VERSION "Version"

NS_ :

BS_:

BU_: Tester CCU INU ADC RRR RLR CCURT1 CCURT2 ZCUF ZCUL ZCUR ZCUT EMS IDM DCDC DCDCI IPS NIDU DCU2 OBC OPC LPC CPC EMCM GCU DCU IPU BMS EOP EVCC DCDC2 EDL SRS ECS EPS EPB RBM IBCS ICM IID IDC AMP WHUD ARHUD IMR FIMR CD IFC FAPA PAS PCS SCMF SCMR SCMRL SCMRR MFS DRM FCP RCP LBMSAD AVAS DLPFL FBLCM FLISD FLLCM FRLCM RLLCMA RLLCMB RRLCMA RRLCMB RLISD DLPML DLPMR TRM PSDL PSDR FLDCM FRDCM HVSPRL HVSPRR RFR SBM WCM ETC TBOX2 TBOX RLBMS EBU FLPDM RLPDM FRPDM RRPDM FLOAR FROAR RLOAR RROAR EOSL EOSR EOST PRBU RT1_C0 OTAWL RT2_C3 IDUR PHUDD RAS CBM PLGM TMC LPC2 SAS RCICP SCMRM SCMT SLMRL SLMRR IDU RRISD DSASBM LBMS RT1_C1

BO_ 696 CCU_ZCUR_SBM_5: 64 CCU
 SG_ SBM_5_CRC : 7|16@0+ (1,0) [0|65535] ""  OTAWL,ADC,FAPA
 SG_ SBM_5_Counter : 23|8@0+ (1,0) [0|255] ""  OTAWL,ADC,FAPA
 SG_ KAE_EDK1UnlockBtnPressSt : 31|2@0+ (1,0) [0|3] ""  OTAWL,ADC,FAPA
 SG_ KAE_EDK1LockBtnPressSt : 29|2@0+ (1,0) [0|3] ""  OTAWL,ADC,FAPA
 SG_ KAE_EDK1RESBtnPressSt : 27|2@0+ (1,0) [0|3] ""  OTAWL,ADC,FAPA
 SG_ KAE_EDK1PSD_LBtnPressSt : 25|2@0+ (1,0) [0|3] ""  OTAWL,ADC,FAPA
 SG_ KAE_EDK1PSD_RBtnPressSt : 39|2@0+ (1,0) [0|3] ""  OTAWL,ADC,FAPA
 SG_ KAE_EDK1TrunkBtnPressSt : 37|2@0+ (1,0) [0|3] ""  OTAWL,ADC,FAPA
 SG_ KAE_EDK1PanicBtnPressSt : 35|2@0+ (1,0) [0|3] ""  OTAWL,ADC,FAPA
 SG_ KAE_EDK1User_definedBtnPressSt : 33|2@0+ (1,0) [0|3] ""  OTAWL,ADC,FAPA
 SG_ KAE_EDK2UnlockBtnPressSt : 47|2@0+ (1,0) [0|3] ""  OTAWL,ADC,FAPA
 SG_ KAE_EDK2LockBtnPressSt : 45|2@0+ (1,0) [0|3] ""  OTAWL,ADC,FAPA
 SG_ KAE_EDK2RESBtnPressSt : 43|2@0+ (1,0) [0|3] ""  OTAWL,ADC,FAPA
 SG_ KAE_EDK2PSD_LBtnPressSt : 41|2@0+ (1,0) [0|3] ""  OTAWL,ADC,FAPA
 SG_ KAE_EDK2PSD_RBtnPressSt : 55|2@0+ (1,0) [0|3] ""  OTAWL,ADC,FAPA
 SG_ KAE_EDK2TrunkBtnPressSt : 53|2@0+ (1,0) [0|3] ""  OTAWL,ADC,FAPA
 SG_ KAE_EDK2PanicBtnPressSt : 51|2@0+ (1,0) [0|3] ""  OTAWL,ADC,FAPA
 SG_ KAE_EDK2User_definedBtnPressSt : 49|2@0+ (1,0) [0|3] ""  OTAWL,ADC,FAPA
 SG_ KAE_EDK3UnlockBtnPressSt : 63|2@0+ (1,0) [0|3] ""  OTAWL,ADC,FAPA
 SG_ KAE_EDK3LockBtnPressSt : 61|2@0+ (1,0) [0|3] ""  OTAWL,ADC,FAPA
 SG_ KAE_EDK3RESBtnPressSt : 59|2@0+ (1,0) [0|3] ""  OTAWL,ADC,FAPA
 SG_ KAE_EDK3PSD_LBtnPressSt : 57|2@0+ (1,0) [0|3] ""  OTAWL,ADC,FAPA
 SG_ KAE_EDK3PSD_RBtnPressSt : 71|2@0+ (1,0) [0|3] ""  OTAWL,ADC,FAPA
 SG_ KAE_EDK3TrunkBtnPressSt : 69|2@0+ (1,0) [0|3] ""  OTAWL,ADC,FAPA
 SG_ KAE_EDK3PanicBtnPressSt : 67|2@0+ (1,0) [0|3] ""  OTAWL,ADC,FAPA
 SG_ KAE_EDK3User_definedBtnPressSt : 65|2@0+ (1,0) [0|3] ""  OTAWL,ADC,FAPA
 SG_ KAE_RPADirectionSel : 79|3@0+ (1,0) [0|7] ""  OTAWL,ADC,FAPA
 SG_ KAE_RPAmode : 76|2@0+ (1,0) [0|3] ""  OTAWL,ADC,FAPA
 SG_ KAE_RPADeviceSt : 74|3@0+ (1,0) [0|7] ""  OTAWL,ADC,FAPA
 SG_ KAE_PhoneBatt : 87|8@0+ (1,0) [0|100] ""  OTAWL,ADC,FAPA
 SG_ KAE_RPACheckReq : 95|1@0+ (1,0) [0|1] ""  OTAWL,ADC,FAPA
 SG_ KAE_RPAKeyPstSt : 94|2@0+ (1,0) [0|3] ""  OTAWL,ADC,FAPA
 SG_ KAE_RPADeviceFailReason : 92|4@0+ (1,0) [0|15] ""  OTAWL,ADC,FAPA
 SG_ KAE_RPABtnSt : 88|1@0+ (1,0) [0|1] ""  OTAWL,ADC,FAPA
 SG_ KAE_ForRPAFailReason : 103|4@0+ (1,0) [0|15] ""  OTAWL,ADC,FAPA
 SG_ KAE_RPABtnStVD : 99|1@0+ (1,0) [0|1] ""  OTAWL,ADC,FAPA
 SG_ KAE_RPACancelBtnSt : 98|1@0+ (1,0) [0|1] ""  OTAWL,ADC,FAPA
 SG_ KAE_RPACancelBtnStVD : 97|1@0+ (1,0) [0|1] ""  OTAWL,ADC,FAPA
 SG_ KAE_ComSDKUBouncesSt : 96|1@0+ (1,0) [0|1] ""  OTAWL,ADC,FAPA
 SG_ KAE_HAVPCancelParking : 111|1@0+ (1,0) [0|1] ""  OTAWL,ADC,FAPA
 SG_ KAE_HAVPDisclaimerAgree : 110|2@0+ (1,0) [0|3] ""  OTAWL,ADC,FAPA
 SG_ KAE_HAVPPathSelect : 108|4@0+ (1,0) [0|15] ""  OTAWL,ADC,FAPA
 SG_ KAE_RPAResponse : 119|8@0+ (1,0) [0|255] ""  OTAWL,ADC,FAPA
 SG_ KAE_HAVPUWBZone : 127|4@0+ (1,0) [0|15] ""  OTAWL,ADC,FAPA
 SG_ KAE_HAVPUWBXPosition : 123|12@0+ (1,0) [0|4095] ""  OTAWL,ADC,FAPA
 SG_ KAE_HAVPUWBYPosition : 143|12@0+ (1,0) [0|4095] ""  OTAWL,ADC,FAPA
 SG_ KAE_UnlockDoorReq : 147|1@0+ (1,0) [0|1] ""  OTAWL,ADC,FAPA
 SG_ KAE_UnlockDoorReqVD : 146|1@0+ (1,0) [0|1] ""  OTAWL,ADC,FAPA
 SG_ KAE_LockDoorReq : 145|1@0+ (1,0) [0|1] ""  OTAWL,ADC,FAPA
 SG_ KAE_LockDoorReqVD : 144|1@0+ (1,0) [0|1] ""  OTAWL,ADC,FAPA
 SG_ KAE_WindowsCloseReq : 159|1@0+ (1,0) [0|1] ""  OTAWL,ADC,FAPA
 SG_ KAE_WindowsCloseReqVD : 158|1@0+ (1,0) [0|1] ""  OTAWL,ADC,FAPA
 SG_ KAE_WindowsOpenReq : 157|1@0+ (1,0) [0|1] ""  OTAWL,ADC,FAPA
 SG_ KAE_WindowsOpenReqVD : 156|1@0+ (1,0) [0|1] ""  OTAWL,ADC,FAPA
 SG_ KAE_TrunkUnlockReq : 155|1@0+ (1,0) [0|1] ""  OTAWL,ADC,FAPA
 SG_ KAE_TrunkUnlockReqVD : 154|1@0+ (1,0) [0|1] ""  OTAWL,ADC,FAPA
 SG_ KAE_HoodUnlockReq : 153|1@0+ (1,0) [0|1] ""  OTAWL,ADC,FAPA
 SG_ KAE_HoodUnlockReqVD : 152|1@0+ (1,0) [0|1] ""  OTAWL,ADC,FAPA
 SG_ KAE_PLGMOpenReq : 167|1@0+ (1,0) [0|1] ""  OTAWL,ADC,FAPA
 SG_ KAE_PLGMOpenReqVD : 166|1@0+ (1,0) [0|1] ""  OTAWL,ADC,FAPA
 SG_ KAE_PLGMCloseReq : 165|1@0+ (1,0) [0|1] ""  OTAWL,ADC,FAPA
 SG_ KAE_PLGMCloseReqVD : 164|1@0+ (1,0) [0|1] ""  OTAWL,ADC,FAPA
 SG_ KAE_SunRoofOpenReq : 163|1@0+ (1,0) [0|1] ""  OTAWL,ADC,FAPA
 SG_ KAE_SunRoofOpenReqVD : 162|1@0+ (1,0) [0|1] ""  OTAWL,ADC,FAPA
 SG_ KAE_SunRoofCloseReq : 161|1@0+ (1,0) [0|1] ""  OTAWL,ADC,FAPA
 SG_ KAE_SunRoofCloseReqVD : 160|1@0+ (1,0) [0|1] ""  OTAWL,ADC,FAPA
 SG_ KAE_PAAReq : 287|4@0+ (1,0) [0|15] ""  OTAWL,ADC,FAPA
 SG_ KAE_PAAReqVd : 283|1@0+ (1,0) [0|1] ""  OTAWL,ADC,FAPA
 SG_ KAE_EDK1UnlockBtnSt : 282|1@0+ (1,0) [0|1] ""  OTAWL,ADC,FAPA
 SG_ KAE_EDK1LockBtnSt : 281|1@0+ (1,0) [0|1] ""  OTAWL,ADC,FAPA
 SG_ KAE_EDK1RESBtnSt : 280|1@0+ (1,0) [0|1] ""  OTAWL,ADC,FAPA
 SG_ KAE_EDK1PSD_LBtnSt : 295|1@0+ (1,0) [0|1] ""  OTAWL,ADC,FAPA
 SG_ KAE_EDK1PSD_RBtnSt : 294|1@0+ (1,0) [0|1] ""  OTAWL,ADC,FAPA
 SG_ KAE_EDK1TrunkBtnSt : 293|1@0+ (1,0) [0|1] ""  OTAWL,ADC,FAPA
 SG_ KAE_EDK1PanicBtnSt : 292|1@0+ (1,0) [0|1] ""  OTAWL,ADC,FAPA
 SG_ KAE_EDK1User_definedBtnSt : 291|1@0+ (1,0) [0|1] ""  OTAWL,ADC,FAPA
 SG_ KAE_EDK2UnlockBtnSt : 290|1@0+ (1,0) [0|1] ""  OTAWL,ADC,FAPA
 SG_ KAE_EDK2LockBtnSt : 289|1@0+ (1,0) [0|1] ""  OTAWL,ADC,FAPA
 SG_ KAE_EDK2RESBtnSt : 288|1@0+ (1,0) [0|1] ""  OTAWL,ADC,FAPA
 SG_ KAE_EDK2PSD_LBtnSt : 303|1@0+ (1,0) [0|1] ""  OTAWL,ADC,FAPA
 SG_ KAE_EDK2PSD_RBtnSt : 302|1@0+ (1,0) [0|1] ""  OTAWL,ADC,FAPA
 SG_ KAE_EDK2TrunkBtnSt : 301|1@0+ (1,0) [0|1] ""  OTAWL,ADC,FAPA
 SG_ KAE_EDK2PanicBtnSt : 300|1@0+ (1,0) [0|1] ""  OTAWL,ADC,FAPA
 SG_ KAE_EDK2User_definedBtnSt : 299|1@0+ (1,0) [0|1] ""  OTAWL,ADC,FAPA
 SG_ KAE_EDK3UnlockBtnSt : 298|1@0+ (1,0) [0|1] ""  OTAWL,ADC,FAPA
 SG_ KAE_EDK3LockBtnSt : 297|1@0+ (1,0) [0|1] ""  OTAWL,ADC,FAPA
 SG_ KAE_EDK3RESBtnSt : 296|1@0+ (1,0) [0|1] ""  OTAWL,ADC,FAPA
 SG_ KAE_EDK3PSD_LBtnSt : 311|1@0+ (1,0) [0|1] ""  OTAWL,ADC,FAPA
 SG_ KAE_EDK3PSD_RBtnSt : 310|1@0+ (1,0) [0|1] ""  OTAWL,ADC,FAPA
 SG_ KAE_EDK3TrunkBtnSt : 309|1@0+ (1,0) [0|1] ""  OTAWL,ADC,FAPA
 SG_ KAE_EDK3PanicBtnSt : 308|1@0+ (1,0) [0|1] ""  OTAWL,ADC,FAPA
 SG_ KAE_EDK3User_definedBtnSt : 316|1@0+ (1,0) [0|1] ""  OTAWL,ADC,FAPA

BO_ 1934 ADC_Diag_Tx: 64 ADC
 SG_ ADC_Diag_Response : 7|512@0+ (1,0) [0|0] ""  Vector__XXX

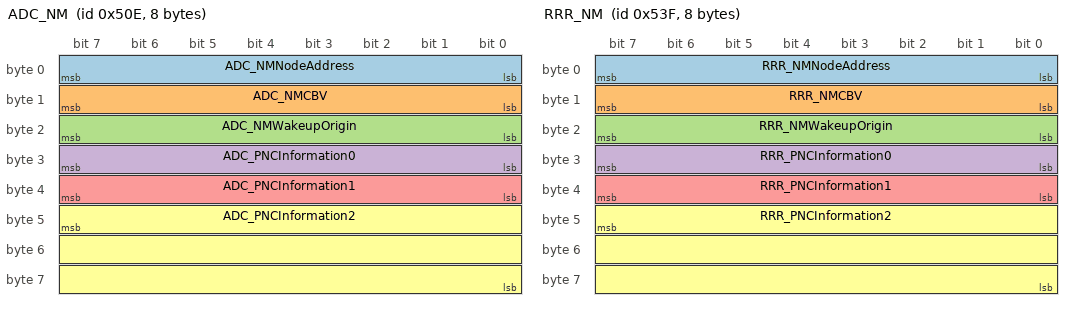
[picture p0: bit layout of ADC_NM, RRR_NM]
BO_ 1294 ADC_NM: 8 ADC
 SG_ ADC_NMNodeAddress : 7|8@0+ (1,0) [0|255] ""  CCU,CCURT1
 SG_ ADC_NMCBV : 15|8@0+ (1,0) [0|0] ""  CCU,CCURT1
 SG_ ADC_NMWakeupOrigin : 23|8@0+ (1,0) [0|255] ""  CCU,CCURT1
 SG_ ADC_PNCInformation0 : 31|8@0+ (1,0) [0|255] ""  CCU,CCURT1
 SG_ ADC_PNCInformation1 : 39|8@0+ (1,0) [0|255] ""  CCU,CCURT1
 SG_ ADC_PNCInformation2 : 47|24@0+ (1,0) [0|0] ""  CCU,CCURT1

BO_ 1343 RRR_NM: 8 RRR
 SG_ RRR_NMNodeAddress : 7|8@0+ (1,0) [0|255] ""  CCU,ADC,RLR
 SG_ RRR_NMCBV : 15|8@0+ (1,0) [0|0] ""  CCU,ADC,RLR
 SG_ RRR_NMWakeupOrigin : 23|8@0+ (1,0) [0|255] ""  CCU,ADC,RLR
 SG_ RRR_PNCInformation0 : 31|8@0+ (1,0) [0|255] ""  CCU,ADC,RLR
 SG_ RRR_PNCInformation1 : 39|8@0+ (1,0) [0|255] ""  CCU,ADC,RLR
 SG_ RRR_PNCInformation2 : 47|24@0+ (1,0) [0|0] ""  CCU,ADC,RLR

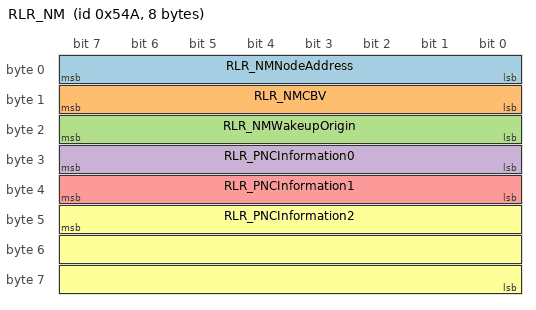
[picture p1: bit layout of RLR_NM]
BO_ 1354 RLR_NM: 8 RLR
 SG_ RLR_NMNodeAddress : 7|8@0+ (1,0) [0|255] ""  CCU,ADC,RRR
 SG_ RLR_NMCBV : 15|8@0+ (1,0) [0|0] ""  CCU,ADC,RRR
 SG_ RLR_NMWakeupOrigin : 23|8@0+ (1,0) [0|255] ""  CCU,ADC,RRR
 SG_ RLR_PNCInformation0 : 31|8@0+ (1,0) [0|255] ""  CCU,ADC,RRR
 SG_ RLR_PNCInformation1 : 39|8@0+ (1,0) [0|255] ""  CCU,ADC,RRR
 SG_ RLR_PNCInformation2 : 47|24@0+ (1,0) [0|0] ""  CCU,ADC,RRR

BO_ 932 RRR_1: 32 RRR
 SG_ RRR_1_CRC : 7|16@0+ (1,0) [0|65535] ""  ADC,IFC,FAPA
 SG_ RRR_1_Counter : 23|8@0+ (1,0) [0|255] ""  ADC,IFC,FAPA
 SG_ RRR_MRRSt : 31|3@0+ (1,0) [0|7] ""  ADC,IFC,FAPA
 SG_ RRR_ExMirLedWarnR : 28|2@0+ (1,0) [0|3] ""  ADC,IFC,FAPA
 SG_ RRR_LCASt : 26|2@0+ (1,0) [0|3] ""  ADC,IFC,FAPA
 SG_ RRR_LCAWarnRight : 24|2@0+ (1,0) [0|3] ""  ADC,IFC,FAPA
 SG_ RRR_ClusterLamp : 38|3@0+ (1,0) [0|7] ""  ADC,IFC,FAPA
 SG_ RRR_DOWWarnR : 35|2@0+ (1,0) [0|3] ""  ADC,IFC,FAPA
 SG_ RRR_DOWSt : 33|2@0+ (1,0) [0|3] ""  ADC,IFC,FAPA
 SG_ RRR_AudioWarnFR : 41|2@0+ (1,0) [0|3] ""  ADC,IFC,FAPA
 SG_ RRR_AudioWarnRR : 43|2@0+ (1,0) [0|3] ""  ADC,IFC,FAPA
 SG_ RRR_IALWarnFR : 45|2@0+ (1,0) [0|3] ""  ADC,IFC,FAPA
 SG_ RRR_IALWarnRR : 47|2@0+ (1,0) [0|3] ""  ADC,IFC,FAPA
 SG_ RRR_RCTASt : 49|2@0+ (1,0) [0|3] ""  ADC,IFC,FAPA
 SG_ RRR_RCTAWarnRight : 51|2@0+ (1,0) [0|3] ""  ADC,IFC,FAPA
 SG_ RRR_RCWSt : 53|2@0+ (1,0) [0|3] ""  ADC,IFC,FAPA
 SG_ RRR_RCWWarn : 55|2@0+ (1,0) [0|3] ""  ADC,IFC,FAPA
 SG_ RRR_RCTBTargetDecel : 63|8@0+ (0.05,-10) [-10|2.75] "m/s2"  ADC,IFC,FAPA
 SG_ RRR_RCTBBrkReq : 64|1@0+ (1,0) [0|1] ""  ADC,IFC,FAPA
 SG_ RRR_TargetLatDistR : 71|7@0+ (0.1,-12.7) [-12.7|0] ""  ADC,IFC,FAPA
 SG_ RRR_TargetRelSpdR : 79|10@0+ (0.06225,-10) [-10|50] "m/s"  ADC,IFC,FAPA
 SG_ RRR_RCTBBrkgVD : 83|1@0+ (1,0) [0|1] ""  ADC,IFC,FAPA
 SG_ RRR_TargetRVD : 85|2@0+ (1,0) [0|3] ""  ADC,IFC,FAPA
 SG_ RRR_TargetDstR : 82|11@0+ (0.06225,-90) [-90|10] "m"  ADC,IFC,FAPA
 SG_ RRR_RCTAAssistType : 103|2@0+ (1,0) [0|3] ""  ADC,IFC,FAPA

BO_ 987 RLR_1: 32 RLR
 SG_ RLR_1_CRC : 7|16@0+ (1,0) [0|65535] ""  ADC,IFC,FAPA
 SG_ RLR_1_Counter : 23|8@0+ (1,0) [0|255] ""  ADC,IFC,FAPA
 SG_ RLR_MRRSt : 31|3@0+ (1,0) [0|7] ""  ADC,IFC,FAPA
 SG_ RLR_ExMirLedWarnL : 28|2@0+ (1,0) [0|3] ""  ADC,IFC,FAPA
 SG_ RLR_LCASt : 26|2@0+ (1,0) [0|3] ""  ADC,IFC,FAPA
 SG_ RLR_LCAWarnLeft : 24|2@0+ (1,0) [0|3] ""  ADC,IFC,FAPA
 SG_ RLR_ClusterLamp : 38|3@0+ (1,0) [0|7] ""  ADC,IFC,FAPA
 SG_ RLR_DOWWarnL : 35|2@0+ (1,0) [0|3] ""  ADC,IFC,FAPA
 SG_ RLR_DOWSt : 33|2@0+ (1,0) [0|3] ""  ADC,IFC,FAPA
 SG_ RLR_AudioWarnFL : 41|2@0+ (1,0) [0|3] ""  ADC,IFC,FAPA
 SG_ RLR_AudioWarnRL : 43|2@0+ (1,0) [0|3] ""  ADC,IFC,FAPA
 SG_ RLR_IALWarnFL : 45|2@0+ (1,0) [0|3] ""  ADC,IFC,FAPA
 SG_ RLR_IALWarnRL : 47|2@0+ (1,0) [0|3] ""  ADC,IFC,FAPA
 SG_ RLR_RCTAWarnLeft : 49|2@0+ (1,0) [0|3] ""  ADC,IFC,FAPA
 SG_ RLR_RCWSt : 51|2@0+ (1,0) [0|3] ""  ADC,IFC,FAPA
 SG_ RLR_RCWWarn : 53|2@0+ (1,0) [0|3] ""  ADC,IFC,FAPA,RRR
 SG_ RLR_TargetLVD : 55|2@0+ (1,0) [0|3] ""  ADC,IFC,FAPA
 SG_ RLR_TargetRelSpdL : 63|10@0+ (0.06225,-10) [-10|50] "m/s"  ADC,IFC,FAPA
 SG_ RLR_TargetDstL : 69|11@0+ (0.06225,-90) [-90|10] "m"  ADC,IFC,FAPA
 SG_ RLR_TargetLatDistL : 74|7@0+ (0.1,0) [0|12.7] "m"  ADC,IFC,FAPA
 SG_ RLR_RCTASt : 83|2@0+ (1,0) [0|3] ""  ADC,IFC,FAPA
 SG_ RLR_RCTAAssistType : 81|2@0+ (1,0) [0|3] ""  ADC,IFC,FAPA,RRR

CM_ SG_ 696 SBM_5_CRC "E2E Profile 5 CRC";
CM_ SG_ 696 SBM_5_Counter "E2E Profile 5 Counter";
CM_ SG_ 696 KAE_EDK1UnlockBtnPressSt "EDK Unlock Button Pressed Status";
CM_ SG_ 696 KAE_EDK1LockBtnPressSt "EDK Lock Button Pressed Status";
CM_ SG_ 696 KAE_EDK1RESBtnPressSt "EDK RES Button Status";
CM_ SG_ 696 KAE_EDK1PSD_LBtnPressSt "EDK PSD_L Button Status";
CM_ SG_ 696 KAE_EDK1PSD_RBtnPressSt "EDK PSD_R Button Status";
CM_ SG_ 696 KAE_EDK1TrunkBtnPressSt "EDK Trunk Button Status";
CM_ SG_ 696 KAE_EDK1PanicBtnPressSt "EDK Panic Button Status";
CM_ SG_ 696 KAE_EDK1User_definedBtnPressSt "EDK User_defined Button Status";
CM_ SG_ 696 KAE_EDK2UnlockBtnPressSt "EDK Unlock Button Pressed Status";
CM_ SG_ 696 KAE_EDK2LockBtnPressSt "EDK Lock Button Pressed Status";
CM_ SG_ 696 KAE_EDK2RESBtnPressSt "EDK RES Button Status";
CM_ SG_ 696 KAE_EDK2PSD_LBtnPressSt "EDK PSD_L Button Status";
CM_ SG_ 696 KAE_EDK2PSD_RBtnPressSt "EDK PSD_R Button Status";
CM_ SG_ 696 KAE_EDK2TrunkBtnPressSt "EDK Trunk Button Status";
CM_ SG_ 696 KAE_EDK2PanicBtnPressSt "EDK Panic Button Status";
CM_ SG_ 696 KAE_EDK2User_definedBtnPressSt "EDK User_defined Button Status";
CM_ SG_ 696 KAE_EDK3UnlockBtnPressSt "EDK Unlock Button Pressed Status";
CM_ SG_ 696 KAE_EDK3LockBtnPressSt "EDK Lock Button Pressed Status";
CM_ SG_ 696 KAE_EDK3RESBtnPressSt "EDK RES Button Status";
CM_ SG_ 696 KAE_EDK3PSD_LBtnPressSt "EDK PSD_L Button Status";
CM_ SG_ 696 KAE_EDK3PSD_RBtnPressSt "EDK PSD_R Button Status";
CM_ SG_ 696 KAE_EDK3TrunkBtnPressSt "EDK Trunk Button Status";
CM_ SG_ 696 KAE_EDK3PanicBtnPressSt "EDK Panic Button Status";
CM_ SG_ 696 KAE_EDK3User_definedBtnPressSt "EDK User_defined Button Status";
CM_ SG_ 696 KAE_RPADirectionSel "RPA Direction Selection";
CM_ SG_ 696 KAE_RPAmode "SBM RPA mode";
CM_ SG_ 696 KAE_RPADeviceSt "RPA Device Status";
CM_ SG_ 696 KAE_PhoneBatt "SBM Phone batt";
CM_ SG_ 696 KAE_RPACheckReq "SBM RPA Checking Req";
CM_ SG_ 696 KAE_RPAKeyPstSt "RPA Key Position Status";
CM_ SG_ 696 KAE_RPADeviceFailReason "RPA Device Failure Reason";
CM_ SG_ 696 KAE_RPABtnSt "RPA Button Status";
CM_ SG_ 696 KAE_ForRPAFailReason "RPA and SBM failure reason";
CM_ SG_ 696 KAE_RPABtnStVD "RPA Button Status valid value";
CM_ SG_ 696 KAE_RPACancelBtnSt "RPA Cancal Button Status";
CM_ SG_ 696 KAE_RPACancelBtnStVD "RPA Button Statusvalid valid value";
CM_ SG_ 696 KAE_ComSDKUBouncesSt "Communication status between SBM and SDK,This signal bounces every time the SDK updates the data";
CM_ SG_ 696 KAE_HAVPCancelParking "HAVP User cancellation SBM";
CM_ SG_ 696 KAE_HAVPDisclaimerAgree "App HAVP Disclaimer confirm";
CM_ SG_ 696 KAE_HAVPPathSelect "HAVP User path selection SBM";
CM_ SG_ 696 KAE_RPAResponse "SBM Response RPA Challenge  Singal";
CM_ SG_ 696 KAE_HAVPUWBZone "SBM UWB HAVP Zone";
CM_ SG_ 696 KAE_HAVPUWBXPosition "SBM UWB HAVP X Position";
CM_ SG_ 696 KAE_HAVPUWBYPosition "SBM UWB HAVP Y Position";
CM_ SG_ 696 KAE_UnlockDoorReq "Virtual Key APP Unlock door request";
CM_ SG_ 696 KAE_UnlockDoorReqVD "KAE_UnlockDoorReq valid value";
CM_ SG_ 696 KAE_LockDoorReq "Virtual Key APP Lock door request";
CM_ SG_ 696 KAE_LockDoorReqVD "KAE_LockDoorReq valid value";
CM_ SG_ 696 KAE_WindowsCloseReq "Virtual Key APP close the windows request";
CM_ SG_ 696 KAE_WindowsCloseReqVD "KAE_WindowsCloseReq valid value";
CM_ SG_ 696 KAE_WindowsOpenReq "Virtual Key APP open the windows request";
CM_ SG_ 696 KAE_WindowsOpenReqVD "KAE_WindowsOpenReq valid value";
CM_ SG_ 696 KAE_TrunkUnlockReq "Virtual Key APP request unlock the trunck";
CM_ SG_ 696 KAE_TrunkUnlockReqVD "KAE_TrunkUnlockReq valid value";
CM_ SG_ 696 KAE_HoodUnlockReq "Virtual Key APP request unlock the hood";
CM_ SG_ 696 KAE_HoodUnlockReqVD "KAE_HoodeUnlockReq valid value";
CM_ SG_ 696 KAE_PLGMOpenReq "Virtual Key APP PLGM(Power Liftgate Module) open request";
CM_ SG_ 696 KAE_PLGMOpenReqVD "KAE_PLGMOpenReq valid value";
CM_ SG_ 696 KAE_PLGMCloseReq "Virtual Key APP PLGM(Power Liftgate Module) close request";
CM_ SG_ 696 KAE_PLGMCloseReqVD "KAE_PLGMCloseReq valid value";
CM_ SG_ 696 KAE_SunRoofOpenReq "Virtual Key APP sun roof open request";
CM_ SG_ 696 KAE_SunRoofOpenReqVD "KAE_SunRoofOpenReq valid value";
CM_ SG_ 696 KAE_SunRoofCloseReq "Virtual Key APP sun roof close request";
CM_ SG_ 696 KAE_SunRoofCloseReqVD "KAE_SunRoofCloseReq valid value";
CM_ SG_ 696 KAE_PAAReq "KAE PAA request";
CM_ SG_ 696 KAE_PAAReqVd "KAE_PAA Req valid value";
CM_ SG_ 696 KAE_EDK1UnlockBtnSt "EDK1 Unlock Button current Status";
CM_ SG_ 696 KAE_EDK1LockBtnSt "EDK1 Lock Button current Status";
CM_ SG_ 696 KAE_EDK1RESBtnSt "EDK1 RES Button  current Status";
CM_ SG_ 696 KAE_EDK1PSD_LBtnSt "EDK1 PSD_L Button current Status";
CM_ SG_ 696 KAE_EDK1PSD_RBtnSt "EDK1 PSD_R Button current Status";
CM_ SG_ 696 KAE_EDK1TrunkBtnSt "EDK1 Trunk Button current Status";
CM_ SG_ 696 KAE_EDK1PanicBtnSt "EDK1 Panic Button current Status";
CM_ SG_ 696 KAE_EDK1User_definedBtnSt "EDK1 User_defined Button current Status";
CM_ SG_ 696 KAE_EDK2UnlockBtnSt "EDK2 Unlock Button current Status";
CM_ SG_ 696 KAE_EDK2LockBtnSt "EDK2 Lock Button current Status";
CM_ SG_ 696 KAE_EDK2RESBtnSt "EDK2 RES Button  current Status";
CM_ SG_ 696 KAE_EDK2PSD_LBtnSt "EDK2 PSD_L Button current Status";
CM_ SG_ 696 KAE_EDK2PSD_RBtnSt "EDK2 PSD_R Button current Status";
CM_ SG_ 696 KAE_EDK2TrunkBtnSt "EDK2 Trunk Button current Status";
CM_ SG_ 696 KAE_EDK2PanicBtnSt "EDK2 Panic Button current Status";
CM_ SG_ 696 KAE_EDK2User_definedBtnSt "EDK2 User_defined Button current Status";
CM_ SG_ 696 KAE_EDK3UnlockBtnSt "EDK3 Unlock Button current Status";
CM_ SG_ 696 KAE_EDK3LockBtnSt "EDK3 Lock Button current Status";
CM_ SG_ 696 KAE_EDK3RESBtnSt "EDK3 RES Button  current Status";
CM_ SG_ 696 KAE_EDK3PSD_LBtnSt "EDK3 PSD_L Button current Status";
CM_ SG_ 696 KAE_EDK3PSD_RBtnSt "EDK3 PSD_R Button current Status";
CM_ SG_ 696 KAE_EDK3TrunkBtnSt "EDK3 Trunk Button current Status";
CM_ SG_ 696 KAE_EDK3PanicBtnSt "EDK3 Panic Button current Status";
CM_ SG_ 696 KAE_EDK3User_definedBtnSt "EDK3 User_defined Button current Status";
CM_ SG_ 1934 ADC_Diag_Response "ADC diagnostic response";
CM_ SG_ 1294 ADC_NMNodeAddress "ADC node address";
CM_ SG_ 1294 ADC_NMCBV "ADC Network management control bit vector";
CM_ SG_ 1294 ADC_NMWakeupOrigin "Origin of the wake up";
CM_ SG_ 1294 ADC_PNCInformation0 "PNC Information";
CM_ SG_ 1294 ADC_PNCInformation1 "PNC Information";
CM_ SG_ 1294 ADC_PNCInformation2 "PNC Information";
CM_ SG_ 1343 RRR_NMNodeAddress "RRR node address";
CM_ SG_ 1343 RRR_NMCBV "RRR Network management control bit vector";
CM_ SG_ 1343 RRR_NMWakeupOrigin "Origin of the wake up";
CM_ SG_ 1343 RRR_PNCInformation0 "PNC Information";
CM_ SG_ 1343 RRR_PNCInformation1 "PNC Information";
CM_ SG_ 1343 RRR_PNCInformation2 "PNC Information";
CM_ SG_ 1354 RLR_NMNodeAddress "RLR node address";
CM_ SG_ 1354 RLR_NMCBV "RLR Network management control bit vector";
CM_ SG_ 1354 RLR_NMWakeupOrigin "Origin of the wake up";
CM_ SG_ 1354 RLR_PNCInformation0 "PNC Information";
CM_ SG_ 1354 RLR_PNCInformation1 "PNC Information";
CM_ SG_ 1354 RLR_PNCInformation2 "PNC Information";
CM_ SG_ 932 RRR_1_CRC "E2E Profile 5 CRC";
CM_ SG_ 932 RRR_1_Counter "E2E Profile 5 Counter";
CM_ SG_ 932 RRR_MRRSt "MRR systems ON OFF andError Status";
CM_ SG_ 932 RRR_ExMirLedWarnR "Exterior mirror LED warning right";
CM_ SG_ 932 RRR_LCASt "BSD-LCA Function status";
CM_ SG_ 932 RRR_LCAWarnRight " the vehicle right warning level in the LCA feature";
CM_ SG_ 932 RRR_ClusterLamp "Cluster lamp color status";
CM_ SG_ 932 RRR_DOWWarnR "DOW warning right";
CM_ SG_ 932 RRR_DOWSt "DOW function state  right";
CM_ SG_ 932 RRR_AudioWarnFR "Front right door speaker warning";
CM_ SG_ 932 RRR_AudioWarnRR "Rear right door speaker warning";
CM_ SG_ 932 RRR_IALWarnFR "Front right door light warning";
CM_ SG_ 932 RRR_IALWarnRR "Rear right door light warning";
CM_ SG_ 932 RRR_RCTASt "RCTA Function status";
CM_ SG_ 932 RRR_RCTAWarnRight "the vehicle right warning in the RCTAfeature";
CM_ SG_ 932 RRR_RCWSt "RCW(rear collision warning ) feature status";
CM_ SG_ 932 RRR_RCWWarn "the vehicle warning level in the RCWfeature";
CM_ SG_ 932 RRR_RCTBTargetDecel "target deceleration value from RCTB";
CM_ SG_ 932 RRR_RCTBBrkReq "RCTB brake request";
CM_ SG_ 932 RRR_TargetLatDistR "ELK right target lateral relative distance";
CM_ SG_ 932 RRR_TargetRelSpdR "ELK right target relative speed";
CM_ SG_ 932 RRR_RCTBBrkgVD "RCTB brake request valid flag";
CM_ SG_ 932 RRR_TargetRVD "ELK right target valid state";
CM_ SG_ 932 RRR_TargetDstR "ELK right target relative distance";
CM_ SG_ 932 RRR_RCTAAssistType "RCTA assist type request";
CM_ SG_ 987 RLR_1_CRC "E2E Profile 5 CRC";
CM_ SG_ 987 RLR_1_Counter "E2E Profile 5 Counter";
CM_ SG_ 987 RLR_MRRSt "MRR systems ON OFF andError Status";
CM_ SG_ 987 RLR_ExMirLedWarnL "Exterior mirror LED warning left";
CM_ SG_ 987 RLR_LCASt "BSD-LCA Function status";
CM_ SG_ 987 RLR_LCAWarnLeft " the vehicle Left warning level in the LCA feature";
CM_ SG_ 987 RLR_ClusterLamp "Cluster lamp color status";
CM_ SG_ 987 RLR_DOWWarnL "DOW warning left";
CM_ SG_ 987 RLR_DOWSt "DOW function state left";
CM_ SG_ 987 RLR_AudioWarnFL "Front left door speaker warning";
CM_ SG_ 987 RLR_AudioWarnRL "Rear left door speaker warning";
CM_ SG_ 987 RLR_IALWarnFL "Front left door light warning";
CM_ SG_ 987 RLR_IALWarnRL "Rear left door light warning";
CM_ SG_ 987 RLR_RCTAWarnLeft "the vehicle left warning in the RCTAfeature";
CM_ SG_ 987 RLR_RCWSt "RCW(rear collision warning ) feature status";
CM_ SG_ 987 RLR_RCWWarn "the vehicle warning level in the RCWfeature";
CM_ SG_ 987 RLR_TargetLVD "ELK left target valid state";
CM_ SG_ 987 RLR_TargetRelSpdL "ELK left target relative speed";
CM_ SG_ 987 RLR_TargetDstL "ELK left target relative distance";
CM_ SG_ 987 RLR_TargetLatDistL "ELK left target lateral relative distance ";
CM_ SG_ 987 RLR_RCTASt "RCTA Function status left";
CM_ SG_ 987 RLR_RCTAAssistType "RCTA assist type request";

BA_DEF_ BO_  "GenMsgCycleTime" INT 0 0;
BA_DEF_ BO_  "GenMsgCycleTimeFast" INT 0 0;
BA_DEF_ BO_  "GenMsgSendType" ENUM  "Periodic","Event","IfActive","POE","PA","FixedPeriodic","Event","EnabledPeriodic","NotUsed","NotUsed","EventPeriodic","NotUsed","NotUsed","NoMsgSendType";
BA_DEF_ BO_  "VFrameFormat" ENUM  "StandardCAN","ExtendedCAN","reserved","reserved","reserved","reserved","reserved","reserved","reserved","reserved","reserved","reserved","reserved","reserved","StandardCAN_FD","ExtendedCAN_FD";
BA_DEF_ BO_  "CANFD_BRS" ENUM  "0","1";
BA_DEF_ SG_  "EventCommandSignal" ENUM  "No","Yes";
BA_DEF_ SG_  "GatewayedSignals" ENUM  "No","Yes";
BA_DEF_ SG_  "GenSigInactiveValue" HEX 0 0;
BA_DEF_ SG_  "GenSigInvalidValue" HEX 0 0;
BA_DEF_ SG_  "GenSigSendType" ENUM  "Trigger","Passive","Cyclic","OnWrite","OnWriteWithRepetition","OnChange","OnChangeWithRepetition","IfActive","IfActiveWithRepetition","NoSigSendType";
BA_DEF_ SG_  "GenSigStartValue" HEX 0 0;
BA_DEF_ SG_  "GenSigTimeoutValue" HEX 0 0;
BA_DEF_ SG_  "Remark" STRING ;
BA_ "GenMsgCycleTime" BO_ 696 40;
BA_ "GenMsgCycleTimeFast" BO_ 696 0;
BA_ "GenMsgSendType" BO_ 696 0;
BA_ "VFrameFormat" BO_ 696 14;
BA_ "CANFD_BRS" BO_ 696 1;
BA_ "GenMsgCycleTime" BO_ 696 40;
BA_ "GenMsgCycleTimeFast" BO_ 696 0;
BA_ "GenMsgSendType" BO_ 696 0;
BA_ "VFrameFormat" BO_ 696 14;
BA_ "CANFD_BRS" BO_ 696 1;
BA_ "GenMsgCycleTime" BO_ 696 40;
BA_ "GenMsgCycleTimeFast" BO_ 696 0;
BA_ "GenMsgSendType" BO_ 696 0;
BA_ "VFrameFormat" BO_ 696 14;
BA_ "CANFD_BRS" BO_ 696 1;
BA_ "GenMsgCycleTime" BO_ 696 40;
BA_ "GenMsgCycleTimeFast" BO_ 696 0;
BA_ "GenMsgSendType" BO_ 696 0;
BA_ "VFrameFormat" BO_ 696 14;
BA_ "CANFD_BRS" BO_ 696 1;
BA_ "GenMsgCycleTime" BO_ 696 40;
BA_ "GenMsgCycleTimeFast" BO_ 696 0;
BA_ "GenMsgSendType" BO_ 696 0;
BA_ "VFrameFormat" BO_ 696 14;
BA_ "CANFD_BRS" BO_ 696 1;
BA_ "GenMsgCycleTime" BO_ 696 40;
BA_ "GenMsgCycleTimeFast" BO_ 696 0;
BA_ "GenMsgSendType" BO_ 696 0;
BA_ "VFrameFormat" BO_ 696 14;
BA_ "CANFD_BRS" BO_ 696 1;
BA_ "GenMsgCycleTime" BO_ 696 40;
BA_ "GenMsgCycleTimeFast" BO_ 696 0;
BA_ "GenMsgSendType" BO_ 696 0;
BA_ "VFrameFormat" BO_ 696 14;
BA_ "CANFD_BRS" BO_ 696 1;
BA_ "GenMsgCycleTime" BO_ 696 40;
BA_ "GenMsgCycleTimeFast" BO_ 696 0;
BA_ "GenMsgSendType" BO_ 696 0;
BA_ "VFrameFormat" BO_ 696 14;
BA_ "CANFD_BRS" BO_ 696 1;
BA_ "GenMsgCycleTime" BO_ 696 40;
BA_ "GenMsgCycleTimeFast" BO_ 696 0;
BA_ "GenMsgSendType" BO_ 696 0;
BA_ "VFrameFormat" BO_ 696 14;
BA_ "CANFD_BRS" BO_ 696 1;
BA_ "GenMsgCycleTime" BO_ 696 40;
BA_ "GenMsgCycleTimeFast" BO_ 696 0;
BA_ "GenMsgSendType" BO_ 696 0;
BA_ "VFrameFormat" BO_ 696 14;
BA_ "CANFD_BRS" BO_ 696 1;
BA_ "GenMsgCycleTime" BO_ 696 40;
BA_ "GenMsgCycleTimeFast" BO_ 696 0;
BA_ "GenMsgSendType" BO_ 696 0;
BA_ "VFrameFormat" BO_ 696 14;
BA_ "CANFD_BRS" BO_ 696 1;
BA_ "GenMsgCycleTime" BO_ 696 40;
BA_ "GenMsgCycleTimeFast" BO_ 696 0;
BA_ "GenMsgSendType" BO_ 696 0;
BA_ "VFrameFormat" BO_ 696 14;
BA_ "CANFD_BRS" BO_ 696 1;
BA_ "GenMsgCycleTime" BO_ 696 40;
BA_ "GenMsgCycleTimeFast" BO_ 696 0;
BA_ "GenMsgSendType" BO_ 696 0;
BA_ "VFrameFormat" BO_ 696 14;
BA_ "CANFD_BRS" BO_ 696 1;
BA_ "GenMsgCycleTime" BO_ 696 40;
BA_ "GenMsgCycleTimeFast" BO_ 696 0;
BA_ "GenMsgSendType" BO_ 696 0;
BA_ "VFrameFormat" BO_ 696 14;
BA_ "CANFD_BRS" BO_ 696 1;
BA_ "GenMsgCycleTime" BO_ 696 40;
BA_ "GenMsgCycleTimeFast" BO_ 696 0;
BA_ "GenMsgSendType" BO_ 696 0;
BA_ "VFrameFormat" BO_ 696 14;
BA_ "CANFD_BRS" BO_ 696 1;
BA_ "GenMsgCycleTime" BO_ 696 40;
BA_ "GenMsgCycleTimeFast" BO_ 696 0;
BA_ "GenMsgSendType" BO_ 696 0;
BA_ "VFrameFormat" BO_ 696 14;
BA_ "CANFD_BRS" BO_ 696 1;
BA_ "GenMsgCycleTime" BO_ 696 40;
BA_ "GenMsgCycleTimeFast" BO_ 696 0;
BA_ "GenMsgSendType" BO_ 696 0;
BA_ "VFrameFormat" BO_ 696 14;
BA_ "CANFD_BRS" BO_ 696 1;
BA_ "GenMsgCycleTime" BO_ 696 40;
BA_ "GenMsgCycleTimeFast" BO_ 696 0;
BA_ "GenMsgSendType" BO_ 696 0;
BA_ "VFrameFormat" BO_ 696 14;
BA_ "CANFD_BRS" BO_ 696 1;
BA_ "GenMsgCycleTime" BO_ 696 40;
BA_ "GenMsgCycleTimeFast" BO_ 696 0;
BA_ "GenMsgSendType" BO_ 696 0;
BA_ "VFrameFormat" BO_ 696 14;
BA_ "CANFD_BRS" BO_ 696 1;
BA_ "GenMsgCycleTime" BO_ 696 40;
BA_ "GenMsgCycleTimeFast" BO_ 696 0;
BA_ "GenMsgSendType" BO_ 696 0;
BA_ "VFrameFormat" BO_ 696 14;
BA_ "CANFD_BRS" BO_ 696 1;
BA_ "GenMsgCycleTime" BO_ 696 40;
BA_ "GenMsgCycleTimeFast" BO_ 696 0;
BA_ "GenMsgSendType" BO_ 696 0;
BA_ "VFrameFormat" BO_ 696 14;
BA_ "CANFD_BRS" BO_ 696 1;
BA_ "GenMsgCycleTime" BO_ 696 40;
BA_ "GenMsgCycleTimeFast" BO_ 696 0;
BA_ "GenMsgSendType" BO_ 696 0;
BA_ "VFrameFormat" BO_ 696 14;
BA_ "CANFD_BRS" BO_ 696 1;
BA_ "GenMsgCycleTime" BO_ 696 40;
BA_ "GenMsgCycleTimeFast" BO_ 696 0;
BA_ "GenMsgSendType" BO_ 696 0;
BA_ "VFrameFormat" BO_ 696 14;
BA_ "CANFD_BRS" BO_ 696 1;
BA_ "GenMsgCycleTime" BO_ 696 40;
BA_ "GenMsgCycleTimeFast" BO_ 696 0;
BA_ "GenMsgSendType" BO_ 696 0;
BA_ "VFrameFormat" BO_ 696 14;
BA_ "CANFD_BRS" BO_ 696 1;
BA_ "GenMsgCycleTime" BO_ 696 40;
BA_ "GenMsgCycleTimeFast" BO_ 696 0;
BA_ "GenMsgSendType" BO_ 696 0;
BA_ "VFrameFormat" BO_ 696 14;
BA_ "CANFD_BRS" BO_ 696 1;
BA_ "GenMsgCycleTime" BO_ 696 40;
BA_ "GenMsgCycleTimeFast" BO_ 696 0;
BA_ "GenMsgSendType" BO_ 696 0;
BA_ "VFrameFormat" BO_ 696 14;
BA_ "CANFD_BRS" BO_ 696 1;
BA_ "GenMsgCycleTime" BO_ 696 40;
BA_ "GenMsgCycleTimeFast" BO_ 696 0;
BA_ "GenMsgSendType" BO_ 696 0;
BA_ "VFrameFormat" BO_ 696 14;
BA_ "CANFD_BRS" BO_ 696 1;
BA_ "GenMsgCycleTime" BO_ 696 40;
BA_ "GenMsgCycleTimeFast" BO_ 696 0;
BA_ "GenMsgSendType" BO_ 696 0;
BA_ "VFrameFormat" BO_ 696 14;
BA_ "CANFD_BRS" BO_ 696 1;
BA_ "GenMsgCycleTime" BO_ 696 40;
BA_ "GenMsgCycleTimeFast" BO_ 696 0;
BA_ "GenMsgSendType" BO_ 696 0;
BA_ "VFrameFormat" BO_ 696 14;
BA_ "CANFD_BRS" BO_ 696 1;
BA_ "GenMsgCycleTime" BO_ 696 40;
BA_ "GenMsgCycleTimeFast" BO_ 696 0;
BA_ "GenMsgSendType" BO_ 696 0;
BA_ "VFrameFormat" BO_ 696 14;
BA_ "CANFD_BRS" BO_ 696 1;
BA_ "GenMsgCycleTime" BO_ 696 40;
BA_ "GenMsgCycleTimeFast" BO_ 696 0;
BA_ "GenMsgSendType" BO_ 696 0;
BA_ "VFrameFormat" BO_ 696 14;
BA_ "CANFD_BRS" BO_ 696 1;
BA_ "GenMsgCycleTime" BO_ 696 40;
BA_ "GenMsgCycleTimeFast" BO_ 696 0;
BA_ "GenMsgSendType" BO_ 696 0;
BA_ "VFrameFormat" BO_ 696 14;
BA_ "CANFD_BRS" BO_ 696 1;
BA_ "GenMsgCycleTime" BO_ 696 40;
BA_ "GenMsgCycleTimeFast" BO_ 696 0;
BA_ "GenMsgSendType" BO_ 696 0;
BA_ "VFrameFormat" BO_ 696 14;
BA_ "CANFD_BRS" BO_ 696 1;
BA_ "GenMsgCycleTime" BO_ 696 40;
BA_ "GenMsgCycleTimeFast" BO_ 696 0;
BA_ "GenMsgSendType" BO_ 696 0;
BA_ "VFrameFormat" BO_ 696 14;
BA_ "CANFD_BRS" BO_ 696 1;
BA_ "GenMsgCycleTime" BO_ 696 40;
BA_ "GenMsgCycleTimeFast" BO_ 696 0;
BA_ "GenMsgSendType" BO_ 696 0;
BA_ "VFrameFormat" BO_ 696 14;
BA_ "CANFD_BRS" BO_ 696 1;
BA_ "GenMsgCycleTime" BO_ 696 40;
BA_ "GenMsgCycleTimeFast" BO_ 696 0;
BA_ "GenMsgSendType" BO_ 696 0;
BA_ "VFrameFormat" BO_ 696 14;
BA_ "CANFD_BRS" BO_ 696 1;
BA_ "GenMsgCycleTime" BO_ 696 40;
BA_ "GenMsgCycleTimeFast" BO_ 696 0;
BA_ "GenMsgSendType" BO_ 696 0;
BA_ "VFrameFormat" BO_ 696 14;
BA_ "CANFD_BRS" BO_ 696 1;
BA_ "GenMsgCycleTime" BO_ 696 40;
BA_ "GenMsgCycleTimeFast" BO_ 696 0;
BA_ "GenMsgSendType" BO_ 696 0;
BA_ "VFrameFormat" BO_ 696 14;
BA_ "CANFD_BRS" BO_ 696 1;
BA_ "GenMsgCycleTime" BO_ 696 40;
BA_ "GenMsgCycleTimeFast" BO_ 696 0;
BA_ "GenMsgSendType" BO_ 696 0;
BA_ "VFrameFormat" BO_ 696 14;
BA_ "CANFD_BRS" BO_ 696 1;
BA_ "GenMsgCycleTime" BO_ 696 40;
BA_ "GenMsgCycleTimeFast" BO_ 696 0;
BA_ "GenMsgSendType" BO_ 696 0;
BA_ "VFrameFormat" BO_ 696 14;
BA_ "CANFD_BRS" BO_ 696 1;
BA_ "GenMsgCycleTime" BO_ 696 40;
BA_ "GenMsgCycleTimeFast" BO_ 696 0;
BA_ "GenMsgSendType" BO_ 696 0;
BA_ "VFrameFormat" BO_ 696 14;
BA_ "CANFD_BRS" BO_ 696 1;
BA_ "GenMsgCycleTime" BO_ 696 40;
BA_ "GenMsgCycleTimeFast" BO_ 696 0;
BA_ "GenMsgSendType" BO_ 696 0;
BA_ "VFrameFormat" BO_ 696 14;
BA_ "CANFD_BRS" BO_ 696 1;
BA_ "GenMsgCycleTime" BO_ 696 40;
BA_ "GenMsgCycleTimeFast" BO_ 696 0;
BA_ "GenMsgSendType" BO_ 696 0;
BA_ "VFrameFormat" BO_ 696 14;
BA_ "CANFD_BRS" BO_ 696 1;
BA_ "GenMsgCycleTime" BO_ 696 40;
BA_ "GenMsgCycleTimeFast" BO_ 696 0;
BA_ "GenMsgSendType" BO_ 696 0;
BA_ "VFrameFormat" BO_ 696 14;
BA_ "CANFD_BRS" BO_ 696 1;
BA_ "GenMsgCycleTime" BO_ 696 40;
BA_ "GenMsgCycleTimeFast" BO_ 696 0;
BA_ "GenMsgSendType" BO_ 696 0;
BA_ "VFrameFormat" BO_ 696 14;
BA_ "CANFD_BRS" BO_ 696 1;
BA_ "GenMsgCycleTime" BO_ 696 40;
BA_ "GenMsgCycleTimeFast" BO_ 696 0;
BA_ "GenMsgSendType" BO_ 696 0;
BA_ "VFrameFormat" BO_ 696 14;
BA_ "CANFD_BRS" BO_ 696 1;
BA_ "GenMsgCycleTime" BO_ 696 40;
BA_ "GenMsgCycleTimeFast" BO_ 696 0;
BA_ "GenMsgSendType" BO_ 696 0;
BA_ "VFrameFormat" BO_ 696 14;
BA_ "CANFD_BRS" BO_ 696 1;
BA_ "GenMsgCycleTime" BO_ 696 40;
BA_ "GenMsgCycleTimeFast" BO_ 696 0;
BA_ "GenMsgSendType" BO_ 696 0;
BA_ "VFrameFormat" BO_ 696 14;
BA_ "CANFD_BRS" BO_ 696 1;
BA_ "GenMsgCycleTime" BO_ 696 40;
BA_ "GenMsgCycleTimeFast" BO_ 696 0;
BA_ "GenMsgSendType" BO_ 696 0;
BA_ "VFrameFormat" BO_ 696 14;
BA_ "CANFD_BRS" BO_ 696 1;
BA_ "GenMsgCycleTime" BO_ 696 40;
BA_ "GenMsgCycleTimeFast" BO_ 696 0;
BA_ "GenMsgSendType" BO_ 696 0;
BA_ "VFrameFormat" BO_ 696 14;
BA_ "CANFD_BRS" BO_ 696 1;
BA_ "GenMsgCycleTime" BO_ 696 40;
BA_ "GenMsgCycleTimeFast" BO_ 696 0;
BA_ "GenMsgSendType" BO_ 696 0;
BA_ "VFrameFormat" BO_ 696 14;
BA_ "CANFD_BRS" BO_ 696 1;
BA_ "GenMsgCycleTime" BO_ 696 40;
BA_ "GenMsgCycleTimeFast" BO_ 696 0;
BA_ "GenMsgSendType" BO_ 696 0;
BA_ "VFrameFormat" BO_ 696 14;
BA_ "CANFD_BRS" BO_ 696 1;
BA_ "GenMsgCycleTime" BO_ 696 40;
BA_ "GenMsgCycleTimeFast" BO_ 696 0;
BA_ "GenMsgSendType" BO_ 696 0;
BA_ "VFrameFormat" BO_ 696 14;
BA_ "CANFD_BRS" BO_ 696 1;
BA_ "GenMsgCycleTime" BO_ 696 40;
BA_ "GenMsgCycleTimeFast" BO_ 696 0;
BA_ "GenMsgSendType" BO_ 696 0;
BA_ "VFrameFormat" BO_ 696 14;
BA_ "CANFD_BRS" BO_ 696 1;
BA_ "GenMsgCycleTime" BO_ 696 40;
BA_ "GenMsgCycleTimeFast" BO_ 696 0;
BA_ "GenMsgSendType" BO_ 696 0;
BA_ "VFrameFormat" BO_ 696 14;
BA_ "CANFD_BRS" BO_ 696 1;
BA_ "GenMsgCycleTime" BO_ 696 40;
BA_ "GenMsgCycleTimeFast" BO_ 696 0;
BA_ "GenMsgSendType" BO_ 696 0;
BA_ "VFrameFormat" BO_ 696 14;
BA_ "CANFD_BRS" BO_ 696 1;
BA_ "GenMsgCycleTime" BO_ 696 40;
BA_ "GenMsgCycleTimeFast" BO_ 696 0;
BA_ "GenMsgSendType" BO_ 696 0;
BA_ "VFrameFormat" BO_ 696 14;
BA_ "CANFD_BRS" BO_ 696 1;
BA_ "GenMsgCycleTime" BO_ 696 40;
BA_ "GenMsgCycleTimeFast" BO_ 696 0;
BA_ "GenMsgSendType" BO_ 696 0;
BA_ "VFrameFormat" BO_ 696 14;
BA_ "CANFD_BRS" BO_ 696 1;
BA_ "GenMsgCycleTime" BO_ 696 40;
BA_ "GenMsgCycleTimeFast" BO_ 696 0;
BA_ "GenMsgSendType" BO_ 696 0;
BA_ "VFrameFormat" BO_ 696 14;
BA_ "CANFD_BRS" BO_ 696 1;
BA_ "GenMsgCycleTime" BO_ 696 40;
BA_ "GenMsgCycleTimeFast" BO_ 696 0;
BA_ "GenMsgSendType" BO_ 696 0;
BA_ "VFrameFormat" BO_ 696 14;
BA_ "CANFD_BRS" BO_ 696 1;
BA_ "GenMsgCycleTime" BO_ 696 40;
BA_ "GenMsgCycleTimeFast" BO_ 696 0;
BA_ "GenMsgSendType" BO_ 696 0;
BA_ "VFrameFormat" BO_ 696 14;
BA_ "CANFD_BRS" BO_ 696 1;
BA_ "GenMsgCycleTime" BO_ 696 40;
BA_ "GenMsgCycleTimeFast" BO_ 696 0;
BA_ "GenMsgSendType" BO_ 696 0;
BA_ "VFrameFormat" BO_ 696 14;
BA_ "CANFD_BRS" BO_ 696 1;
BA_ "GenMsgCycleTime" BO_ 696 40;
BA_ "GenMsgCycleTimeFast" BO_ 696 0;
BA_ "GenMsgSendType" BO_ 696 0;
BA_ "VFrameFormat" BO_ 696 14;
BA_ "CANFD_BRS" BO_ 696 1;
BA_ "GenMsgCycleTime" BO_ 696 40;
BA_ "GenMsgCycleTimeFast" BO_ 696 0;
BA_ "GenMsgSendType" BO_ 696 0;
BA_ "VFrameFormat" BO_ 696 14;
BA_ "CANFD_BRS" BO_ 696 1;
BA_ "GenMsgCycleTime" BO_ 696 40;
BA_ "GenMsgCycleTimeFast" BO_ 696 0;
BA_ "GenMsgSendType" BO_ 696 0;
BA_ "VFrameFormat" BO_ 696 14;
BA_ "CANFD_BRS" BO_ 696 1;
BA_ "GenMsgCycleTime" BO_ 696 40;
BA_ "GenMsgCycleTimeFast" BO_ 696 0;
BA_ "GenMsgSendType" BO_ 696 0;
BA_ "VFrameFormat" BO_ 696 14;
BA_ "CANFD_BRS" BO_ 696 1;
BA_ "GenMsgCycleTime" BO_ 696 40;
BA_ "GenMsgCycleTimeFast" BO_ 696 0;
BA_ "GenMsgSendType" BO_ 696 0;
BA_ "VFrameFormat" BO_ 696 14;
BA_ "CANFD_BRS" BO_ 696 1;
BA_ "GenMsgCycleTime" BO_ 696 40;
BA_ "GenMsgCycleTimeFast" BO_ 696 0;
BA_ "GenMsgSendType" BO_ 696 0;
BA_ "VFrameFormat" BO_ 696 14;
BA_ "CANFD_BRS" BO_ 696 1;
BA_ "GenMsgCycleTime" BO_ 696 40;
BA_ "GenMsgCycleTimeFast" BO_ 696 0;
BA_ "GenMsgSendType" BO_ 696 0;
BA_ "VFrameFormat" BO_ 696 14;
BA_ "CANFD_BRS" BO_ 696 1;
BA_ "GenMsgCycleTime" BO_ 696 40;
BA_ "GenMsgCycleTimeFast" BO_ 696 0;
BA_ "GenMsgSendType" BO_ 696 0;
BA_ "VFrameFormat" BO_ 696 14;
BA_ "CANFD_BRS" BO_ 696 1;
BA_ "GenMsgCycleTime" BO_ 696 40;
BA_ "GenMsgCycleTimeFast" BO_ 696 0;
BA_ "GenMsgSendType" BO_ 696 0;
BA_ "VFrameFormat" BO_ 696 14;
BA_ "CANFD_BRS" BO_ 696 1;
BA_ "GenMsgCycleTime" BO_ 696 40;
BA_ "GenMsgCycleTimeFast" BO_ 696 0;
BA_ "GenMsgSendType" BO_ 696 0;
BA_ "VFrameFormat" BO_ 696 14;
BA_ "CANFD_BRS" BO_ 696 1;
BA_ "GenMsgCycleTime" BO_ 696 40;
BA_ "GenMsgCycleTimeFast" BO_ 696 0;
BA_ "GenMsgSendType" BO_ 696 0;
BA_ "VFrameFormat" BO_ 696 14;
BA_ "CANFD_BRS" BO_ 696 1;
BA_ "GenMsgCycleTime" BO_ 696 40;
BA_ "GenMsgCycleTimeFast" BO_ 696 0;
BA_ "GenMsgSendType" BO_ 696 0;
BA_ "VFrameFormat" BO_ 696 14;
BA_ "CANFD_BRS" BO_ 696 1;
BA_ "GenMsgCycleTime" BO_ 696 40;
BA_ "GenMsgCycleTimeFast" BO_ 696 0;
BA_ "GenMsgSendType" BO_ 696 0;
BA_ "VFrameFormat" BO_ 696 14;
BA_ "CANFD_BRS" BO_ 696 1;
BA_ "GenMsgCycleTime" BO_ 696 40;
BA_ "GenMsgCycleTimeFast" BO_ 696 0;
BA_ "GenMsgSendType" BO_ 696 0;
BA_ "VFrameFormat" BO_ 696 14;
BA_ "CANFD_BRS" BO_ 696 1;
BA_ "GenMsgCycleTime" BO_ 696 40;
BA_ "GenMsgCycleTimeFast" BO_ 696 0;
BA_ "GenMsgSendType" BO_ 696 0;
BA_ "VFrameFormat" BO_ 696 14;
BA_ "CANFD_BRS" BO_ 696 1;
BA_ "GenMsgCycleTime" BO_ 696 40;
BA_ "GenMsgCycleTimeFast" BO_ 696 0;
BA_ "GenMsgSendType" BO_ 696 0;
BA_ "VFrameFormat" BO_ 696 14;
BA_ "CANFD_BRS" BO_ 696 1;
BA_ "GenMsgCycleTime" BO_ 696 40;
BA_ "GenMsgCycleTimeFast" BO_ 696 0;
BA_ "GenMsgSendType" BO_ 696 0;
BA_ "VFrameFormat" BO_ 696 14;
BA_ "CANFD_BRS" BO_ 696 1;
BA_ "GenMsgCycleTime" BO_ 696 40;
BA_ "GenMsgCycleTimeFast" BO_ 696 0;
BA_ "GenMsgSendType" BO_ 696 0;
BA_ "VFrameFormat" BO_ 696 14;
BA_ "CANFD_BRS" BO_ 696 1;
BA_ "GenMsgCycleTime" BO_ 696 40;
BA_ "GenMsgCycleTimeFast" BO_ 696 0;
BA_ "GenMsgSendType" BO_ 696 0;
BA_ "VFrameFormat" BO_ 696 14;
BA_ "CANFD_BRS" BO_ 696 1;
BA_ "GenMsgCycleTime" BO_ 696 40;
BA_ "GenMsgCycleTimeFast" BO_ 696 0;
BA_ "GenMsgSendType" BO_ 696 0;
BA_ "VFrameFormat" BO_ 696 14;
BA_ "CANFD_BRS" BO_ 696 1;
BA_ "GenMsgCycleTime" BO_ 696 40;
BA_ "GenMsgCycleTimeFast" BO_ 696 0;
BA_ "GenMsgSendType" BO_ 696 0;
BA_ "VFrameFormat" BO_ 696 14;
BA_ "CANFD_BRS" BO_ 696 1;
BA_ "GenMsgCycleTime" BO_ 696 40;
BA_ "GenMsgCycleTimeFast" BO_ 696 0;
BA_ "GenMsgSendType" BO_ 696 0;
BA_ "VFrameFormat" BO_ 696 14;
BA_ "CANFD_BRS" BO_ 696 1;
BA_ "GenMsgCycleTime" BO_ 696 40;
BA_ "GenMsgCycleTimeFast" BO_ 696 0;
BA_ "GenMsgSendType" BO_ 696 0;
BA_ "VFrameFormat" BO_ 696 14;
BA_ "CANFD_BRS" BO_ 696 1;
BA_ "GenMsgCycleTime" BO_ 696 40;
BA_ "GenMsgCycleTimeFast" BO_ 696 0;
BA_ "GenMsgSendType" BO_ 696 0;
BA_ "VFrameFormat" BO_ 696 14;
BA_ "CANFD_BRS" BO_ 696 1;
BA_ "GenMsgCycleTime" BO_ 696 40;
BA_ "GenMsgCycleTimeFast" BO_ 696 0;
BA_ "GenMsgSendType" BO_ 696 0;
BA_ "VFrameFormat" BO_ 696 14;
BA_ "CANFD_BRS" BO_ 696 1;
BA_ "GenMsgCycleTime" BO_ 696 40;
BA_ "GenMsgCycleTimeFast" BO_ 696 0;
BA_ "GenMsgSendType" BO_ 696 0;
BA_ "VFrameFormat" BO_ 696 14;
BA_ "CANFD_BRS" BO_ 696 1;
BA_ "GenMsgCycleTime" BO_ 696 40;
BA_ "GenMsgCycleTimeFast" BO_ 696 0;
BA_ "GenMsgSendType" BO_ 696 0;
BA_ "VFrameFormat" BO_ 696 14;
BA_ "CANFD_BRS" BO_ 696 1;
BA_ "GenMsgCycleTime" BO_ 696 40;
BA_ "GenMsgCycleTimeFast" BO_ 696 0;
BA_ "GenMsgSendType" BO_ 696 0;
BA_ "VFrameFormat" BO_ 696 14;
BA_ "CANFD_BRS" BO_ 696 1;
BA_ "GenMsgCycleTime" BO_ 696 40;
BA_ "GenMsgCycleTimeFast" BO_ 696 0;
BA_ "GenMsgSendType" BO_ 696 0;
BA_ "VFrameFormat" BO_ 696 14;
BA_ "CANFD_BRS" BO_ 696 1;
BA_ "GenMsgCycleTime" BO_ 696 40;
BA_ "GenMsgCycleTimeFast" BO_ 696 0;
BA_ "GenMsgSendType" BO_ 696 0;
BA_ "VFrameFormat" BO_ 696 14;
BA_ "CANFD_BRS" BO_ 696 1;
BA_ "GenMsgCycleTime" BO_ 1934 0;
BA_ "GenMsgCycleTimeFast" BO_ 1934 0;
BA_ "GenMsgSendType" BO_ 1934 1;
BA_ "VFrameFormat" BO_ 1934 14;
BA_ "CANFD_BRS" BO_ 1934 1;
BA_ "GenMsgCycleTime" BO_ 1294 200;
BA_ "GenMsgCycleTimeFast" BO_ 1294 0;
BA_ "GenMsgSendType" BO_ 1294 0;
BA_ "VFrameFormat" BO_ 1294 0;
BA_ "CANFD_BRS" BO_ 1294 1;
BA_ "GenMsgCycleTime" BO_ 1294 200;
BA_ "GenMsgCycleTimeFast" BO_ 1294 0;
BA_ "GenMsgSendType" BO_ 1294 0;
BA_ "VFrameFormat" BO_ 1294 0;
BA_ "CANFD_BRS" BO_ 1294 1;
BA_ "GenMsgCycleTime" BO_ 1294 200;
BA_ "GenMsgCycleTimeFast" BO_ 1294 0;
BA_ "GenMsgSendType" BO_ 1294 0;
BA_ "VFrameFormat" BO_ 1294 0;
BA_ "CANFD_BRS" BO_ 1294 1;
BA_ "GenMsgCycleTime" BO_ 1294 200;
BA_ "GenMsgCycleTimeFast" BO_ 1294 0;
BA_ "GenMsgSendType" BO_ 1294 0;
BA_ "VFrameFormat" BO_ 1294 0;
BA_ "CANFD_BRS" BO_ 1294 1;
BA_ "GenMsgCycleTime" BO_ 1294 200;
BA_ "GenMsgCycleTimeFast" BO_ 1294 0;
BA_ "GenMsgSendType" BO_ 1294 0;
BA_ "VFrameFormat" BO_ 1294 0;
BA_ "CANFD_BRS" BO_ 1294 1;
BA_ "GenMsgCycleTime" BO_ 1294 200;
BA_ "GenMsgCycleTimeFast" BO_ 1294 0;
BA_ "GenMsgSendType" BO_ 1294 0;
BA_ "VFrameFormat" BO_ 1294 0;
BA_ "CANFD_BRS" BO_ 1294 1;
BA_ "GenMsgCycleTime" BO_ 1343 200;
BA_ "GenMsgCycleTimeFast" BO_ 1343 0;
BA_ "GenMsgSendType" BO_ 1343 0;
BA_ "VFrameFormat" BO_ 1343 0;
BA_ "CANFD_BRS" BO_ 1343 1;
BA_ "GenMsgCycleTime" BO_ 1343 200;
BA_ "GenMsgCycleTimeFast" BO_ 1343 0;
BA_ "GenMsgSendType" BO_ 1343 0;
BA_ "VFrameFormat" BO_ 1343 0;
BA_ "CANFD_BRS" BO_ 1343 1;
BA_ "GenMsgCycleTime" BO_ 1343 200;
BA_ "GenMsgCycleTimeFast" BO_ 1343 0;
BA_ "GenMsgSendType" BO_ 1343 0;
BA_ "VFrameFormat" BO_ 1343 0;
BA_ "CANFD_BRS" BO_ 1343 1;
BA_ "GenMsgCycleTime" BO_ 1343 200;
BA_ "GenMsgCycleTimeFast" BO_ 1343 0;
BA_ "GenMsgSendType" BO_ 1343 0;
BA_ "VFrameFormat" BO_ 1343 0;
BA_ "CANFD_BRS" BO_ 1343 1;
BA_ "GenMsgCycleTime" BO_ 1343 200;
BA_ "GenMsgCycleTimeFast" BO_ 1343 0;
BA_ "GenMsgSendType" BO_ 1343 0;
BA_ "VFrameFormat" BO_ 1343 0;
BA_ "CANFD_BRS" BO_ 1343 1;
BA_ "GenMsgCycleTime" BO_ 1343 200;
BA_ "GenMsgCycleTimeFast" BO_ 1343 0;
BA_ "GenMsgSendType" BO_ 1343 0;
BA_ "VFrameFormat" BO_ 1343 0;
BA_ "CANFD_BRS" BO_ 1343 1;
BA_ "GenMsgCycleTime" BO_ 1354 200;
BA_ "GenMsgCycleTimeFast" BO_ 1354 0;
BA_ "GenMsgSendType" BO_ 1354 0;
BA_ "VFrameFormat" BO_ 1354 0;
BA_ "CANFD_BRS" BO_ 1354 1;
BA_ "GenMsgCycleTime" BO_ 1354 200;
BA_ "GenMsgCycleTimeFast" BO_ 1354 0;
BA_ "GenMsgSendType" BO_ 1354 0;
BA_ "VFrameFormat" BO_ 1354 0;
BA_ "CANFD_BRS" BO_ 1354 1;
BA_ "GenMsgCycleTime" BO_ 1354 200;
BA_ "GenMsgCycleTimeFast" BO_ 1354 0;
BA_ "GenMsgSendType" BO_ 1354 0;
BA_ "VFrameFormat" BO_ 1354 0;
BA_ "CANFD_BRS" BO_ 1354 1;
BA_ "GenMsgCycleTime" BO_ 1354 200;
BA_ "GenMsgCycleTimeFast" BO_ 1354 0;
BA_ "GenMsgSendType" BO_ 1354 0;
BA_ "VFrameFormat" BO_ 1354 0;
BA_ "CANFD_BRS" BO_ 1354 1;
BA_ "GenMsgCycleTime" BO_ 1354 200;
BA_ "GenMsgCycleTimeFast" BO_ 1354 0;
BA_ "GenMsgSendType" BO_ 1354 0;
BA_ "VFrameFormat" BO_ 1354 0;
BA_ "CANFD_BRS" BO_ 1354 1;
BA_ "GenMsgCycleTime" BO_ 1354 200;
BA_ "GenMsgCycleTimeFast" BO_ 1354 0;
BA_ "GenMsgSendType" BO_ 1354 0;
BA_ "VFrameFormat" BO_ 1354 0;
BA_ "CANFD_BRS" BO_ 1354 1;
BA_ "GenMsgCycleTime" BO_ 932 50;
BA_ "GenMsgCycleTimeFast" BO_ 932 0;
BA_ "GenMsgSendType" BO_ 932 0;
BA_ "VFrameFormat" BO_ 932 14;
BA_ "CANFD_BRS" BO_ 932 1;
BA_ "GenMsgCycleTime" BO_ 932 50;
BA_ "GenMsgCycleTimeFast" BO_ 932 0;
BA_ "GenMsgSendType" BO_ 932 0;
BA_ "VFrameFormat" BO_ 932 14;
BA_ "CANFD_BRS" BO_ 932 1;
BA_ "GenMsgCycleTime" BO_ 932 50;
BA_ "GenMsgCycleTimeFast" BO_ 932 0;
BA_ "GenMsgSendType" BO_ 932 0;
BA_ "VFrameFormat" BO_ 932 14;
BA_ "CANFD_BRS" BO_ 932 1;
BA_ "GenMsgCycleTime" BO_ 932 50;
BA_ "GenMsgCycleTimeFast" BO_ 932 0;
BA_ "GenMsgSendType" BO_ 932 0;
BA_ "VFrameFormat" BO_ 932 14;
BA_ "CANFD_BRS" BO_ 932 1;
BA_ "GenMsgCycleTime" BO_ 932 50;
BA_ "GenMsgCycleTimeFast" BO_ 932 0;
BA_ "GenMsgSendType" BO_ 932 0;
BA_ "VFrameFormat" BO_ 932 14;
BA_ "CANFD_BRS" BO_ 932 1;
BA_ "GenMsgCycleTime" BO_ 932 50;
BA_ "GenMsgCycleTimeFast" BO_ 932 0;
BA_ "GenMsgSendType" BO_ 932 0;
BA_ "VFrameFormat" BO_ 932 14;
BA_ "CANFD_BRS" BO_ 932 1;
BA_ "GenMsgCycleTime" BO_ 932 50;
BA_ "GenMsgCycleTimeFast" BO_ 932 0;
BA_ "GenMsgSendType" BO_ 932 0;
BA_ "VFrameFormat" BO_ 932 14;
BA_ "CANFD_BRS" BO_ 932 1;
BA_ "GenMsgCycleTime" BO_ 932 50;
BA_ "GenMsgCycleTimeFast" BO_ 932 0;
BA_ "GenMsgSendType" BO_ 932 0;
BA_ "VFrameFormat" BO_ 932 14;
BA_ "CANFD_BRS" BO_ 932 1;
BA_ "GenMsgCycleTime" BO_ 932 50;
BA_ "GenMsgCycleTimeFast" BO_ 932 0;
BA_ "GenMsgSendType" BO_ 932 0;
BA_ "VFrameFormat" BO_ 932 14;
BA_ "CANFD_BRS" BO_ 932 1;
BA_ "GenMsgCycleTime" BO_ 932 50;
BA_ "GenMsgCycleTimeFast" BO_ 932 0;
BA_ "GenMsgSendType" BO_ 932 0;
BA_ "VFrameFormat" BO_ 932 14;
BA_ "CANFD_BRS" BO_ 932 1;
BA_ "GenMsgCycleTime" BO_ 932 50;
BA_ "GenMsgCycleTimeFast" BO_ 932 0;
BA_ "GenMsgSendType" BO_ 932 0;
BA_ "VFrameFormat" BO_ 932 14;
BA_ "CANFD_BRS" BO_ 932 1;
BA_ "GenMsgCycleTime" BO_ 932 50;
BA_ "GenMsgCycleTimeFast" BO_ 932 0;
BA_ "GenMsgSendType" BO_ 932 0;
BA_ "VFrameFormat" BO_ 932 14;
BA_ "CANFD_BRS" BO_ 932 1;
BA_ "GenMsgCycleTime" BO_ 932 50;
BA_ "GenMsgCycleTimeFast" BO_ 932 0;
BA_ "GenMsgSendType" BO_ 932 0;
BA_ "VFrameFormat" BO_ 932 14;
BA_ "CANFD_BRS" BO_ 932 1;
BA_ "GenMsgCycleTime" BO_ 932 50;
BA_ "GenMsgCycleTimeFast" BO_ 932 0;
BA_ "GenMsgSendType" BO_ 932 0;
BA_ "VFrameFormat" BO_ 932 14;
BA_ "CANFD_BRS" BO_ 932 1;
BA_ "GenMsgCycleTime" BO_ 932 50;
BA_ "GenMsgCycleTimeFast" BO_ 932 0;
BA_ "GenMsgSendType" BO_ 932 0;
BA_ "VFrameFormat" BO_ 932 14;
BA_ "CANFD_BRS" BO_ 932 1;
BA_ "GenMsgCycleTime" BO_ 932 50;
BA_ "GenMsgCycleTimeFast" BO_ 932 0;
BA_ "GenMsgSendType" BO_ 932 0;
BA_ "VFrameFormat" BO_ 932 14;
BA_ "CANFD_BRS" BO_ 932 1;
BA_ "GenMsgCycleTime" BO_ 932 50;
BA_ "GenMsgCycleTimeFast" BO_ 932 0;
BA_ "GenMsgSendType" BO_ 932 0;
BA_ "VFrameFormat" BO_ 932 14;
BA_ "CANFD_BRS" BO_ 932 1;
BA_ "GenMsgCycleTime" BO_ 932 50;
BA_ "GenMsgCycleTimeFast" BO_ 932 0;
BA_ "GenMsgSendType" BO_ 932 0;
BA_ "VFrameFormat" BO_ 932 14;
BA_ "CANFD_BRS" BO_ 932 1;
BA_ "GenMsgCycleTime" BO_ 932 50;
BA_ "GenMsgCycleTimeFast" BO_ 932 0;
BA_ "GenMsgSendType" BO_ 932 0;
BA_ "VFrameFormat" BO_ 932 14;
BA_ "CANFD_BRS" BO_ 932 1;
BA_ "GenMsgCycleTime" BO_ 932 50;
BA_ "GenMsgCycleTimeFast" BO_ 932 0;
BA_ "GenMsgSendType" BO_ 932 0;
BA_ "VFrameFormat" BO_ 932 14;
BA_ "CANFD_BRS" BO_ 932 1;
BA_ "GenMsgCycleTime" BO_ 932 50;
BA_ "GenMsgCycleTimeFast" BO_ 932 0;
BA_ "GenMsgSendType" BO_ 932 0;
BA_ "VFrameFormat" BO_ 932 14;
BA_ "CANFD_BRS" BO_ 932 1;
BA_ "GenMsgCycleTime" BO_ 932 50;
BA_ "GenMsgCycleTimeFast" BO_ 932 0;
BA_ "GenMsgSendType" BO_ 932 0;
BA_ "VFrameFormat" BO_ 932 14;
BA_ "CANFD_BRS" BO_ 932 1;
BA_ "GenMsgCycleTime" BO_ 932 50;
BA_ "GenMsgCycleTimeFast" BO_ 932 0;
BA_ "GenMsgSendType" BO_ 932 0;
BA_ "VFrameFormat" BO_ 932 14;
BA_ "CANFD_BRS" BO_ 932 1;
BA_ "GenMsgCycleTime" BO_ 932 50;
BA_ "GenMsgCycleTimeFast" BO_ 932 0;
BA_ "GenMsgSendType" BO_ 932 0;
BA_ "VFrameFormat" BO_ 932 14;
BA_ "CANFD_BRS" BO_ 932 1;
BA_ "GenMsgCycleTime" BO_ 932 50;
BA_ "GenMsgCycleTimeFast" BO_ 932 0;
BA_ "GenMsgSendType" BO_ 932 0;
BA_ "VFrameFormat" BO_ 932 14;
BA_ "CANFD_BRS" BO_ 932 1;
BA_ "GenMsgCycleTime" BO_ 987 50;
BA_ "GenMsgCycleTimeFast" BO_ 987 0;
BA_ "GenMsgSendType" BO_ 987 0;
BA_ "VFrameFormat" BO_ 987 14;
BA_ "CANFD_BRS" BO_ 987 1;
BA_ "GenMsgCycleTime" BO_ 987 50;
BA_ "GenMsgCycleTimeFast" BO_ 987 0;
BA_ "GenMsgSendType" BO_ 987 0;
BA_ "VFrameFormat" BO_ 987 14;
BA_ "CANFD_BRS" BO_ 987 1;
BA_ "GenMsgCycleTime" BO_ 987 50;
BA_ "GenMsgCycleTimeFast" BO_ 987 0;
BA_ "GenMsgSendType" BO_ 987 0;
BA_ "VFrameFormat" BO_ 987 14;
BA_ "CANFD_BRS" BO_ 987 1;
BA_ "GenMsgCycleTime" BO_ 987 50;
BA_ "GenMsgCycleTimeFast" BO_ 987 0;
BA_ "GenMsgSendType" BO_ 987 0;
BA_ "VFrameFormat" BO_ 987 14;
BA_ "CANFD_BRS" BO_ 987 1;
BA_ "GenMsgCycleTime" BO_ 987 50;
BA_ "GenMsgCycleTimeFast" BO_ 987 0;
BA_ "GenMsgSendType" BO_ 987 0;
BA_ "VFrameFormat" BO_ 987 14;
BA_ "CANFD_BRS" BO_ 987 1;
BA_ "GenMsgCycleTime" BO_ 987 50;
BA_ "GenMsgCycleTimeFast" BO_ 987 0;
BA_ "GenMsgSendType" BO_ 987 0;
BA_ "VFrameFormat" BO_ 987 14;
BA_ "CANFD_BRS" BO_ 987 1;
BA_ "GenMsgCycleTime" BO_ 987 50;
BA_ "GenMsgCycleTimeFast" BO_ 987 0;
BA_ "GenMsgSendType" BO_ 987 0;
BA_ "VFrameFormat" BO_ 987 14;
BA_ "CANFD_BRS" BO_ 987 1;
BA_ "GenMsgCycleTime" BO_ 987 50;
BA_ "GenMsgCycleTimeFast" BO_ 987 0;
BA_ "GenMsgSendType" BO_ 987 0;
BA_ "VFrameFormat" BO_ 987 14;
BA_ "CANFD_BRS" BO_ 987 1;
BA_ "GenMsgCycleTime" BO_ 987 50;
BA_ "GenMsgCycleTimeFast" BO_ 987 0;
BA_ "GenMsgSendType" BO_ 987 0;
BA_ "VFrameFormat" BO_ 987 14;
BA_ "CANFD_BRS" BO_ 987 1;
BA_ "GenMsgCycleTime" BO_ 987 50;
BA_ "GenMsgCycleTimeFast" BO_ 987 0;
BA_ "GenMsgSendType" BO_ 987 0;
BA_ "VFrameFormat" BO_ 987 14;
BA_ "CANFD_BRS" BO_ 987 1;
BA_ "GenMsgCycleTime" BO_ 987 50;
BA_ "GenMsgCycleTimeFast" BO_ 987 0;
BA_ "GenMsgSendType" BO_ 987 0;
BA_ "VFrameFormat" BO_ 987 14;
BA_ "CANFD_BRS" BO_ 987 1;
BA_ "GenMsgCycleTime" BO_ 987 50;
BA_ "GenMsgCycleTimeFast" BO_ 987 0;
BA_ "GenMsgSendType" BO_ 987 0;
BA_ "VFrameFormat" BO_ 987 14;
BA_ "CANFD_BRS" BO_ 987 1;
BA_ "GenMsgCycleTime" BO_ 987 50;
BA_ "GenMsgCycleTimeFast" BO_ 987 0;
BA_ "GenMsgSendType" BO_ 987 0;
BA_ "VFrameFormat" BO_ 987 14;
BA_ "CANFD_BRS" BO_ 987 1;
BA_ "GenMsgCycleTime" BO_ 987 50;
BA_ "GenMsgCycleTimeFast" BO_ 987 0;
BA_ "GenMsgSendType" BO_ 987 0;
BA_ "VFrameFormat" BO_ 987 14;
BA_ "CANFD_BRS" BO_ 987 1;
BA_ "GenMsgCycleTime" BO_ 987 50;
BA_ "GenMsgCycleTimeFast" BO_ 987 0;
BA_ "GenMsgSendType" BO_ 987 0;
BA_ "VFrameFormat" BO_ 987 14;
BA_ "CANFD_BRS" BO_ 987 1;
BA_ "GenMsgCycleTime" BO_ 987 50;
BA_ "GenMsgCycleTimeFast" BO_ 987 0;
BA_ "GenMsgSendType" BO_ 987 0;
BA_ "VFrameFormat" BO_ 987 14;
BA_ "CANFD_BRS" BO_ 987 1;
BA_ "GenMsgCycleTime" BO_ 987 50;
BA_ "GenMsgCycleTimeFast" BO_ 987 0;
BA_ "GenMsgSendType" BO_ 987 0;
BA_ "VFrameFormat" BO_ 987 14;
BA_ "CANFD_BRS" BO_ 987 1;
BA_ "GenMsgCycleTime" BO_ 987 50;
BA_ "GenMsgCycleTimeFast" BO_ 987 0;
BA_ "GenMsgSendType" BO_ 987 0;
BA_ "VFrameFormat" BO_ 987 14;
BA_ "CANFD_BRS" BO_ 987 1;
BA_ "GenMsgCycleTime" BO_ 987 50;
BA_ "GenMsgCycleTimeFast" BO_ 987 0;
BA_ "GenMsgSendType" BO_ 987 0;
BA_ "VFrameFormat" BO_ 987 14;
BA_ "CANFD_BRS" BO_ 987 1;
BA_ "GenMsgCycleTime" BO_ 987 50;
BA_ "GenMsgCycleTimeFast" BO_ 987 0;
BA_ "GenMsgSendType" BO_ 987 0;
BA_ "VFrameFormat" BO_ 987 14;
BA_ "CANFD_BRS" BO_ 987 1;
BA_ "GenMsgCycleTime" BO_ 987 50;
BA_ "GenMsgCycleTimeFast" BO_ 987 0;
BA_ "GenMsgSendType" BO_ 987 0;
BA_ "VFrameFormat" BO_ 987 14;
BA_ "CANFD_BRS" BO_ 987 1;
BA_ "GenMsgCycleTime" BO_ 987 50;
BA_ "GenMsgCycleTimeFast" BO_ 987 0;
BA_ "GenMsgSendType" BO_ 987 0;
BA_ "VFrameFormat" BO_ 987 14;
BA_ "CANFD_BRS" BO_ 987 1;
BA_ "EventCommandSignal" SG_ 696 SBM_5_CRC 0;
BA_ "GatewayedSignals" SG_ 696 SBM_5_CRC 0;
BA_ "GenSigInactiveValue" SG_ 696 SBM_5_CRC 0;
BA_ "GenSigInvalidValue" SG_ 696 SBM_5_CRC 0;
BA_ "GenSigSendType" SG_ 696 SBM_5_CRC 1;
BA_ "GenSigStartValue" SG_ 696 SBM_5_CRC 0;
BA_ "GenSigTimeoutValue" SG_ 696 SBM_5_CRC 0;
BA_ "Remark" SG_ 696 SBM_5_CRC "";
BA_ "EventCommandSignal" SG_ 696 SBM_5_Counter 0;
BA_ "GatewayedSignals" SG_ 696 SBM_5_Counter 0;
BA_ "GenSigInactiveValue" SG_ 696 SBM_5_Counter 0;
BA_ "GenSigInvalidValue" SG_ 696 SBM_5_Counter 0;
BA_ "GenSigSendType" SG_ 696 SBM_5_Counter 1;
BA_ "GenSigStartValue" SG_ 696 SBM_5_Counter 0;
BA_ "GenSigTimeoutValue" SG_ 696 SBM_5_Counter 0;
BA_ "Remark" SG_ 696 SBM_5_Counter "";
BA_ "EventCommandSignal" SG_ 696 KAE_EDK1UnlockBtnPressSt 0;
BA_ "GatewayedSignals" SG_ 696 KAE_EDK1UnlockBtnPressSt 0;
BA_ "GenSigInactiveValue" SG_ 696 KAE_EDK1UnlockBtnPressSt 0;
BA_ "GenSigInvalidValue" SG_ 696 KAE_EDK1UnlockBtnPressSt 0;
BA_ "GenSigSendType" SG_ 696 KAE_EDK1UnlockBtnPressSt 1;
BA_ "GenSigStartValue" SG_ 696 KAE_EDK1UnlockBtnPressSt 0;
BA_ "GenSigTimeoutValue" SG_ 696 KAE_EDK1UnlockBtnPressSt 0;
BA_ "Remark" SG_ 696 KAE_EDK1UnlockBtnPressSt "";
BA_ "EventCommandSignal" SG_ 696 KAE_EDK1LockBtnPressSt 0;
BA_ "GatewayedSignals" SG_ 696 KAE_EDK1LockBtnPressSt 0;
BA_ "GenSigInactiveValue" SG_ 696 KAE_EDK1LockBtnPressSt 0;
BA_ "GenSigInvalidValue" SG_ 696 KAE_EDK1LockBtnPressSt 0;
BA_ "GenSigSendType" SG_ 696 KAE_EDK1LockBtnPressSt 1;
BA_ "GenSigStartValue" SG_ 696 KAE_EDK1LockBtnPressSt 0;
BA_ "GenSigTimeoutValue" SG_ 696 KAE_EDK1LockBtnPressSt 0;
BA_ "Remark" SG_ 696 KAE_EDK1LockBtnPressSt "";
BA_ "EventCommandSignal" SG_ 696 KAE_EDK1RESBtnPressSt 0;
BA_ "GatewayedSignals" SG_ 696 KAE_EDK1RESBtnPressSt 0;
BA_ "GenSigInactiveValue" SG_ 696 KAE_EDK1RESBtnPressSt 0;
BA_ "GenSigInvalidValue" SG_ 696 KAE_EDK1RESBtnPressSt 0;
BA_ "GenSigSendType" SG_ 696 KAE_EDK1RESBtnPressSt 1;
BA_ "GenSigStartValue" SG_ 696 KAE_EDK1RESBtnPressSt 0;
BA_ "GenSigTimeoutValue" SG_ 696 KAE_EDK1RESBtnPressSt 0;
BA_ "Remark" SG_ 696 KAE_EDK1RESBtnPressSt "";
BA_ "EventCommandSignal" SG_ 696 KAE_EDK1PSD_LBtnPressSt 0;
BA_ "GatewayedSignals" SG_ 696 KAE_EDK1PSD_LBtnPressSt 0;
BA_ "GenSigInactiveValue" SG_ 696 KAE_EDK1PSD_LBtnPressSt 0;
BA_ "GenSigInvalidValue" SG_ 696 KAE_EDK1PSD_LBtnPressSt 0;
BA_ "GenSigSendType" SG_ 696 KAE_EDK1PSD_LBtnPressSt 1;
BA_ "GenSigStartValue" SG_ 696 KAE_EDK1PSD_LBtnPressSt 0;
BA_ "GenSigTimeoutValue" SG_ 696 KAE_EDK1PSD_LBtnPressSt 0;
BA_ "Remark" SG_ 696 KAE_EDK1PSD_LBtnPressSt "";
BA_ "EventCommandSignal" SG_ 696 KAE_EDK1PSD_RBtnPressSt 0;
BA_ "GatewayedSignals" SG_ 696 KAE_EDK1PSD_RBtnPressSt 0;
BA_ "GenSigInactiveValue" SG_ 696 KAE_EDK1PSD_RBtnPressSt 0;
BA_ "GenSigInvalidValue" SG_ 696 KAE_EDK1PSD_RBtnPressSt 0;
BA_ "GenSigSendType" SG_ 696 KAE_EDK1PSD_RBtnPressSt 1;
BA_ "GenSigStartValue" SG_ 696 KAE_EDK1PSD_RBtnPressSt 0;
BA_ "GenSigTimeoutValue" SG_ 696 KAE_EDK1PSD_RBtnPressSt 0;
BA_ "Remark" SG_ 696 KAE_EDK1PSD_RBtnPressSt "";
BA_ "EventCommandSignal" SG_ 696 KAE_EDK1TrunkBtnPressSt 0;
BA_ "GatewayedSignals" SG_ 696 KAE_EDK1TrunkBtnPressSt 0;
BA_ "GenSigInactiveValue" SG_ 696 KAE_EDK1TrunkBtnPressSt 0;
BA_ "GenSigInvalidValue" SG_ 696 KAE_EDK1TrunkBtnPressSt 0;
BA_ "GenSigSendType" SG_ 696 KAE_EDK1TrunkBtnPressSt 1;
BA_ "GenSigStartValue" SG_ 696 KAE_EDK1TrunkBtnPressSt 0;
BA_ "GenSigTimeoutValue" SG_ 696 KAE_EDK1TrunkBtnPressSt 0;
BA_ "Remark" SG_ 696 KAE_EDK1TrunkBtnPressSt "";
BA_ "EventCommandSignal" SG_ 696 KAE_EDK1PanicBtnPressSt 0;
BA_ "GatewayedSignals" SG_ 696 KAE_EDK1PanicBtnPressSt 0;
BA_ "GenSigInactiveValue" SG_ 696 KAE_EDK1PanicBtnPressSt 0;
BA_ "GenSigInvalidValue" SG_ 696 KAE_EDK1PanicBtnPressSt 0;
BA_ "GenSigSendType" SG_ 696 KAE_EDK1PanicBtnPressSt 1;
BA_ "GenSigStartValue" SG_ 696 KAE_EDK1PanicBtnPressSt 0;
BA_ "GenSigTimeoutValue" SG_ 696 KAE_EDK1PanicBtnPressSt 0;
BA_ "Remark" SG_ 696 KAE_EDK1PanicBtnPressSt "";
BA_ "EventCommandSignal" SG_ 696 KAE_EDK1User_definedBtnPressSt 0;
BA_ "GatewayedSignals" SG_ 696 KAE_EDK1User_definedBtnPressSt 0;
BA_ "GenSigInactiveValue" SG_ 696 KAE_EDK1User_definedBtnPressSt 0;
BA_ "GenSigInvalidValue" SG_ 696 KAE_EDK1User_definedBtnPressSt 0;
BA_ "GenSigSendType" SG_ 696 KAE_EDK1User_definedBtnPressSt 1;
BA_ "GenSigStartValue" SG_ 696 KAE_EDK1User_definedBtnPressSt 0;
BA_ "GenSigTimeoutValue" SG_ 696 KAE_EDK1User_definedBtnPressSt 0;
BA_ "Remark" SG_ 696 KAE_EDK1User_definedBtnPressSt "";
BA_ "EventCommandSignal" SG_ 696 KAE_EDK2UnlockBtnPressSt 0;
BA_ "GatewayedSignals" SG_ 696 KAE_EDK2UnlockBtnPressSt 0;
BA_ "GenSigInactiveValue" SG_ 696 KAE_EDK2UnlockBtnPressSt 0;
BA_ "GenSigInvalidValue" SG_ 696 KAE_EDK2UnlockBtnPressSt 0;
BA_ "GenSigSendType" SG_ 696 KAE_EDK2UnlockBtnPressSt 1;
BA_ "GenSigStartValue" SG_ 696 KAE_EDK2UnlockBtnPressSt 0;
BA_ "GenSigTimeoutValue" SG_ 696 KAE_EDK2UnlockBtnPressSt 0;
BA_ "Remark" SG_ 696 KAE_EDK2UnlockBtnPressSt "";
BA_ "EventCommandSignal" SG_ 696 KAE_EDK2LockBtnPressSt 0;
BA_ "GatewayedSignals" SG_ 696 KAE_EDK2LockBtnPressSt 0;
BA_ "GenSigInactiveValue" SG_ 696 KAE_EDK2LockBtnPressSt 0;
BA_ "GenSigInvalidValue" SG_ 696 KAE_EDK2LockBtnPressSt 0;
BA_ "GenSigSendType" SG_ 696 KAE_EDK2LockBtnPressSt 1;
BA_ "GenSigStartValue" SG_ 696 KAE_EDK2LockBtnPressSt 0;
BA_ "GenSigTimeoutValue" SG_ 696 KAE_EDK2LockBtnPressSt 0;
BA_ "Remark" SG_ 696 KAE_EDK2LockBtnPressSt "";
BA_ "EventCommandSignal" SG_ 696 KAE_EDK2RESBtnPressSt 0;
BA_ "GatewayedSignals" SG_ 696 KAE_EDK2RESBtnPressSt 0;
BA_ "GenSigInactiveValue" SG_ 696 KAE_EDK2RESBtnPressSt 0;
BA_ "GenSigInvalidValue" SG_ 696 KAE_EDK2RESBtnPressSt 0;
BA_ "GenSigSendType" SG_ 696 KAE_EDK2RESBtnPressSt 1;
BA_ "GenSigStartValue" SG_ 696 KAE_EDK2RESBtnPressSt 0;
BA_ "GenSigTimeoutValue" SG_ 696 KAE_EDK2RESBtnPressSt 0;
BA_ "Remark" SG_ 696 KAE_EDK2RESBtnPressSt "";
BA_ "EventCommandSignal" SG_ 696 KAE_EDK2PSD_LBtnPressSt 0;
BA_ "GatewayedSignals" SG_ 696 KAE_EDK2PSD_LBtnPressSt 0;
BA_ "GenSigInactiveValue" SG_ 696 KAE_EDK2PSD_LBtnPressSt 0;
BA_ "GenSigInvalidValue" SG_ 696 KAE_EDK2PSD_LBtnPressSt 0;
BA_ "GenSigSendType" SG_ 696 KAE_EDK2PSD_LBtnPressSt 1;
BA_ "GenSigStartValue" SG_ 696 KAE_EDK2PSD_LBtnPressSt 0;
BA_ "GenSigTimeoutValue" SG_ 696 KAE_EDK2PSD_LBtnPressSt 0;
BA_ "Remark" SG_ 696 KAE_EDK2PSD_LBtnPressSt "";
BA_ "EventCommandSignal" SG_ 696 KAE_EDK2PSD_RBtnPressSt 0;
BA_ "GatewayedSignals" SG_ 696 KAE_EDK2PSD_RBtnPressSt 0;
BA_ "GenSigInactiveValue" SG_ 696 KAE_EDK2PSD_RBtnPressSt 0;
BA_ "GenSigInvalidValue" SG_ 696 KAE_EDK2PSD_RBtnPressSt 0;
BA_ "GenSigSendType" SG_ 696 KAE_EDK2PSD_RBtnPressSt 1;
BA_ "GenSigStartValue" SG_ 696 KAE_EDK2PSD_RBtnPressSt 0;
BA_ "GenSigTimeoutValue" SG_ 696 KAE_EDK2PSD_RBtnPressSt 0;
BA_ "Remark" SG_ 696 KAE_EDK2PSD_RBtnPressSt "";
BA_ "EventCommandSignal" SG_ 696 KAE_EDK2TrunkBtnPressSt 0;
BA_ "GatewayedSignals" SG_ 696 KAE_EDK2TrunkBtnPressSt 0;
BA_ "GenSigInactiveValue" SG_ 696 KAE_EDK2TrunkBtnPressSt 0;
BA_ "GenSigInvalidValue" SG_ 696 KAE_EDK2TrunkBtnPressSt 0;
BA_ "GenSigSendType" SG_ 696 KAE_EDK2TrunkBtnPressSt 1;
BA_ "GenSigStartValue" SG_ 696 KAE_EDK2TrunkBtnPressSt 0;
BA_ "GenSigTimeoutValue" SG_ 696 KAE_EDK2TrunkBtnPressSt 0;
BA_ "Remark" SG_ 696 KAE_EDK2TrunkBtnPressSt "";
BA_ "EventCommandSignal" SG_ 696 KAE_EDK2PanicBtnPressSt 0;
BA_ "GatewayedSignals" SG_ 696 KAE_EDK2PanicBtnPressSt 0;
BA_ "GenSigInactiveValue" SG_ 696 KAE_EDK2PanicBtnPressSt 0;
BA_ "GenSigInvalidValue" SG_ 696 KAE_EDK2PanicBtnPressSt 0;
BA_ "GenSigSendType" SG_ 696 KAE_EDK2PanicBtnPressSt 1;
BA_ "GenSigStartValue" SG_ 696 KAE_EDK2PanicBtnPressSt 0;
BA_ "GenSigTimeoutValue" SG_ 696 KAE_EDK2PanicBtnPressSt 0;
BA_ "Remark" SG_ 696 KAE_EDK2PanicBtnPressSt "";
BA_ "EventCommandSignal" SG_ 696 KAE_EDK2User_definedBtnPressSt 0;
BA_ "GatewayedSignals" SG_ 696 KAE_EDK2User_definedBtnPressSt 0;
BA_ "GenSigInactiveValue" SG_ 696 KAE_EDK2User_definedBtnPressSt 0;
BA_ "GenSigInvalidValue" SG_ 696 KAE_EDK2User_definedBtnPressSt 0;
BA_ "GenSigSendType" SG_ 696 KAE_EDK2User_definedBtnPressSt 1;
BA_ "GenSigStartValue" SG_ 696 KAE_EDK2User_definedBtnPressSt 0;
BA_ "GenSigTimeoutValue" SG_ 696 KAE_EDK2User_definedBtnPressSt 0;
BA_ "Remark" SG_ 696 KAE_EDK2User_definedBtnPressSt "";
BA_ "EventCommandSignal" SG_ 696 KAE_EDK3UnlockBtnPressSt 0;
BA_ "GatewayedSignals" SG_ 696 KAE_EDK3UnlockBtnPressSt 0;
BA_ "GenSigInactiveValue" SG_ 696 KAE_EDK3UnlockBtnPressSt 0;
BA_ "GenSigInvalidValue" SG_ 696 KAE_EDK3UnlockBtnPressSt 0;
BA_ "GenSigSendType" SG_ 696 KAE_EDK3UnlockBtnPressSt 1;
BA_ "GenSigStartValue" SG_ 696 KAE_EDK3UnlockBtnPressSt 0;
BA_ "GenSigTimeoutValue" SG_ 696 KAE_EDK3UnlockBtnPressSt 0;
BA_ "Remark" SG_ 696 KAE_EDK3UnlockBtnPressSt "";
BA_ "EventCommandSignal" SG_ 696 KAE_EDK3LockBtnPressSt 0;
BA_ "GatewayedSignals" SG_ 696 KAE_EDK3LockBtnPressSt 0;
BA_ "GenSigInactiveValue" SG_ 696 KAE_EDK3LockBtnPressSt 0;
BA_ "GenSigInvalidValue" SG_ 696 KAE_EDK3LockBtnPressSt 0;
BA_ "GenSigSendType" SG_ 696 KAE_EDK3LockBtnPressSt 1;
BA_ "GenSigStartValue" SG_ 696 KAE_EDK3LockBtnPressSt 0;
BA_ "GenSigTimeoutValue" SG_ 696 KAE_EDK3LockBtnPressSt 0;
BA_ "Remark" SG_ 696 KAE_EDK3LockBtnPressSt "";
BA_ "EventCommandSignal" SG_ 696 KAE_EDK3RESBtnPressSt 0;
BA_ "GatewayedSignals" SG_ 696 KAE_EDK3RESBtnPressSt 0;
BA_ "GenSigInactiveValue" SG_ 696 KAE_EDK3RESBtnPressSt 0;
BA_ "GenSigInvalidValue" SG_ 696 KAE_EDK3RESBtnPressSt 0;
BA_ "GenSigSendType" SG_ 696 KAE_EDK3RESBtnPressSt 1;
BA_ "GenSigStartValue" SG_ 696 KAE_EDK3RESBtnPressSt 0;
BA_ "GenSigTimeoutValue" SG_ 696 KAE_EDK3RESBtnPressSt 0;
BA_ "Remark" SG_ 696 KAE_EDK3RESBtnPressSt "";
BA_ "EventCommandSignal" SG_ 696 KAE_EDK3PSD_LBtnPressSt 0;
BA_ "GatewayedSignals" SG_ 696 KAE_EDK3PSD_LBtnPressSt 0;
BA_ "GenSigInactiveValue" SG_ 696 KAE_EDK3PSD_LBtnPressSt 0;
BA_ "GenSigInvalidValue" SG_ 696 KAE_EDK3PSD_LBtnPressSt 0;
BA_ "GenSigSendType" SG_ 696 KAE_EDK3PSD_LBtnPressSt 1;
BA_ "GenSigStartValue" SG_ 696 KAE_EDK3PSD_LBtnPressSt 0;
BA_ "GenSigTimeoutValue" SG_ 696 KAE_EDK3PSD_LBtnPressSt 0;
BA_ "Remark" SG_ 696 KAE_EDK3PSD_LBtnPressSt "";
BA_ "EventCommandSignal" SG_ 696 KAE_EDK3PSD_RBtnPressSt 0;
BA_ "GatewayedSignals" SG_ 696 KAE_EDK3PSD_RBtnPressSt 0;
BA_ "GenSigInactiveValue" SG_ 696 KAE_EDK3PSD_RBtnPressSt 0;
BA_ "GenSigInvalidValue" SG_ 696 KAE_EDK3PSD_RBtnPressSt 0;
BA_ "GenSigSendType" SG_ 696 KAE_EDK3PSD_RBtnPressSt 1;
BA_ "GenSigStartValue" SG_ 696 KAE_EDK3PSD_RBtnPressSt 0;
BA_ "GenSigTimeoutValue" SG_ 696 KAE_EDK3PSD_RBtnPressSt 0;
BA_ "Remark" SG_ 696 KAE_EDK3PSD_RBtnPressSt "";
BA_ "EventCommandSignal" SG_ 696 KAE_EDK3TrunkBtnPressSt 0;
BA_ "GatewayedSignals" SG_ 696 KAE_EDK3TrunkBtnPressSt 0;
BA_ "GenSigInactiveValue" SG_ 696 KAE_EDK3TrunkBtnPressSt 0;
BA_ "GenSigInvalidValue" SG_ 696 KAE_EDK3TrunkBtnPressSt 0;
BA_ "GenSigSendType" SG_ 696 KAE_EDK3TrunkBtnPressSt 1;
BA_ "GenSigStartValue" SG_ 696 KAE_EDK3TrunkBtnPressSt 0;
BA_ "GenSigTimeoutValue" SG_ 696 KAE_EDK3TrunkBtnPressSt 0;
BA_ "Remark" SG_ 696 KAE_EDK3TrunkBtnPressSt "";
BA_ "EventCommandSignal" SG_ 696 KAE_EDK3PanicBtnPressSt 0;
BA_ "GatewayedSignals" SG_ 696 KAE_EDK3PanicBtnPressSt 0;
BA_ "GenSigInactiveValue" SG_ 696 KAE_EDK3PanicBtnPressSt 0;
BA_ "GenSigInvalidValue" SG_ 696 KAE_EDK3PanicBtnPressSt 0;
BA_ "GenSigSendType" SG_ 696 KAE_EDK3PanicBtnPressSt 1;
BA_ "GenSigStartValue" SG_ 696 KAE_EDK3PanicBtnPressSt 0;
BA_ "GenSigTimeoutValue" SG_ 696 KAE_EDK3PanicBtnPressSt 0;
BA_ "Remark" SG_ 696 KAE_EDK3PanicBtnPressSt "";
BA_ "EventCommandSignal" SG_ 696 KAE_EDK3User_definedBtnPressSt 0;
BA_ "GatewayedSignals" SG_ 696 KAE_EDK3User_definedBtnPressSt 0;
BA_ "GenSigInactiveValue" SG_ 696 KAE_EDK3User_definedBtnPressSt 0;
BA_ "GenSigInvalidValue" SG_ 696 KAE_EDK3User_definedBtnPressSt 0;
BA_ "GenSigSendType" SG_ 696 KAE_EDK3User_definedBtnPressSt 1;
BA_ "GenSigStartValue" SG_ 696 KAE_EDK3User_definedBtnPressSt 0;
BA_ "GenSigTimeoutValue" SG_ 696 KAE_EDK3User_definedBtnPressSt 0;
BA_ "Remark" SG_ 696 KAE_EDK3User_definedBtnPressSt "";
BA_ "EventCommandSignal" SG_ 696 KAE_RPADirectionSel 0;
BA_ "GatewayedSignals" SG_ 696 KAE_RPADirectionSel 0;
BA_ "GenSigInactiveValue" SG_ 696 KAE_RPADirectionSel 0;
BA_ "GenSigInvalidValue" SG_ 696 KAE_RPADirectionSel 0;
BA_ "GenSigSendType" SG_ 696 KAE_RPADirectionSel 1;
BA_ "GenSigStartValue" SG_ 696 KAE_RPADirectionSel 0;
BA_ "GenSigTimeoutValue" SG_ 696 KAE_RPADirectionSel 0;
BA_ "Remark" SG_ 696 KAE_RPADirectionSel "";
BA_ "EventCommandSignal" SG_ 696 KAE_RPAmode 0;
BA_ "GatewayedSignals" SG_ 696 KAE_RPAmode 0;
BA_ "GenSigInactiveValue" SG_ 696 KAE_RPAmode 0;
BA_ "GenSigInvalidValue" SG_ 696 KAE_RPAmode 0;
BA_ "GenSigSendType" SG_ 696 KAE_RPAmode 1;
BA_ "GenSigStartValue" SG_ 696 KAE_RPAmode 0;
BA_ "GenSigTimeoutValue" SG_ 696 KAE_RPAmode 0;
BA_ "Remark" SG_ 696 KAE_RPAmode "";
BA_ "EventCommandSignal" SG_ 696 KAE_RPADeviceSt 0;
BA_ "GatewayedSignals" SG_ 696 KAE_RPADeviceSt 0;
BA_ "GenSigInactiveValue" SG_ 696 KAE_RPADeviceSt 0;
BA_ "GenSigInvalidValue" SG_ 696 KAE_RPADeviceSt 0;
BA_ "GenSigSendType" SG_ 696 KAE_RPADeviceSt 1;
BA_ "GenSigStartValue" SG_ 696 KAE_RPADeviceSt 0;
BA_ "GenSigTimeoutValue" SG_ 696 KAE_RPADeviceSt 0;
BA_ "Remark" SG_ 696 KAE_RPADeviceSt "";
BA_ "EventCommandSignal" SG_ 696 KAE_PhoneBatt 0;
BA_ "GatewayedSignals" SG_ 696 KAE_PhoneBatt 0;
BA_ "GenSigInactiveValue" SG_ 696 KAE_PhoneBatt 0;
BA_ "GenSigInvalidValue" SG_ 696 KAE_PhoneBatt 0;
BA_ "GenSigSendType" SG_ 696 KAE_PhoneBatt 1;
BA_ "GenSigStartValue" SG_ 696 KAE_PhoneBatt 0;
BA_ "GenSigTimeoutValue" SG_ 696 KAE_PhoneBatt 0;
BA_ "Remark" SG_ 696 KAE_PhoneBatt "";
BA_ "EventCommandSignal" SG_ 696 KAE_RPACheckReq 0;
BA_ "GatewayedSignals" SG_ 696 KAE_RPACheckReq 0;
BA_ "GenSigInactiveValue" SG_ 696 KAE_RPACheckReq 0;
BA_ "GenSigInvalidValue" SG_ 696 KAE_RPACheckReq 0;
BA_ "GenSigSendType" SG_ 696 KAE_RPACheckReq 1;
BA_ "GenSigStartValue" SG_ 696 KAE_RPACheckReq 0;
BA_ "GenSigTimeoutValue" SG_ 696 KAE_RPACheckReq 0;
BA_ "Remark" SG_ 696 KAE_RPACheckReq "";
BA_ "EventCommandSignal" SG_ 696 KAE_RPAKeyPstSt 0;
BA_ "GatewayedSignals" SG_ 696 KAE_RPAKeyPstSt 0;
BA_ "GenSigInactiveValue" SG_ 696 KAE_RPAKeyPstSt 0;
BA_ "GenSigInvalidValue" SG_ 696 KAE_RPAKeyPstSt 0;
BA_ "GenSigSendType" SG_ 696 KAE_RPAKeyPstSt 1;
BA_ "GenSigStartValue" SG_ 696 KAE_RPAKeyPstSt 0;
BA_ "GenSigTimeoutValue" SG_ 696 KAE_RPAKeyPstSt 0;
BA_ "Remark" SG_ 696 KAE_RPAKeyPstSt "";
BA_ "EventCommandSignal" SG_ 696 KAE_RPADeviceFailReason 0;
BA_ "GatewayedSignals" SG_ 696 KAE_RPADeviceFailReason 0;
BA_ "GenSigInactiveValue" SG_ 696 KAE_RPADeviceFailReason 0;
BA_ "GenSigInvalidValue" SG_ 696 KAE_RPADeviceFailReason 0;
BA_ "GenSigSendType" SG_ 696 KAE_RPADeviceFailReason 1;
BA_ "GenSigStartValue" SG_ 696 KAE_RPADeviceFailReason 0;
BA_ "GenSigTimeoutValue" SG_ 696 KAE_RPADeviceFailReason 0;
BA_ "Remark" SG_ 696 KAE_RPADeviceFailReason "";
BA_ "EventCommandSignal" SG_ 696 KAE_RPABtnSt 0;
BA_ "GatewayedSignals" SG_ 696 KAE_RPABtnSt 0;
BA_ "GenSigInactiveValue" SG_ 696 KAE_RPABtnSt 0;
BA_ "GenSigInvalidValue" SG_ 696 KAE_RPABtnSt 0;
BA_ "GenSigSendType" SG_ 696 KAE_RPABtnSt 1;
BA_ "GenSigStartValue" SG_ 696 KAE_RPABtnSt 0;
BA_ "GenSigTimeoutValue" SG_ 696 KAE_RPABtnSt 0;
BA_ "Remark" SG_ 696 KAE_RPABtnSt "";
BA_ "EventCommandSignal" SG_ 696 KAE_ForRPAFailReason 0;
BA_ "GatewayedSignals" SG_ 696 KAE_ForRPAFailReason 0;
BA_ "GenSigInactiveValue" SG_ 696 KAE_ForRPAFailReason 0;
BA_ "GenSigInvalidValue" SG_ 696 KAE_ForRPAFailReason 0;
BA_ "GenSigSendType" SG_ 696 KAE_ForRPAFailReason 1;
BA_ "GenSigStartValue" SG_ 696 KAE_ForRPAFailReason 0;
BA_ "GenSigTimeoutValue" SG_ 696 KAE_ForRPAFailReason 0;
BA_ "Remark" SG_ 696 KAE_ForRPAFailReason "";
BA_ "EventCommandSignal" SG_ 696 KAE_RPABtnStVD 0;
BA_ "GatewayedSignals" SG_ 696 KAE_RPABtnStVD 0;
BA_ "GenSigInactiveValue" SG_ 696 KAE_RPABtnStVD 0;
BA_ "GenSigInvalidValue" SG_ 696 KAE_RPABtnStVD 0;
BA_ "GenSigSendType" SG_ 696 KAE_RPABtnStVD 1;
BA_ "GenSigStartValue" SG_ 696 KAE_RPABtnStVD 0;
BA_ "GenSigTimeoutValue" SG_ 696 KAE_RPABtnStVD 0;
BA_ "Remark" SG_ 696 KAE_RPABtnStVD "";
BA_ "EventCommandSignal" SG_ 696 KAE_RPACancelBtnSt 0;
BA_ "GatewayedSignals" SG_ 696 KAE_RPACancelBtnSt 0;
BA_ "GenSigInactiveValue" SG_ 696 KAE_RPACancelBtnSt 0;
BA_ "GenSigInvalidValue" SG_ 696 KAE_RPACancelBtnSt 0;
BA_ "GenSigSendType" SG_ 696 KAE_RPACancelBtnSt 1;
BA_ "GenSigStartValue" SG_ 696 KAE_RPACancelBtnSt 0;
BA_ "GenSigTimeoutValue" SG_ 696 KAE_RPACancelBtnSt 0;
BA_ "Remark" SG_ 696 KAE_RPACancelBtnSt "";
BA_ "EventCommandSignal" SG_ 696 KAE_RPACancelBtnStVD 0;
BA_ "GatewayedSignals" SG_ 696 KAE_RPACancelBtnStVD 0;
BA_ "GenSigInactiveValue" SG_ 696 KAE_RPACancelBtnStVD 0;
BA_ "GenSigInvalidValue" SG_ 696 KAE_RPACancelBtnStVD 0;
BA_ "GenSigSendType" SG_ 696 KAE_RPACancelBtnStVD 1;
BA_ "GenSigStartValue" SG_ 696 KAE_RPACancelBtnStVD 0;
BA_ "GenSigTimeoutValue" SG_ 696 KAE_RPACancelBtnStVD 0;
BA_ "Remark" SG_ 696 KAE_RPACancelBtnStVD "";
BA_ "EventCommandSignal" SG_ 696 KAE_ComSDKUBouncesSt 0;
BA_ "GatewayedSignals" SG_ 696 KAE_ComSDKUBouncesSt 0;
BA_ "GenSigInactiveValue" SG_ 696 KAE_ComSDKUBouncesSt 0;
BA_ "GenSigInvalidValue" SG_ 696 KAE_ComSDKUBouncesSt 0;
BA_ "GenSigSendType" SG_ 696 KAE_ComSDKUBouncesSt 1;
BA_ "GenSigStartValue" SG_ 696 KAE_ComSDKUBouncesSt 0;
BA_ "GenSigTimeoutValue" SG_ 696 KAE_ComSDKUBouncesSt 0;
BA_ "Remark" SG_ 696 KAE_ComSDKUBouncesSt "";
BA_ "EventCommandSignal" SG_ 696 KAE_HAVPCancelParking 0;
BA_ "GatewayedSignals" SG_ 696 KAE_HAVPCancelParking 0;
BA_ "GenSigInactiveValue" SG_ 696 KAE_HAVPCancelParking 0;
BA_ "GenSigInvalidValue" SG_ 696 KAE_HAVPCancelParking 0;
BA_ "GenSigSendType" SG_ 696 KAE_HAVPCancelParking 1;
BA_ "GenSigStartValue" SG_ 696 KAE_HAVPCancelParking 0;
BA_ "GenSigTimeoutValue" SG_ 696 KAE_HAVPCancelParking 0;
BA_ "Remark" SG_ 696 KAE_HAVPCancelParking "";
BA_ "EventCommandSignal" SG_ 696 KAE_HAVPDisclaimerAgree 0;
BA_ "GatewayedSignals" SG_ 696 KAE_HAVPDisclaimerAgree 0;
BA_ "GenSigInactiveValue" SG_ 696 KAE_HAVPDisclaimerAgree 0;
BA_ "GenSigInvalidValue" SG_ 696 KAE_HAVPDisclaimerAgree 0;
BA_ "GenSigSendType" SG_ 696 KAE_HAVPDisclaimerAgree 1;
BA_ "GenSigStartValue" SG_ 696 KAE_HAVPDisclaimerAgree 0;
BA_ "GenSigTimeoutValue" SG_ 696 KAE_HAVPDisclaimerAgree 0;
BA_ "Remark" SG_ 696 KAE_HAVPDisclaimerAgree "";
BA_ "EventCommandSignal" SG_ 696 KAE_HAVPPathSelect 0;
BA_ "GatewayedSignals" SG_ 696 KAE_HAVPPathSelect 0;
BA_ "GenSigInactiveValue" SG_ 696 KAE_HAVPPathSelect 0;
BA_ "GenSigInvalidValue" SG_ 696 KAE_HAVPPathSelect 0;
BA_ "GenSigSendType" SG_ 696 KAE_HAVPPathSelect 1;
BA_ "GenSigStartValue" SG_ 696 KAE_HAVPPathSelect 0;
BA_ "GenSigTimeoutValue" SG_ 696 KAE_HAVPPathSelect 0;
BA_ "Remark" SG_ 696 KAE_HAVPPathSelect "";
BA_ "EventCommandSignal" SG_ 696 KAE_RPAResponse 0;
BA_ "GatewayedSignals" SG_ 696 KAE_RPAResponse 0;
BA_ "GenSigInactiveValue" SG_ 696 KAE_RPAResponse 0;
BA_ "GenSigInvalidValue" SG_ 696 KAE_RPAResponse 0;
BA_ "GenSigSendType" SG_ 696 KAE_RPAResponse 1;
BA_ "GenSigStartValue" SG_ 696 KAE_RPAResponse 0;
BA_ "GenSigTimeoutValue" SG_ 696 KAE_RPAResponse 0;
BA_ "Remark" SG_ 696 KAE_RPAResponse "";
BA_ "EventCommandSignal" SG_ 696 KAE_HAVPUWBZone 0;
BA_ "GatewayedSignals" SG_ 696 KAE_HAVPUWBZone 0;
BA_ "GenSigInactiveValue" SG_ 696 KAE_HAVPUWBZone 0;
BA_ "GenSigInvalidValue" SG_ 696 KAE_HAVPUWBZone 0;
BA_ "GenSigSendType" SG_ 696 KAE_HAVPUWBZone 1;
BA_ "GenSigStartValue" SG_ 696 KAE_HAVPUWBZone 0;
BA_ "GenSigTimeoutValue" SG_ 696 KAE_HAVPUWBZone 0;
BA_ "Remark" SG_ 696 KAE_HAVPUWBZone "";
BA_ "EventCommandSignal" SG_ 696 KAE_HAVPUWBXPosition 0;
BA_ "GatewayedSignals" SG_ 696 KAE_HAVPUWBXPosition 0;
BA_ "GenSigInactiveValue" SG_ 696 KAE_HAVPUWBXPosition 0;
BA_ "GenSigInvalidValue" SG_ 696 KAE_HAVPUWBXPosition 0;
BA_ "GenSigSendType" SG_ 696 KAE_HAVPUWBXPosition 1;
BA_ "GenSigStartValue" SG_ 696 KAE_HAVPUWBXPosition 0;
BA_ "GenSigTimeoutValue" SG_ 696 KAE_HAVPUWBXPosition 0;
BA_ "Remark" SG_ 696 KAE_HAVPUWBXPosition "";
BA_ "EventCommandSignal" SG_ 696 KAE_HAVPUWBYPosition 0;
BA_ "GatewayedSignals" SG_ 696 KAE_HAVPUWBYPosition 0;
BA_ "GenSigInactiveValue" SG_ 696 KAE_HAVPUWBYPosition 0;
BA_ "GenSigInvalidValue" SG_ 696 KAE_HAVPUWBYPosition 0;
BA_ "GenSigSendType" SG_ 696 KAE_HAVPUWBYPosition 1;
BA_ "GenSigStartValue" SG_ 696 KAE_HAVPUWBYPosition 0;
BA_ "GenSigTimeoutValue" SG_ 696 KAE_HAVPUWBYPosition 0;
BA_ "Remark" SG_ 696 KAE_HAVPUWBYPosition "";
BA_ "EventCommandSignal" SG_ 696 KAE_UnlockDoorReq 0;
BA_ "GatewayedSignals" SG_ 696 KAE_UnlockDoorReq 0;
BA_ "GenSigInactiveValue" SG_ 696 KAE_UnlockDoorReq 0;
BA_ "GenSigInvalidValue" SG_ 696 KAE_UnlockDoorReq 0;
BA_ "GenSigSendType" SG_ 696 KAE_UnlockDoorReq 1;
BA_ "GenSigStartValue" SG_ 696 KAE_UnlockDoorReq 0;
BA_ "GenSigTimeoutValue" SG_ 696 KAE_UnlockDoorReq 0;
BA_ "Remark" SG_ 696 KAE_UnlockDoorReq "";
BA_ "EventCommandSignal" SG_ 696 KAE_UnlockDoorReqVD 0;
BA_ "GatewayedSignals" SG_ 696 KAE_UnlockDoorReqVD 0;
BA_ "GenSigInactiveValue" SG_ 696 KAE_UnlockDoorReqVD 0;
BA_ "GenSigInvalidValue" SG_ 696 KAE_UnlockDoorReqVD 0;
BA_ "GenSigSendType" SG_ 696 KAE_UnlockDoorReqVD 1;
BA_ "GenSigStartValue" SG_ 696 KAE_UnlockDoorReqVD 0;
BA_ "GenSigTimeoutValue" SG_ 696 KAE_UnlockDoorReqVD 0;
BA_ "Remark" SG_ 696 KAE_UnlockDoorReqVD "";
BA_ "EventCommandSignal" SG_ 696 KAE_LockDoorReq 0;
BA_ "GatewayedSignals" SG_ 696 KAE_LockDoorReq 0;
BA_ "GenSigInactiveValue" SG_ 696 KAE_LockDoorReq 0;
BA_ "GenSigInvalidValue" SG_ 696 KAE_LockDoorReq 0;
BA_ "GenSigSendType" SG_ 696 KAE_LockDoorReq 1;
BA_ "GenSigStartValue" SG_ 696 KAE_LockDoorReq 0;
BA_ "GenSigTimeoutValue" SG_ 696 KAE_LockDoorReq 0;
BA_ "Remark" SG_ 696 KAE_LockDoorReq "";
BA_ "EventCommandSignal" SG_ 696 KAE_LockDoorReqVD 0;
BA_ "GatewayedSignals" SG_ 696 KAE_LockDoorReqVD 0;
BA_ "GenSigInactiveValue" SG_ 696 KAE_LockDoorReqVD 0;
BA_ "GenSigInvalidValue" SG_ 696 KAE_LockDoorReqVD 0;
BA_ "GenSigSendType" SG_ 696 KAE_LockDoorReqVD 1;
BA_ "GenSigStartValue" SG_ 696 KAE_LockDoorReqVD 0;
BA_ "GenSigTimeoutValue" SG_ 696 KAE_LockDoorReqVD 0;
BA_ "Remark" SG_ 696 KAE_LockDoorReqVD "";
BA_ "EventCommandSignal" SG_ 696 KAE_WindowsCloseReq 0;
BA_ "GatewayedSignals" SG_ 696 KAE_WindowsCloseReq 0;
BA_ "GenSigInactiveValue" SG_ 696 KAE_WindowsCloseReq 0;
BA_ "GenSigInvalidValue" SG_ 696 KAE_WindowsCloseReq 0;
BA_ "GenSigSendType" SG_ 696 KAE_WindowsCloseReq 1;
BA_ "GenSigStartValue" SG_ 696 KAE_WindowsCloseReq 0;
BA_ "GenSigTimeoutValue" SG_ 696 KAE_WindowsCloseReq 0;
BA_ "Remark" SG_ 696 KAE_WindowsCloseReq "";
BA_ "EventCommandSignal" SG_ 696 KAE_WindowsCloseReqVD 0;
BA_ "GatewayedSignals" SG_ 696 KAE_WindowsCloseReqVD 0;
BA_ "GenSigInactiveValue" SG_ 696 KAE_WindowsCloseReqVD 0;
BA_ "GenSigInvalidValue" SG_ 696 KAE_WindowsCloseReqVD 0;
BA_ "GenSigSendType" SG_ 696 KAE_WindowsCloseReqVD 1;
BA_ "GenSigStartValue" SG_ 696 KAE_WindowsCloseReqVD 0;
BA_ "GenSigTimeoutValue" SG_ 696 KAE_WindowsCloseReqVD 0;
BA_ "Remark" SG_ 696 KAE_WindowsCloseReqVD "";
BA_ "EventCommandSignal" SG_ 696 KAE_WindowsOpenReq 0;
BA_ "GatewayedSignals" SG_ 696 KAE_WindowsOpenReq 0;
BA_ "GenSigInactiveValue" SG_ 696 KAE_WindowsOpenReq 0;
BA_ "GenSigInvalidValue" SG_ 696 KAE_WindowsOpenReq 0;
BA_ "GenSigSendType" SG_ 696 KAE_WindowsOpenReq 1;
BA_ "GenSigStartValue" SG_ 696 KAE_WindowsOpenReq 0;
BA_ "GenSigTimeoutValue" SG_ 696 KAE_WindowsOpenReq 0;
BA_ "Remark" SG_ 696 KAE_WindowsOpenReq "";
BA_ "EventCommandSignal" SG_ 696 KAE_WindowsOpenReqVD 0;
BA_ "GatewayedSignals" SG_ 696 KAE_WindowsOpenReqVD 0;
BA_ "GenSigInactiveValue" SG_ 696 KAE_WindowsOpenReqVD 0;
BA_ "GenSigInvalidValue" SG_ 696 KAE_WindowsOpenReqVD 0;
BA_ "GenSigSendType" SG_ 696 KAE_WindowsOpenReqVD 1;
BA_ "GenSigStartValue" SG_ 696 KAE_WindowsOpenReqVD 0;
BA_ "GenSigTimeoutValue" SG_ 696 KAE_WindowsOpenReqVD 0;
BA_ "Remark" SG_ 696 KAE_WindowsOpenReqVD "";
BA_ "EventCommandSignal" SG_ 696 KAE_TrunkUnlockReq 0;
BA_ "GatewayedSignals" SG_ 696 KAE_TrunkUnlockReq 0;
BA_ "GenSigInactiveValue" SG_ 696 KAE_TrunkUnlockReq 0;
BA_ "GenSigInvalidValue" SG_ 696 KAE_TrunkUnlockReq 0;
BA_ "GenSigSendType" SG_ 696 KAE_TrunkUnlockReq 1;
BA_ "GenSigStartValue" SG_ 696 KAE_TrunkUnlockReq 0;
BA_ "GenSigTimeoutValue" SG_ 696 KAE_TrunkUnlockReq 0;
BA_ "Remark" SG_ 696 KAE_TrunkUnlockReq "";
BA_ "EventCommandSignal" SG_ 696 KAE_TrunkUnlockReqVD 0;
BA_ "GatewayedSignals" SG_ 696 KAE_TrunkUnlockReqVD 0;
BA_ "GenSigInactiveValue" SG_ 696 KAE_TrunkUnlockReqVD 0;
BA_ "GenSigInvalidValue" SG_ 696 KAE_TrunkUnlockReqVD 0;
BA_ "GenSigSendType" SG_ 696 KAE_TrunkUnlockReqVD 1;
BA_ "GenSigStartValue" SG_ 696 KAE_TrunkUnlockReqVD 0;
BA_ "GenSigTimeoutValue" SG_ 696 KAE_TrunkUnlockReqVD 0;
BA_ "Remark" SG_ 696 KAE_TrunkUnlockReqVD "";
BA_ "EventCommandSignal" SG_ 696 KAE_HoodUnlockReq 0;
BA_ "GatewayedSignals" SG_ 696 KAE_HoodUnlockReq 0;
BA_ "GenSigInactiveValue" SG_ 696 KAE_HoodUnlockReq 0;
BA_ "GenSigInvalidValue" SG_ 696 KAE_HoodUnlockReq 0;
BA_ "GenSigSendType" SG_ 696 KAE_HoodUnlockReq 1;
BA_ "GenSigStartValue" SG_ 696 KAE_HoodUnlockReq 0;
BA_ "GenSigTimeoutValue" SG_ 696 KAE_HoodUnlockReq 0;
BA_ "Remark" SG_ 696 KAE_HoodUnlockReq "";
BA_ "EventCommandSignal" SG_ 696 KAE_HoodUnlockReqVD 0;
BA_ "GatewayedSignals" SG_ 696 KAE_HoodUnlockReqVD 0;
BA_ "GenSigInactiveValue" SG_ 696 KAE_HoodUnlockReqVD 0;
BA_ "GenSigInvalidValue" SG_ 696 KAE_HoodUnlockReqVD 0;
BA_ "GenSigSendType" SG_ 696 KAE_HoodUnlockReqVD 1;
BA_ "GenSigStartValue" SG_ 696 KAE_HoodUnlockReqVD 0;
BA_ "GenSigTimeoutValue" SG_ 696 KAE_HoodUnlockReqVD 0;
BA_ "Remark" SG_ 696 KAE_HoodUnlockReqVD "";
BA_ "EventCommandSignal" SG_ 696 KAE_PLGMOpenReq 0;
BA_ "GatewayedSignals" SG_ 696 KAE_PLGMOpenReq 0;
BA_ "GenSigInactiveValue" SG_ 696 KAE_PLGMOpenReq 0;
BA_ "GenSigInvalidValue" SG_ 696 KAE_PLGMOpenReq 0;
BA_ "GenSigSendType" SG_ 696 KAE_PLGMOpenReq 1;
BA_ "GenSigStartValue" SG_ 696 KAE_PLGMOpenReq 0;
BA_ "GenSigTimeoutValue" SG_ 696 KAE_PLGMOpenReq 0;
BA_ "Remark" SG_ 696 KAE_PLGMOpenReq "";
BA_ "EventCommandSignal" SG_ 696 KAE_PLGMOpenReqVD 0;
BA_ "GatewayedSignals" SG_ 696 KAE_PLGMOpenReqVD 0;
BA_ "GenSigInactiveValue" SG_ 696 KAE_PLGMOpenReqVD 0;
BA_ "GenSigInvalidValue" SG_ 696 KAE_PLGMOpenReqVD 0;
BA_ "GenSigSendType" SG_ 696 KAE_PLGMOpenReqVD 1;
BA_ "GenSigStartValue" SG_ 696 KAE_PLGMOpenReqVD 0;
BA_ "GenSigTimeoutValue" SG_ 696 KAE_PLGMOpenReqVD 0;
BA_ "Remark" SG_ 696 KAE_PLGMOpenReqVD "";
BA_ "EventCommandSignal" SG_ 696 KAE_PLGMCloseReq 0;
BA_ "GatewayedSignals" SG_ 696 KAE_PLGMCloseReq 0;
BA_ "GenSigInactiveValue" SG_ 696 KAE_PLGMCloseReq 0;
BA_ "GenSigInvalidValue" SG_ 696 KAE_PLGMCloseReq 0;
BA_ "GenSigSendType" SG_ 696 KAE_PLGMCloseReq 1;
BA_ "GenSigStartValue" SG_ 696 KAE_PLGMCloseReq 0;
BA_ "GenSigTimeoutValue" SG_ 696 KAE_PLGMCloseReq 0;
BA_ "Remark" SG_ 696 KAE_PLGMCloseReq "";
BA_ "EventCommandSignal" SG_ 696 KAE_PLGMCloseReqVD 0;
BA_ "GatewayedSignals" SG_ 696 KAE_PLGMCloseReqVD 0;
BA_ "GenSigInactiveValue" SG_ 696 KAE_PLGMCloseReqVD 0;
BA_ "GenSigInvalidValue" SG_ 696 KAE_PLGMCloseReqVD 0;
BA_ "GenSigSendType" SG_ 696 KAE_PLGMCloseReqVD 1;
BA_ "GenSigStartValue" SG_ 696 KAE_PLGMCloseReqVD 0;
BA_ "GenSigTimeoutValue" SG_ 696 KAE_PLGMCloseReqVD 0;
BA_ "Remark" SG_ 696 KAE_PLGMCloseReqVD "";
BA_ "EventCommandSignal" SG_ 696 KAE_SunRoofOpenReq 0;
BA_ "GatewayedSignals" SG_ 696 KAE_SunRoofOpenReq 0;
BA_ "GenSigInactiveValue" SG_ 696 KAE_SunRoofOpenReq 0;
BA_ "GenSigInvalidValue" SG_ 696 KAE_SunRoofOpenReq 0;
BA_ "GenSigSendType" SG_ 696 KAE_SunRoofOpenReq 1;
BA_ "GenSigStartValue" SG_ 696 KAE_SunRoofOpenReq 0;
BA_ "GenSigTimeoutValue" SG_ 696 KAE_SunRoofOpenReq 0;
BA_ "Remark" SG_ 696 KAE_SunRoofOpenReq "";
BA_ "EventCommandSignal" SG_ 696 KAE_SunRoofOpenReqVD 0;
BA_ "GatewayedSignals" SG_ 696 KAE_SunRoofOpenReqVD 0;
BA_ "GenSigInactiveValue" SG_ 696 KAE_SunRoofOpenReqVD 0;
BA_ "GenSigInvalidValue" SG_ 696 KAE_SunRoofOpenReqVD 0;
BA_ "GenSigSendType" SG_ 696 KAE_SunRoofOpenReqVD 1;
BA_ "GenSigStartValue" SG_ 696 KAE_SunRoofOpenReqVD 0;
BA_ "GenSigTimeoutValue" SG_ 696 KAE_SunRoofOpenReqVD 0;
BA_ "Remark" SG_ 696 KAE_SunRoofOpenReqVD "";
BA_ "EventCommandSignal" SG_ 696 KAE_SunRoofCloseReq 0;
BA_ "GatewayedSignals" SG_ 696 KAE_SunRoofCloseReq 0;
BA_ "GenSigInactiveValue" SG_ 696 KAE_SunRoofCloseReq 0;
BA_ "GenSigInvalidValue" SG_ 696 KAE_SunRoofCloseReq 0;
BA_ "GenSigSendType" SG_ 696 KAE_SunRoofCloseReq 1;
BA_ "GenSigStartValue" SG_ 696 KAE_SunRoofCloseReq 0;
BA_ "GenSigTimeoutValue" SG_ 696 KAE_SunRoofCloseReq 0;
BA_ "Remark" SG_ 696 KAE_SunRoofCloseReq "";
BA_ "EventCommandSignal" SG_ 696 KAE_SunRoofCloseReqVD 0;
BA_ "GatewayedSignals" SG_ 696 KAE_SunRoofCloseReqVD 0;
BA_ "GenSigInactiveValue" SG_ 696 KAE_SunRoofCloseReqVD 0;
BA_ "GenSigInvalidValue" SG_ 696 KAE_SunRoofCloseReqVD 0;
BA_ "GenSigSendType" SG_ 696 KAE_SunRoofCloseReqVD 1;
BA_ "GenSigStartValue" SG_ 696 KAE_SunRoofCloseReqVD 0;
BA_ "GenSigTimeoutValue" SG_ 696 KAE_SunRoofCloseReqVD 0;
BA_ "Remark" SG_ 696 KAE_SunRoofCloseReqVD "";
BA_ "EventCommandSignal" SG_ 696 KAE_PAAReq 0;
BA_ "GatewayedSignals" SG_ 696 KAE_PAAReq 0;
BA_ "GenSigInactiveValue" SG_ 696 KAE_PAAReq 0;
BA_ "GenSigInvalidValue" SG_ 696 KAE_PAAReq 0;
BA_ "GenSigSendType" SG_ 696 KAE_PAAReq 1;
BA_ "GenSigStartValue" SG_ 696 KAE_PAAReq 0;
BA_ "GenSigTimeoutValue" SG_ 696 KAE_PAAReq 0;
BA_ "Remark" SG_ 696 KAE_PAAReq "";
BA_ "EventCommandSignal" SG_ 696 KAE_PAAReqVd 0;
BA_ "GatewayedSignals" SG_ 696 KAE_PAAReqVd 0;
BA_ "GenSigInactiveValue" SG_ 696 KAE_PAAReqVd 0;
BA_ "GenSigInvalidValue" SG_ 696 KAE_PAAReqVd 0;
BA_ "GenSigSendType" SG_ 696 KAE_PAAReqVd 1;
BA_ "GenSigStartValue" SG_ 696 KAE_PAAReqVd 0;
BA_ "GenSigTimeoutValue" SG_ 696 KAE_PAAReqVd 0;
BA_ "Remark" SG_ 696 KAE_PAAReqVd "";
BA_ "EventCommandSignal" SG_ 696 KAE_EDK1UnlockBtnSt 0;
BA_ "GatewayedSignals" SG_ 696 KAE_EDK1UnlockBtnSt 0;
BA_ "GenSigInactiveValue" SG_ 696 KAE_EDK1UnlockBtnSt 0;
BA_ "GenSigInvalidValue" SG_ 696 KAE_EDK1UnlockBtnSt 0;
BA_ "GenSigSendType" SG_ 696 KAE_EDK1UnlockBtnSt 1;
BA_ "GenSigStartValue" SG_ 696 KAE_EDK1UnlockBtnSt 0;
BA_ "GenSigTimeoutValue" SG_ 696 KAE_EDK1UnlockBtnSt 0;
BA_ "Remark" SG_ 696 KAE_EDK1UnlockBtnSt "";
BA_ "EventCommandSignal" SG_ 696 KAE_EDK1LockBtnSt 0;
BA_ "GatewayedSignals" SG_ 696 KAE_EDK1LockBtnSt 0;
BA_ "GenSigInactiveValue" SG_ 696 KAE_EDK1LockBtnSt 0;
BA_ "GenSigInvalidValue" SG_ 696 KAE_EDK1LockBtnSt 0;
BA_ "GenSigSendType" SG_ 696 KAE_EDK1LockBtnSt 1;
BA_ "GenSigStartValue" SG_ 696 KAE_EDK1LockBtnSt 0;
BA_ "GenSigTimeoutValue" SG_ 696 KAE_EDK1LockBtnSt 0;
BA_ "Remark" SG_ 696 KAE_EDK1LockBtnSt "";
BA_ "EventCommandSignal" SG_ 696 KAE_EDK1RESBtnSt 0;
BA_ "GatewayedSignals" SG_ 696 KAE_EDK1RESBtnSt 0;
BA_ "GenSigInactiveValue" SG_ 696 KAE_EDK1RESBtnSt 0;
BA_ "GenSigInvalidValue" SG_ 696 KAE_EDK1RESBtnSt 0;
BA_ "GenSigSendType" SG_ 696 KAE_EDK1RESBtnSt 1;
BA_ "GenSigStartValue" SG_ 696 KAE_EDK1RESBtnSt 0;
BA_ "GenSigTimeoutValue" SG_ 696 KAE_EDK1RESBtnSt 0;
BA_ "Remark" SG_ 696 KAE_EDK1RESBtnSt "";
BA_ "EventCommandSignal" SG_ 696 KAE_EDK1PSD_LBtnSt 0;
BA_ "GatewayedSignals" SG_ 696 KAE_EDK1PSD_LBtnSt 0;
BA_ "GenSigInactiveValue" SG_ 696 KAE_EDK1PSD_LBtnSt 0;
BA_ "GenSigInvalidValue" SG_ 696 KAE_EDK1PSD_LBtnSt 0;
BA_ "GenSigSendType" SG_ 696 KAE_EDK1PSD_LBtnSt 1;
BA_ "GenSigStartValue" SG_ 696 KAE_EDK1PSD_LBtnSt 0;
BA_ "GenSigTimeoutValue" SG_ 696 KAE_EDK1PSD_LBtnSt 0;
BA_ "Remark" SG_ 696 KAE_EDK1PSD_LBtnSt "";
BA_ "EventCommandSignal" SG_ 696 KAE_EDK1PSD_RBtnSt 0;
BA_ "GatewayedSignals" SG_ 696 KAE_EDK1PSD_RBtnSt 0;
BA_ "GenSigInactiveValue" SG_ 696 KAE_EDK1PSD_RBtnSt 0;
BA_ "GenSigInvalidValue" SG_ 696 KAE_EDK1PSD_RBtnSt 0;
BA_ "GenSigSendType" SG_ 696 KAE_EDK1PSD_RBtnSt 1;
BA_ "GenSigStartValue" SG_ 696 KAE_EDK1PSD_RBtnSt 0;
BA_ "GenSigTimeoutValue" SG_ 696 KAE_EDK1PSD_RBtnSt 0;
BA_ "Remark" SG_ 696 KAE_EDK1PSD_RBtnSt "";
BA_ "EventCommandSignal" SG_ 696 KAE_EDK1TrunkBtnSt 0;
BA_ "GatewayedSignals" SG_ 696 KAE_EDK1TrunkBtnSt 0;
BA_ "GenSigInactiveValue" SG_ 696 KAE_EDK1TrunkBtnSt 0;
BA_ "GenSigInvalidValue" SG_ 696 KAE_EDK1TrunkBtnSt 0;
BA_ "GenSigSendType" SG_ 696 KAE_EDK1TrunkBtnSt 1;
BA_ "GenSigStartValue" SG_ 696 KAE_EDK1TrunkBtnSt 0;
BA_ "GenSigTimeoutValue" SG_ 696 KAE_EDK1TrunkBtnSt 0;
BA_ "Remark" SG_ 696 KAE_EDK1TrunkBtnSt "";
BA_ "EventCommandSignal" SG_ 696 KAE_EDK1PanicBtnSt 0;
BA_ "GatewayedSignals" SG_ 696 KAE_EDK1PanicBtnSt 0;
BA_ "GenSigInactiveValue" SG_ 696 KAE_EDK1PanicBtnSt 0;
BA_ "GenSigInvalidValue" SG_ 696 KAE_EDK1PanicBtnSt 0;
BA_ "GenSigSendType" SG_ 696 KAE_EDK1PanicBtnSt 1;
BA_ "GenSigStartValue" SG_ 696 KAE_EDK1PanicBtnSt 0;
BA_ "GenSigTimeoutValue" SG_ 696 KAE_EDK1PanicBtnSt 0;
BA_ "Remark" SG_ 696 KAE_EDK1PanicBtnSt "";
BA_ "EventCommandSignal" SG_ 696 KAE_EDK1User_definedBtnSt 0;
BA_ "GatewayedSignals" SG_ 696 KAE_EDK1User_definedBtnSt 0;
BA_ "GenSigInactiveValue" SG_ 696 KAE_EDK1User_definedBtnSt 0;
BA_ "GenSigInvalidValue" SG_ 696 KAE_EDK1User_definedBtnSt 0;
BA_ "GenSigSendType" SG_ 696 KAE_EDK1User_definedBtnSt 1;
BA_ "GenSigStartValue" SG_ 696 KAE_EDK1User_definedBtnSt 0;
BA_ "GenSigTimeoutValue" SG_ 696 KAE_EDK1User_definedBtnSt 0;
BA_ "Remark" SG_ 696 KAE_EDK1User_definedBtnSt "";
BA_ "EventCommandSignal" SG_ 696 KAE_EDK2UnlockBtnSt 0;
BA_ "GatewayedSignals" SG_ 696 KAE_EDK2UnlockBtnSt 0;
BA_ "GenSigInactiveValue" SG_ 696 KAE_EDK2UnlockBtnSt 0;
BA_ "GenSigInvalidValue" SG_ 696 KAE_EDK2UnlockBtnSt 0;
BA_ "GenSigSendType" SG_ 696 KAE_EDK2UnlockBtnSt 1;
BA_ "GenSigStartValue" SG_ 696 KAE_EDK2UnlockBtnSt 0;
BA_ "GenSigTimeoutValue" SG_ 696 KAE_EDK2UnlockBtnSt 0;
BA_ "Remark" SG_ 696 KAE_EDK2UnlockBtnSt "";
BA_ "EventCommandSignal" SG_ 696 KAE_EDK2LockBtnSt 0;
BA_ "GatewayedSignals" SG_ 696 KAE_EDK2LockBtnSt 0;
BA_ "GenSigInactiveValue" SG_ 696 KAE_EDK2LockBtnSt 0;
BA_ "GenSigInvalidValue" SG_ 696 KAE_EDK2LockBtnSt 0;
BA_ "GenSigSendType" SG_ 696 KAE_EDK2LockBtnSt 1;
BA_ "GenSigStartValue" SG_ 696 KAE_EDK2LockBtnSt 0;
BA_ "GenSigTimeoutValue" SG_ 696 KAE_EDK2LockBtnSt 0;
BA_ "Remark" SG_ 696 KAE_EDK2LockBtnSt "";
BA_ "EventCommandSignal" SG_ 696 KAE_EDK2RESBtnSt 0;
BA_ "GatewayedSignals" SG_ 696 KAE_EDK2RESBtnSt 0;
BA_ "GenSigInactiveValue" SG_ 696 KAE_EDK2RESBtnSt 0;
BA_ "GenSigInvalidValue" SG_ 696 KAE_EDK2RESBtnSt 0;
BA_ "GenSigSendType" SG_ 696 KAE_EDK2RESBtnSt 1;
BA_ "GenSigStartValue" SG_ 696 KAE_EDK2RESBtnSt 0;
BA_ "GenSigTimeoutValue" SG_ 696 KAE_EDK2RESBtnSt 0;
BA_ "Remark" SG_ 696 KAE_EDK2RESBtnSt "";
BA_ "EventCommandSignal" SG_ 696 KAE_EDK2PSD_LBtnSt 0;
BA_ "GatewayedSignals" SG_ 696 KAE_EDK2PSD_LBtnSt 0;
BA_ "GenSigInactiveValue" SG_ 696 KAE_EDK2PSD_LBtnSt 0;
BA_ "GenSigInvalidValue" SG_ 696 KAE_EDK2PSD_LBtnSt 0;
BA_ "GenSigSendType" SG_ 696 KAE_EDK2PSD_LBtnSt 1;
BA_ "GenSigStartValue" SG_ 696 KAE_EDK2PSD_LBtnSt 0;
BA_ "GenSigTimeoutValue" SG_ 696 KAE_EDK2PSD_LBtnSt 0;
BA_ "Remark" SG_ 696 KAE_EDK2PSD_LBtnSt "";
BA_ "EventCommandSignal" SG_ 696 KAE_EDK2PSD_RBtnSt 0;
BA_ "GatewayedSignals" SG_ 696 KAE_EDK2PSD_RBtnSt 0;
BA_ "GenSigInactiveValue" SG_ 696 KAE_EDK2PSD_RBtnSt 0;
BA_ "GenSigInvalidValue" SG_ 696 KAE_EDK2PSD_RBtnSt 0;
BA_ "GenSigSendType" SG_ 696 KAE_EDK2PSD_RBtnSt 1;
BA_ "GenSigStartValue" SG_ 696 KAE_EDK2PSD_RBtnSt 0;
BA_ "GenSigTimeoutValue" SG_ 696 KAE_EDK2PSD_RBtnSt 0;
BA_ "Remark" SG_ 696 KAE_EDK2PSD_RBtnSt "";
BA_ "EventCommandSignal" SG_ 696 KAE_EDK2TrunkBtnSt 0;
BA_ "GatewayedSignals" SG_ 696 KAE_EDK2TrunkBtnSt 0;
BA_ "GenSigInactiveValue" SG_ 696 KAE_EDK2TrunkBtnSt 0;
BA_ "GenSigInvalidValue" SG_ 696 KAE_EDK2TrunkBtnSt 0;
BA_ "GenSigSendType" SG_ 696 KAE_EDK2TrunkBtnSt 1;
BA_ "GenSigStartValue" SG_ 696 KAE_EDK2TrunkBtnSt 0;
BA_ "GenSigTimeoutValue" SG_ 696 KAE_EDK2TrunkBtnSt 0;
BA_ "Remark" SG_ 696 KAE_EDK2TrunkBtnSt "";
BA_ "EventCommandSignal" SG_ 696 KAE_EDK2PanicBtnSt 0;
BA_ "GatewayedSignals" SG_ 696 KAE_EDK2PanicBtnSt 0;
BA_ "GenSigInactiveValue" SG_ 696 KAE_EDK2PanicBtnSt 0;
BA_ "GenSigInvalidValue" SG_ 696 KAE_EDK2PanicBtnSt 0;
BA_ "GenSigSendType" SG_ 696 KAE_EDK2PanicBtnSt 1;
BA_ "GenSigStartValue" SG_ 696 KAE_EDK2PanicBtnSt 0;
BA_ "GenSigTimeoutValue" SG_ 696 KAE_EDK2PanicBtnSt 0;
BA_ "Remark" SG_ 696 KAE_EDK2PanicBtnSt "";
BA_ "EventCommandSignal" SG_ 696 KAE_EDK2User_definedBtnSt 0;
BA_ "GatewayedSignals" SG_ 696 KAE_EDK2User_definedBtnSt 0;
BA_ "GenSigInactiveValue" SG_ 696 KAE_EDK2User_definedBtnSt 0;
BA_ "GenSigInvalidValue" SG_ 696 KAE_EDK2User_definedBtnSt 0;
BA_ "GenSigSendType" SG_ 696 KAE_EDK2User_definedBtnSt 1;
BA_ "GenSigStartValue" SG_ 696 KAE_EDK2User_definedBtnSt 0;
BA_ "GenSigTimeoutValue" SG_ 696 KAE_EDK2User_definedBtnSt 0;
BA_ "Remark" SG_ 696 KAE_EDK2User_definedBtnSt "";
BA_ "EventCommandSignal" SG_ 696 KAE_EDK3UnlockBtnSt 0;
BA_ "GatewayedSignals" SG_ 696 KAE_EDK3UnlockBtnSt 0;
BA_ "GenSigInactiveValue" SG_ 696 KAE_EDK3UnlockBtnSt 0;
BA_ "GenSigInvalidValue" SG_ 696 KAE_EDK3UnlockBtnSt 0;
BA_ "GenSigSendType" SG_ 696 KAE_EDK3UnlockBtnSt 1;
BA_ "GenSigStartValue" SG_ 696 KAE_EDK3UnlockBtnSt 0;
BA_ "GenSigTimeoutValue" SG_ 696 KAE_EDK3UnlockBtnSt 0;
BA_ "Remark" SG_ 696 KAE_EDK3UnlockBtnSt "";
BA_ "EventCommandSignal" SG_ 696 KAE_EDK3LockBtnSt 0;
BA_ "GatewayedSignals" SG_ 696 KAE_EDK3LockBtnSt 0;
BA_ "GenSigInactiveValue" SG_ 696 KAE_EDK3LockBtnSt 0;
BA_ "GenSigInvalidValue" SG_ 696 KAE_EDK3LockBtnSt 0;
BA_ "GenSigSendType" SG_ 696 KAE_EDK3LockBtnSt 1;
BA_ "GenSigStartValue" SG_ 696 KAE_EDK3LockBtnSt 0;
BA_ "GenSigTimeoutValue" SG_ 696 KAE_EDK3LockBtnSt 0;
BA_ "Remark" SG_ 696 KAE_EDK3LockBtnSt "";
BA_ "EventCommandSignal" SG_ 696 KAE_EDK3RESBtnSt 0;
BA_ "GatewayedSignals" SG_ 696 KAE_EDK3RESBtnSt 0;
BA_ "GenSigInactiveValue" SG_ 696 KAE_EDK3RESBtnSt 0;
BA_ "GenSigInvalidValue" SG_ 696 KAE_EDK3RESBtnSt 0;
BA_ "GenSigSendType" SG_ 696 KAE_EDK3RESBtnSt 1;
BA_ "GenSigStartValue" SG_ 696 KAE_EDK3RESBtnSt 0;
BA_ "GenSigTimeoutValue" SG_ 696 KAE_EDK3RESBtnSt 0;
BA_ "Remark" SG_ 696 KAE_EDK3RESBtnSt "";
BA_ "EventCommandSignal" SG_ 696 KAE_EDK3PSD_LBtnSt 0;
BA_ "GatewayedSignals" SG_ 696 KAE_EDK3PSD_LBtnSt 0;
BA_ "GenSigInactiveValue" SG_ 696 KAE_EDK3PSD_LBtnSt 0;
BA_ "GenSigInvalidValue" SG_ 696 KAE_EDK3PSD_LBtnSt 0;
BA_ "GenSigSendType" SG_ 696 KAE_EDK3PSD_LBtnSt 1;
BA_ "GenSigStartValue" SG_ 696 KAE_EDK3PSD_LBtnSt 0;
BA_ "GenSigTimeoutValue" SG_ 696 KAE_EDK3PSD_LBtnSt 0;
BA_ "Remark" SG_ 696 KAE_EDK3PSD_LBtnSt "";
BA_ "EventCommandSignal" SG_ 696 KAE_EDK3PSD_RBtnSt 0;
BA_ "GatewayedSignals" SG_ 696 KAE_EDK3PSD_RBtnSt 0;
BA_ "GenSigInactiveValue" SG_ 696 KAE_EDK3PSD_RBtnSt 0;
BA_ "GenSigInvalidValue" SG_ 696 KAE_EDK3PSD_RBtnSt 0;
BA_ "GenSigSendType" SG_ 696 KAE_EDK3PSD_RBtnSt 1;
BA_ "GenSigStartValue" SG_ 696 KAE_EDK3PSD_RBtnSt 0;
BA_ "GenSigTimeoutValue" SG_ 696 KAE_EDK3PSD_RBtnSt 0;
BA_ "Remark" SG_ 696 KAE_EDK3PSD_RBtnSt "";
BA_ "EventCommandSignal" SG_ 696 KAE_EDK3TrunkBtnSt 0;
BA_ "GatewayedSignals" SG_ 696 KAE_EDK3TrunkBtnSt 0;
BA_ "GenSigInactiveValue" SG_ 696 KAE_EDK3TrunkBtnSt 0;
BA_ "GenSigInvalidValue" SG_ 696 KAE_EDK3TrunkBtnSt 0;
BA_ "GenSigSendType" SG_ 696 KAE_EDK3TrunkBtnSt 1;
BA_ "GenSigStartValue" SG_ 696 KAE_EDK3TrunkBtnSt 0;
BA_ "GenSigTimeoutValue" SG_ 696 KAE_EDK3TrunkBtnSt 0;
BA_ "Remark" SG_ 696 KAE_EDK3TrunkBtnSt "";
BA_ "EventCommandSignal" SG_ 696 KAE_EDK3PanicBtnSt 0;
BA_ "GatewayedSignals" SG_ 696 KAE_EDK3PanicBtnSt 0;
BA_ "GenSigInactiveValue" SG_ 696 KAE_EDK3PanicBtnSt 0;
BA_ "GenSigInvalidValue" SG_ 696 KAE_EDK3PanicBtnSt 0;
BA_ "GenSigSendType" SG_ 696 KAE_EDK3PanicBtnSt 1;
BA_ "GenSigStartValue" SG_ 696 KAE_EDK3PanicBtnSt 0;
BA_ "GenSigTimeoutValue" SG_ 696 KAE_EDK3PanicBtnSt 0;
BA_ "Remark" SG_ 696 KAE_EDK3PanicBtnSt "";
BA_ "EventCommandSignal" SG_ 696 KAE_EDK3User_definedBtnSt 0;
BA_ "GatewayedSignals" SG_ 696 KAE_EDK3User_definedBtnSt 0;
BA_ "GenSigInactiveValue" SG_ 696 KAE_EDK3User_definedBtnSt 0;
BA_ "GenSigInvalidValue" SG_ 696 KAE_EDK3User_definedBtnSt 0;
BA_ "GenSigSendType" SG_ 696 KAE_EDK3User_definedBtnSt 1;
BA_ "GenSigStartValue" SG_ 696 KAE_EDK3User_definedBtnSt 0;
BA_ "GenSigTimeoutValue" SG_ 696 KAE_EDK3User_definedBtnSt 0;
BA_ "Remark" SG_ 696 KAE_EDK3User_definedBtnSt "";
BA_ "EventCommandSignal" SG_ 1934 ADC_Diag_Response 1;
BA_ "GatewayedSignals" SG_ 1934 ADC_Diag_Response 0;
BA_ "GenSigInactiveValue" SG_ 1934 ADC_Diag_Response 0;
BA_ "GenSigInvalidValue" SG_ 1934 ADC_Diag_Response 0;
BA_ "GenSigSendType" SG_ 1934 ADC_Diag_Response 0;
BA_ "GenSigStartValue" SG_ 1934 ADC_Diag_Response 0;
BA_ "GenSigTimeoutValue" SG_ 1934 ADC_Diag_Response 0;
BA_ "Remark" SG_ 1934 ADC_Diag_Response "";
BA_ "EventCommandSignal" SG_ 1294 ADC_NMNodeAddress 0;
BA_ "GatewayedSignals" SG_ 1294 ADC_NMNodeAddress 0;
BA_ "GenSigInactiveValue" SG_ 1294 ADC_NMNodeAddress 0;
BA_ "GenSigInvalidValue" SG_ 1294 ADC_NMNodeAddress 0;
BA_ "GenSigSendType" SG_ 1294 ADC_NMNodeAddress 1;
BA_ "GenSigStartValue" SG_ 1294 ADC_NMNodeAddress 14;
BA_ "GenSigTimeoutValue" SG_ 1294 ADC_NMNodeAddress 0;
BA_ "Remark" SG_ 1294 ADC_NMNodeAddress "";
BA_ "EventCommandSignal" SG_ 1294 ADC_NMCBV 0;
BA_ "GatewayedSignals" SG_ 1294 ADC_NMCBV 0;
BA_ "GenSigInactiveValue" SG_ 1294 ADC_NMCBV 0;
BA_ "GenSigInvalidValue" SG_ 1294 ADC_NMCBV 0;
BA_ "GenSigSendType" SG_ 1294 ADC_NMCBV 1;
BA_ "GenSigStartValue" SG_ 1294 ADC_NMCBV 0;
BA_ "GenSigTimeoutValue" SG_ 1294 ADC_NMCBV 0;
BA_ "Remark" SG_ 1294 ADC_NMCBV "";
BA_ "EventCommandSignal" SG_ 1294 ADC_NMWakeupOrigin 0;
BA_ "GatewayedSignals" SG_ 1294 ADC_NMWakeupOrigin 0;
BA_ "GenSigInactiveValue" SG_ 1294 ADC_NMWakeupOrigin 0;
BA_ "GenSigInvalidValue" SG_ 1294 ADC_NMWakeupOrigin 0;
BA_ "GenSigSendType" SG_ 1294 ADC_NMWakeupOrigin 1;
BA_ "GenSigStartValue" SG_ 1294 ADC_NMWakeupOrigin 0;
BA_ "GenSigTimeoutValue" SG_ 1294 ADC_NMWakeupOrigin 0;
BA_ "Remark" SG_ 1294 ADC_NMWakeupOrigin "";
BA_ "EventCommandSignal" SG_ 1294 ADC_PNCInformation0 0;
BA_ "GatewayedSignals" SG_ 1294 ADC_PNCInformation0 0;
BA_ "GenSigInactiveValue" SG_ 1294 ADC_PNCInformation0 0;
BA_ "GenSigInvalidValue" SG_ 1294 ADC_PNCInformation0 0;
BA_ "GenSigSendType" SG_ 1294 ADC_PNCInformation0 1;
BA_ "GenSigStartValue" SG_ 1294 ADC_PNCInformation0 0;
BA_ "GenSigTimeoutValue" SG_ 1294 ADC_PNCInformation0 0;
BA_ "Remark" SG_ 1294 ADC_PNCInformation0 "";
BA_ "EventCommandSignal" SG_ 1294 ADC_PNCInformation1 0;
BA_ "GatewayedSignals" SG_ 1294 ADC_PNCInformation1 0;
BA_ "GenSigInactiveValue" SG_ 1294 ADC_PNCInformation1 0;
BA_ "GenSigInvalidValue" SG_ 1294 ADC_PNCInformation1 0;
BA_ "GenSigSendType" SG_ 1294 ADC_PNCInformation1 1;
BA_ "GenSigStartValue" SG_ 1294 ADC_PNCInformation1 0;
BA_ "GenSigTimeoutValue" SG_ 1294 ADC_PNCInformation1 0;
BA_ "Remark" SG_ 1294 ADC_PNCInformation1 "";
BA_ "EventCommandSignal" SG_ 1294 ADC_PNCInformation2 0;
BA_ "GatewayedSignals" SG_ 1294 ADC_PNCInformation2 0;
BA_ "GenSigInactiveValue" SG_ 1294 ADC_PNCInformation2 0;
BA_ "GenSigInvalidValue" SG_ 1294 ADC_PNCInformation2 0;
BA_ "GenSigSendType" SG_ 1294 ADC_PNCInformation2 1;
BA_ "GenSigStartValue" SG_ 1294 ADC_PNCInformation2 0;
BA_ "GenSigTimeoutValue" SG_ 1294 ADC_PNCInformation2 0;
BA_ "Remark" SG_ 1294 ADC_PNCInformation2 "";
BA_ "EventCommandSignal" SG_ 1343 RRR_NMNodeAddress 0;
BA_ "GatewayedSignals" SG_ 1343 RRR_NMNodeAddress 0;
BA_ "GenSigInactiveValue" SG_ 1343 RRR_NMNodeAddress 0;
BA_ "GenSigInvalidValue" SG_ 1343 RRR_NMNodeAddress 0;
BA_ "GenSigSendType" SG_ 1343 RRR_NMNodeAddress 1;
BA_ "GenSigStartValue" SG_ 1343 RRR_NMNodeAddress 63;
BA_ "GenSigTimeoutValue" SG_ 1343 RRR_NMNodeAddress 0;
BA_ "Remark" SG_ 1343 RRR_NMNodeAddress "此信号恒定为：0x3F";
BA_ "EventCommandSignal" SG_ 1343 RRR_NMCBV 0;
BA_ "GatewayedSignals" SG_ 1343 RRR_NMCBV 0;
BA_ "GenSigInactiveValue" SG_ 1343 RRR_NMCBV 0;
BA_ "GenSigInvalidValue" SG_ 1343 RRR_NMCBV 0;
BA_ "GenSigSendType" SG_ 1343 RRR_NMCBV 1;
BA_ "GenSigStartValue" SG_ 1343 RRR_NMCBV 0;
BA_ "GenSigTimeoutValue" SG_ 1343 RRR_NMCBV 0;
BA_ "Remark" SG_ 1343 RRR_NMCBV "此信号恒定为：0x50";
BA_ "EventCommandSignal" SG_ 1343 RRR_NMWakeupOrigin 0;
BA_ "GatewayedSignals" SG_ 1343 RRR_NMWakeupOrigin 0;
BA_ "GenSigInactiveValue" SG_ 1343 RRR_NMWakeupOrigin 0;
BA_ "GenSigInvalidValue" SG_ 1343 RRR_NMWakeupOrigin 0;
BA_ "GenSigSendType" SG_ 1343 RRR_NMWakeupOrigin 1;
BA_ "GenSigStartValue" SG_ 1343 RRR_NMWakeupOrigin 0;
BA_ "GenSigTimeoutValue" SG_ 1343 RRR_NMWakeupOrigin 0;
BA_ "Remark" SG_ 1343 RRR_NMWakeupOrigin "此信号恒定为：0x00";
BA_ "EventCommandSignal" SG_ 1343 RRR_PNCInformation0 0;
BA_ "GatewayedSignals" SG_ 1343 RRR_PNCInformation0 0;
BA_ "GenSigInactiveValue" SG_ 1343 RRR_PNCInformation0 0;
BA_ "GenSigInvalidValue" SG_ 1343 RRR_PNCInformation0 0;
BA_ "GenSigSendType" SG_ 1343 RRR_PNCInformation0 1;
BA_ "GenSigStartValue" SG_ 1343 RRR_PNCInformation0 0;
BA_ "GenSigTimeoutValue" SG_ 1343 RRR_PNCInformation0 0;
BA_ "Remark" SG_ 1343 RRR_PNCInformation0 "此信号恒定为：0x01";
BA_ "EventCommandSignal" SG_ 1343 RRR_PNCInformation1 0;
BA_ "GatewayedSignals" SG_ 1343 RRR_PNCInformation1 0;
BA_ "GenSigInactiveValue" SG_ 1343 RRR_PNCInformation1 0;
BA_ "GenSigInvalidValue" SG_ 1343 RRR_PNCInformation1 0;
BA_ "GenSigSendType" SG_ 1343 RRR_PNCInformation1 1;
BA_ "GenSigStartValue" SG_ 1343 RRR_PNCInformation1 0;
BA_ "GenSigTimeoutValue" SG_ 1343 RRR_PNCInformation1 0;
BA_ "Remark" SG_ 1343 RRR_PNCInformation1 "此信号恒定为：0x00000000";
BA_ "EventCommandSignal" SG_ 1343 RRR_PNCInformation2 0;
BA_ "GatewayedSignals" SG_ 1343 RRR_PNCInformation2 0;
BA_ "GenSigInactiveValue" SG_ 1343 RRR_PNCInformation2 0;
BA_ "GenSigInvalidValue" SG_ 1343 RRR_PNCInformation2 0;
BA_ "GenSigSendType" SG_ 1343 RRR_PNCInformation2 1;
BA_ "GenSigStartValue" SG_ 1343 RRR_PNCInformation2 0;
BA_ "GenSigTimeoutValue" SG_ 1343 RRR_PNCInformation2 0;
BA_ "Remark" SG_ 1343 RRR_PNCInformation2 "此信号恒定为：0x00000000";
BA_ "EventCommandSignal" SG_ 1354 RLR_NMNodeAddress 0;
BA_ "GatewayedSignals" SG_ 1354 RLR_NMNodeAddress 0;
BA_ "GenSigInactiveValue" SG_ 1354 RLR_NMNodeAddress 0;
BA_ "GenSigInvalidValue" SG_ 1354 RLR_NMNodeAddress 0;
BA_ "GenSigSendType" SG_ 1354 RLR_NMNodeAddress 1;
BA_ "GenSigStartValue" SG_ 1354 RLR_NMNodeAddress 74;
BA_ "GenSigTimeoutValue" SG_ 1354 RLR_NMNodeAddress 0;
BA_ "Remark" SG_ 1354 RLR_NMNodeAddress "此信号恒定为：0x4A";
BA_ "EventCommandSignal" SG_ 1354 RLR_NMCBV 0;
BA_ "GatewayedSignals" SG_ 1354 RLR_NMCBV 0;
BA_ "GenSigInactiveValue" SG_ 1354 RLR_NMCBV 0;
BA_ "GenSigInvalidValue" SG_ 1354 RLR_NMCBV 0;
BA_ "GenSigSendType" SG_ 1354 RLR_NMCBV 1;
BA_ "GenSigStartValue" SG_ 1354 RLR_NMCBV 0;
BA_ "GenSigTimeoutValue" SG_ 1354 RLR_NMCBV 0;
BA_ "Remark" SG_ 1354 RLR_NMCBV "此信号恒定为：0x50";
BA_ "EventCommandSignal" SG_ 1354 RLR_NMWakeupOrigin 0;
BA_ "GatewayedSignals" SG_ 1354 RLR_NMWakeupOrigin 0;
BA_ "GenSigInactiveValue" SG_ 1354 RLR_NMWakeupOrigin 0;
BA_ "GenSigInvalidValue" SG_ 1354 RLR_NMWakeupOrigin 0;
BA_ "GenSigSendType" SG_ 1354 RLR_NMWakeupOrigin 1;
BA_ "GenSigStartValue" SG_ 1354 RLR_NMWakeupOrigin 0;
BA_ "GenSigTimeoutValue" SG_ 1354 RLR_NMWakeupOrigin 0;
BA_ "Remark" SG_ 1354 RLR_NMWakeupOrigin "此信号恒定为：0x00";
BA_ "EventCommandSignal" SG_ 1354 RLR_PNCInformation0 0;
BA_ "GatewayedSignals" SG_ 1354 RLR_PNCInformation0 0;
BA_ "GenSigInactiveValue" SG_ 1354 RLR_PNCInformation0 0;
BA_ "GenSigInvalidValue" SG_ 1354 RLR_PNCInformation0 0;
BA_ "GenSigSendType" SG_ 1354 RLR_PNCInformation0 1;
BA_ "GenSigStartValue" SG_ 1354 RLR_PNCInformation0 0;
BA_ "GenSigTimeoutValue" SG_ 1354 RLR_PNCInformation0 0;
BA_ "Remark" SG_ 1354 RLR_PNCInformation0 "此信号恒定为：0x01";
BA_ "EventCommandSignal" SG_ 1354 RLR_PNCInformation1 0;
BA_ "GatewayedSignals" SG_ 1354 RLR_PNCInformation1 0;
BA_ "GenSigInactiveValue" SG_ 1354 RLR_PNCInformation1 0;
BA_ "GenSigInvalidValue" SG_ 1354 RLR_PNCInformation1 0;
BA_ "GenSigSendType" SG_ 1354 RLR_PNCInformation1 1;
BA_ "GenSigStartValue" SG_ 1354 RLR_PNCInformation1 0;
BA_ "GenSigTimeoutValue" SG_ 1354 RLR_PNCInformation1 0;
BA_ "Remark" SG_ 1354 RLR_PNCInformation1 "此信号恒定为：0x00000000";
BA_ "EventCommandSignal" SG_ 1354 RLR_PNCInformation2 0;
BA_ "GatewayedSignals" SG_ 1354 RLR_PNCInformation2 0;
BA_ "GenSigInactiveValue" SG_ 1354 RLR_PNCInformation2 0;
BA_ "GenSigInvalidValue" SG_ 1354 RLR_PNCInformation2 0;
BA_ "GenSigSendType" SG_ 1354 RLR_PNCInformation2 1;
BA_ "GenSigStartValue" SG_ 1354 RLR_PNCInformation2 0;
BA_ "GenSigTimeoutValue" SG_ 1354 RLR_PNCInformation2 0;
BA_ "Remark" SG_ 1354 RLR_PNCInformation2 "此信号恒定为：0x00000000";
BA_ "EventCommandSignal" SG_ 932 RRR_1_CRC 0;
BA_ "GatewayedSignals" SG_ 932 RRR_1_CRC 0;
BA_ "GenSigInactiveValue" SG_ 932 RRR_1_CRC 0;
BA_ "GenSigInvalidValue" SG_ 932 RRR_1_CRC 0;
BA_ "GenSigSendType" SG_ 932 RRR_1_CRC 1;
BA_ "GenSigStartValue" SG_ 932 RRR_1_CRC 0;
BA_ "GenSigTimeoutValue" SG_ 932 RRR_1_CRC 0;
BA_ "Remark" SG_ 932 RRR_1_CRC "";
BA_ "EventCommandSignal" SG_ 932 RRR_1_Counter 0;
BA_ "GatewayedSignals" SG_ 932 RRR_1_Counter 0;
BA_ "GenSigInactiveValue" SG_ 932 RRR_1_Counter 0;
BA_ "GenSigInvalidValue" SG_ 932 RRR_1_Counter 0;
BA_ "GenSigSendType" SG_ 932 RRR_1_Counter 1;
BA_ "GenSigStartValue" SG_ 932 RRR_1_Counter 0;
BA_ "GenSigTimeoutValue" SG_ 932 RRR_1_Counter 0;
BA_ "Remark" SG_ 932 RRR_1_Counter "";
BA_ "EventCommandSignal" SG_ 932 RRR_MRRSt 0;
BA_ "GatewayedSignals" SG_ 932 RRR_MRRSt 0;
BA_ "GenSigInactiveValue" SG_ 932 RRR_MRRSt 0;
BA_ "GenSigInvalidValue" SG_ 932 RRR_MRRSt 0;
BA_ "GenSigSendType" SG_ 932 RRR_MRRSt 1;
BA_ "GenSigStartValue" SG_ 932 RRR_MRRSt 0;
BA_ "GenSigTimeoutValue" SG_ 932 RRR_MRRSt 2;
BA_ "Remark" SG_ 932 RRR_MRRSt "";
BA_ "EventCommandSignal" SG_ 932 RRR_ExMirLedWarnR 0;
BA_ "GatewayedSignals" SG_ 932 RRR_ExMirLedWarnR 0;
BA_ "GenSigInactiveValue" SG_ 932 RRR_ExMirLedWarnR 0;
BA_ "GenSigInvalidValue" SG_ 932 RRR_ExMirLedWarnR 0;
BA_ "GenSigSendType" SG_ 932 RRR_ExMirLedWarnR 1;
BA_ "GenSigStartValue" SG_ 932 RRR_ExMirLedWarnR 0;
BA_ "GenSigTimeoutValue" SG_ 932 RRR_ExMirLedWarnR 0;
BA_ "Remark" SG_ 932 RRR_ExMirLedWarnR "";
BA_ "EventCommandSignal" SG_ 932 RRR_LCASt 0;
BA_ "GatewayedSignals" SG_ 932 RRR_LCASt 0;
BA_ "GenSigInactiveValue" SG_ 932 RRR_LCASt 0;
BA_ "GenSigInvalidValue" SG_ 932 RRR_LCASt 0;
BA_ "GenSigSendType" SG_ 932 RRR_LCASt 1;
BA_ "GenSigStartValue" SG_ 932 RRR_LCASt 0;
BA_ "GenSigTimeoutValue" SG_ 932 RRR_LCASt 3;
BA_ "Remark" SG_ 932 RRR_LCASt "";
BA_ "EventCommandSignal" SG_ 932 RRR_LCAWarnRight 0;
BA_ "GatewayedSignals" SG_ 932 RRR_LCAWarnRight 0;
BA_ "GenSigInactiveValue" SG_ 932 RRR_LCAWarnRight 0;
BA_ "GenSigInvalidValue" SG_ 932 RRR_LCAWarnRight 0;
BA_ "GenSigSendType" SG_ 932 RRR_LCAWarnRight 1;
BA_ "GenSigStartValue" SG_ 932 RRR_LCAWarnRight 0;
BA_ "GenSigTimeoutValue" SG_ 932 RRR_LCAWarnRight 0;
BA_ "Remark" SG_ 932 RRR_LCAWarnRight "";
BA_ "EventCommandSignal" SG_ 932 RRR_ClusterLamp 0;
BA_ "GatewayedSignals" SG_ 932 RRR_ClusterLamp 0;
BA_ "GenSigInactiveValue" SG_ 932 RRR_ClusterLamp 0;
BA_ "GenSigInvalidValue" SG_ 932 RRR_ClusterLamp 0;
BA_ "GenSigSendType" SG_ 932 RRR_ClusterLamp 1;
BA_ "GenSigStartValue" SG_ 932 RRR_ClusterLamp 0;
BA_ "GenSigTimeoutValue" SG_ 932 RRR_ClusterLamp 1;
BA_ "Remark" SG_ 932 RRR_ClusterLamp "";
BA_ "EventCommandSignal" SG_ 932 RRR_DOWWarnR 0;
BA_ "GatewayedSignals" SG_ 932 RRR_DOWWarnR 0;
BA_ "GenSigInactiveValue" SG_ 932 RRR_DOWWarnR 0;
BA_ "GenSigInvalidValue" SG_ 932 RRR_DOWWarnR 0;
BA_ "GenSigSendType" SG_ 932 RRR_DOWWarnR 1;
BA_ "GenSigStartValue" SG_ 932 RRR_DOWWarnR 0;
BA_ "GenSigTimeoutValue" SG_ 932 RRR_DOWWarnR 0;
BA_ "Remark" SG_ 932 RRR_DOWWarnR "";
BA_ "EventCommandSignal" SG_ 932 RRR_DOWSt 0;
BA_ "GatewayedSignals" SG_ 932 RRR_DOWSt 0;
BA_ "GenSigInactiveValue" SG_ 932 RRR_DOWSt 0;
BA_ "GenSigInvalidValue" SG_ 932 RRR_DOWSt 0;
BA_ "GenSigSendType" SG_ 932 RRR_DOWSt 1;
BA_ "GenSigStartValue" SG_ 932 RRR_DOWSt 0;
BA_ "GenSigTimeoutValue" SG_ 932 RRR_DOWSt 0;
BA_ "Remark" SG_ 932 RRR_DOWSt "";
BA_ "EventCommandSignal" SG_ 932 RRR_AudioWarnFR 0;
BA_ "GatewayedSignals" SG_ 932 RRR_AudioWarnFR 0;
BA_ "GenSigInactiveValue" SG_ 932 RRR_AudioWarnFR 0;
BA_ "GenSigInvalidValue" SG_ 932 RRR_AudioWarnFR 0;
BA_ "GenSigSendType" SG_ 932 RRR_AudioWarnFR 1;
BA_ "GenSigStartValue" SG_ 932 RRR_AudioWarnFR 0;
BA_ "GenSigTimeoutValue" SG_ 932 RRR_AudioWarnFR 0;
BA_ "Remark" SG_ 932 RRR_AudioWarnFR "";
BA_ "EventCommandSignal" SG_ 932 RRR_AudioWarnRR 0;
BA_ "GatewayedSignals" SG_ 932 RRR_AudioWarnRR 0;
BA_ "GenSigInactiveValue" SG_ 932 RRR_AudioWarnRR 0;
BA_ "GenSigInvalidValue" SG_ 932 RRR_AudioWarnRR 0;
BA_ "GenSigSendType" SG_ 932 RRR_AudioWarnRR 1;
BA_ "GenSigStartValue" SG_ 932 RRR_AudioWarnRR 0;
BA_ "GenSigTimeoutValue" SG_ 932 RRR_AudioWarnRR 0;
BA_ "Remark" SG_ 932 RRR_AudioWarnRR "";
BA_ "EventCommandSignal" SG_ 932 RRR_IALWarnFR 0;
BA_ "GatewayedSignals" SG_ 932 RRR_IALWarnFR 0;
BA_ "GenSigInactiveValue" SG_ 932 RRR_IALWarnFR 0;
BA_ "GenSigInvalidValue" SG_ 932 RRR_IALWarnFR 0;
BA_ "GenSigSendType" SG_ 932 RRR_IALWarnFR 1;
BA_ "GenSigStartValue" SG_ 932 RRR_IALWarnFR 0;
BA_ "GenSigTimeoutValue" SG_ 932 RRR_IALWarnFR 0;
BA_ "Remark" SG_ 932 RRR_IALWarnFR "";
BA_ "EventCommandSignal" SG_ 932 RRR_IALWarnRR 0;
BA_ "GatewayedSignals" SG_ 932 RRR_IALWarnRR 0;
BA_ "GenSigInactiveValue" SG_ 932 RRR_IALWarnRR 0;
BA_ "GenSigInvalidValue" SG_ 932 RRR_IALWarnRR 0;
BA_ "GenSigSendType" SG_ 932 RRR_IALWarnRR 1;
BA_ "GenSigStartValue" SG_ 932 RRR_IALWarnRR 0;
BA_ "GenSigTimeoutValue" SG_ 932 RRR_IALWarnRR 0;
BA_ "Remark" SG_ 932 RRR_IALWarnRR "";
BA_ "EventCommandSignal" SG_ 932 RRR_RCTASt 0;
BA_ "GatewayedSignals" SG_ 932 RRR_RCTASt 0;
BA_ "GenSigInactiveValue" SG_ 932 RRR_RCTASt 0;
BA_ "GenSigInvalidValue" SG_ 932 RRR_RCTASt 0;
BA_ "GenSigSendType" SG_ 932 RRR_RCTASt 1;
BA_ "GenSigStartValue" SG_ 932 RRR_RCTASt 0;
BA_ "EventCommandSignal" SG_ 932 RRR_RCTAWarnRight 0;
BA_ "GatewayedSignals" SG_ 932 RRR_RCTAWarnRight 0;
BA_ "GenSigInactiveValue" SG_ 932 RRR_RCTAWarnRight 0;
BA_ "GenSigInvalidValue" SG_ 932 RRR_RCTAWarnRight 0;
BA_ "GenSigSendType" SG_ 932 RRR_RCTAWarnRight 1;
BA_ "GenSigStartValue" SG_ 932 RRR_RCTAWarnRight 0;
BA_ "GenSigTimeoutValue" SG_ 932 RRR_RCTAWarnRight 0;
BA_ "Remark" SG_ 932 RRR_RCTAWarnRight "";
BA_ "EventCommandSignal" SG_ 932 RRR_RCWSt 0;
BA_ "GatewayedSignals" SG_ 932 RRR_RCWSt 0;
BA_ "GenSigInactiveValue" SG_ 932 RRR_RCWSt 0;
BA_ "GenSigInvalidValue" SG_ 932 RRR_RCWSt 0;
BA_ "GenSigSendType" SG_ 932 RRR_RCWSt 1;
BA_ "GenSigStartValue" SG_ 932 RRR_RCWSt 0;
BA_ "GenSigTimeoutValue" SG_ 932 RRR_RCWSt 3;
BA_ "Remark" SG_ 932 RRR_RCWSt "";
BA_ "EventCommandSignal" SG_ 932 RRR_RCWWarn 0;
BA_ "GatewayedSignals" SG_ 932 RRR_RCWWarn 0;
BA_ "GenSigInactiveValue" SG_ 932 RRR_RCWWarn 0;
BA_ "GenSigInvalidValue" SG_ 932 RRR_RCWWarn 0;
BA_ "GenSigSendType" SG_ 932 RRR_RCWWarn 1;
BA_ "GenSigStartValue" SG_ 932 RRR_RCWWarn 0;
BA_ "GenSigTimeoutValue" SG_ 932 RRR_RCWWarn 0;
BA_ "Remark" SG_ 932 RRR_RCWWarn "";
BA_ "EventCommandSignal" SG_ 932 RRR_RCTBTargetDecel 0;
BA_ "GatewayedSignals" SG_ 932 RRR_RCTBTargetDecel 0;
BA_ "GenSigInactiveValue" SG_ 932 RRR_RCTBTargetDecel 0;
BA_ "GenSigInvalidValue" SG_ 932 RRR_RCTBTargetDecel 0;
BA_ "GenSigSendType" SG_ 932 RRR_RCTBTargetDecel 1;
BA_ "GenSigStartValue" SG_ 932 RRR_RCTBTargetDecel 0;
BA_ "GenSigTimeoutValue" SG_ 932 RRR_RCTBTargetDecel 0;
BA_ "Remark" SG_ 932 RRR_RCTBTargetDecel "";
BA_ "EventCommandSignal" SG_ 932 RRR_RCTBBrkReq 0;
BA_ "GatewayedSignals" SG_ 932 RRR_RCTBBrkReq 0;
BA_ "GenSigInactiveValue" SG_ 932 RRR_RCTBBrkReq 0;
BA_ "GenSigInvalidValue" SG_ 932 RRR_RCTBBrkReq 0;
BA_ "GenSigSendType" SG_ 932 RRR_RCTBBrkReq 1;
BA_ "GenSigStartValue" SG_ 932 RRR_RCTBBrkReq 0;
BA_ "GenSigTimeoutValue" SG_ 932 RRR_RCTBBrkReq 0;
BA_ "Remark" SG_ 932 RRR_RCTBBrkReq "";
BA_ "EventCommandSignal" SG_ 932 RRR_TargetLatDistR 0;
BA_ "GatewayedSignals" SG_ 932 RRR_TargetLatDistR 0;
BA_ "GenSigInactiveValue" SG_ 932 RRR_TargetLatDistR 0;
BA_ "GenSigInvalidValue" SG_ 932 RRR_TargetLatDistR 0;
BA_ "GenSigSendType" SG_ 932 RRR_TargetLatDistR 1;
BA_ "GenSigStartValue" SG_ 932 RRR_TargetLatDistR 0;
BA_ "GenSigTimeoutValue" SG_ 932 RRR_TargetLatDistR 0;
BA_ "Remark" SG_ 932 RRR_TargetLatDistR "";
BA_ "EventCommandSignal" SG_ 932 RRR_TargetRelSpdR 0;
BA_ "GatewayedSignals" SG_ 932 RRR_TargetRelSpdR 0;
BA_ "GenSigInactiveValue" SG_ 932 RRR_TargetRelSpdR 0;
BA_ "GenSigInvalidValue" SG_ 932 RRR_TargetRelSpdR 0;
BA_ "GenSigSendType" SG_ 932 RRR_TargetRelSpdR 1;
BA_ "GenSigStartValue" SG_ 932 RRR_TargetRelSpdR 0;
BA_ "GenSigTimeoutValue" SG_ 932 RRR_TargetRelSpdR 0;
BA_ "Remark" SG_ 932 RRR_TargetRelSpdR "";
BA_ "EventCommandSignal" SG_ 932 RRR_RCTBBrkgVD 0;
BA_ "GatewayedSignals" SG_ 932 RRR_RCTBBrkgVD 0;
BA_ "GenSigInactiveValue" SG_ 932 RRR_RCTBBrkgVD 0;
BA_ "GenSigInvalidValue" SG_ 932 RRR_RCTBBrkgVD 0;
BA_ "GenSigSendType" SG_ 932 RRR_RCTBBrkgVD 1;
BA_ "GenSigStartValue" SG_ 932 RRR_RCTBBrkgVD 0;
BA_ "GenSigTimeoutValue" SG_ 932 RRR_RCTBBrkgVD 1;
BA_ "Remark" SG_ 932 RRR_RCTBBrkgVD "";
BA_ "EventCommandSignal" SG_ 932 RRR_TargetRVD 0;
BA_ "GatewayedSignals" SG_ 932 RRR_TargetRVD 0;
BA_ "GenSigInactiveValue" SG_ 932 RRR_TargetRVD 0;
BA_ "GenSigInvalidValue" SG_ 932 RRR_TargetRVD 0;
BA_ "GenSigSendType" SG_ 932 RRR_TargetRVD 1;
BA_ "GenSigStartValue" SG_ 932 RRR_TargetRVD 0;
BA_ "GenSigTimeoutValue" SG_ 932 RRR_TargetRVD 0;
BA_ "Remark" SG_ 932 RRR_TargetRVD "";
BA_ "EventCommandSignal" SG_ 932 RRR_TargetDstR 0;
BA_ "GatewayedSignals" SG_ 932 RRR_TargetDstR 0;
BA_ "GenSigInactiveValue" SG_ 932 RRR_TargetDstR 0;
BA_ "GenSigInvalidValue" SG_ 932 RRR_TargetDstR 0;
BA_ "GenSigSendType" SG_ 932 RRR_TargetDstR 1;
BA_ "GenSigStartValue" SG_ 932 RRR_TargetDstR 0;
BA_ "GenSigTimeoutValue" SG_ 932 RRR_TargetDstR 0;
BA_ "Remark" SG_ 932 RRR_TargetDstR "";
BA_ "EventCommandSignal" SG_ 932 RRR_RCTAAssistType 0;
BA_ "GatewayedSignals" SG_ 932 RRR_RCTAAssistType 0;
BA_ "GenSigInactiveValue" SG_ 932 RRR_RCTAAssistType 0;
BA_ "GenSigInvalidValue" SG_ 932 RRR_RCTAAssistType 0;
BA_ "GenSigSendType" SG_ 932 RRR_RCTAAssistType 1;
BA_ "GenSigStartValue" SG_ 932 RRR_RCTAAssistType 0;
BA_ "GenSigTimeoutValue" SG_ 932 RRR_RCTAAssistType 0;
BA_ "Remark" SG_ 932 RRR_RCTAAssistType "";
BA_ "EventCommandSignal" SG_ 987 RLR_1_CRC 0;
BA_ "GatewayedSignals" SG_ 987 RLR_1_CRC 0;
BA_ "GenSigInactiveValue" SG_ 987 RLR_1_CRC 0;
BA_ "GenSigInvalidValue" SG_ 987 RLR_1_CRC 0;
BA_ "GenSigSendType" SG_ 987 RLR_1_CRC 1;
BA_ "GenSigStartValue" SG_ 987 RLR_1_CRC 0;
BA_ "GenSigTimeoutValue" SG_ 987 RLR_1_CRC 0;
BA_ "Remark" SG_ 987 RLR_1_CRC "";
BA_ "EventCommandSignal" SG_ 987 RLR_1_Counter 0;
BA_ "GatewayedSignals" SG_ 987 RLR_1_Counter 0;
BA_ "GenSigInactiveValue" SG_ 987 RLR_1_Counter 0;
BA_ "GenSigInvalidValue" SG_ 987 RLR_1_Counter 0;
BA_ "GenSigSendType" SG_ 987 RLR_1_Counter 1;
BA_ "GenSigStartValue" SG_ 987 RLR_1_Counter 0;
BA_ "GenSigTimeoutValue" SG_ 987 RLR_1_Counter 0;
BA_ "Remark" SG_ 987 RLR_1_Counter "";
BA_ "EventCommandSignal" SG_ 987 RLR_MRRSt 0;
BA_ "GatewayedSignals" SG_ 987 RLR_MRRSt 0;
BA_ "GenSigInactiveValue" SG_ 987 RLR_MRRSt 0;
BA_ "GenSigInvalidValue" SG_ 987 RLR_MRRSt 0;
BA_ "GenSigSendType" SG_ 987 RLR_MRRSt 1;
BA_ "GenSigStartValue" SG_ 987 RLR_MRRSt 0;
BA_ "GenSigTimeoutValue" SG_ 987 RLR_MRRSt 2;
BA_ "Remark" SG_ 987 RLR_MRRSt "";
BA_ "EventCommandSignal" SG_ 987 RLR_ExMirLedWarnL 0;
BA_ "GatewayedSignals" SG_ 987 RLR_ExMirLedWarnL 0;
BA_ "GenSigInactiveValue" SG_ 987 RLR_ExMirLedWarnL 0;
BA_ "GenSigInvalidValue" SG_ 987 RLR_ExMirLedWarnL 0;
BA_ "GenSigSendType" SG_ 987 RLR_ExMirLedWarnL 1;
BA_ "GenSigStartValue" SG_ 987 RLR_ExMirLedWarnL 0;
BA_ "GenSigTimeoutValue" SG_ 987 RLR_ExMirLedWarnL 0;
BA_ "Remark" SG_ 987 RLR_ExMirLedWarnL "";
BA_ "EventCommandSignal" SG_ 987 RLR_LCASt 0;
BA_ "GatewayedSignals" SG_ 987 RLR_LCASt 0;
BA_ "GenSigInactiveValue" SG_ 987 RLR_LCASt 0;
BA_ "GenSigInvalidValue" SG_ 987 RLR_LCASt 0;
BA_ "GenSigSendType" SG_ 987 RLR_LCASt 1;
BA_ "GenSigStartValue" SG_ 987 RLR_LCASt 0;
BA_ "GenSigTimeoutValue" SG_ 987 RLR_LCASt 3;
BA_ "Remark" SG_ 987 RLR_LCASt "";
BA_ "EventCommandSignal" SG_ 987 RLR_LCAWarnLeft 0;
BA_ "GatewayedSignals" SG_ 987 RLR_LCAWarnLeft 0;
BA_ "GenSigInactiveValue" SG_ 987 RLR_LCAWarnLeft 0;
BA_ "GenSigInvalidValue" SG_ 987 RLR_LCAWarnLeft 0;
BA_ "GenSigSendType" SG_ 987 RLR_LCAWarnLeft 1;
BA_ "GenSigStartValue" SG_ 987 RLR_LCAWarnLeft 0;
BA_ "GenSigTimeoutValue" SG_ 987 RLR_LCAWarnLeft 0;
BA_ "Remark" SG_ 987 RLR_LCAWarnLeft "";
BA_ "EventCommandSignal" SG_ 987 RLR_ClusterLamp 0;
BA_ "GatewayedSignals" SG_ 987 RLR_ClusterLamp 0;
BA_ "GenSigInactiveValue" SG_ 987 RLR_ClusterLamp 0;
BA_ "GenSigInvalidValue" SG_ 987 RLR_ClusterLamp 0;
BA_ "GenSigSendType" SG_ 987 RLR_ClusterLamp 1;
BA_ "GenSigStartValue" SG_ 987 RLR_ClusterLamp 0;
BA_ "GenSigTimeoutValue" SG_ 987 RLR_ClusterLamp 1;
BA_ "Remark" SG_ 987 RLR_ClusterLamp "";
BA_ "EventCommandSignal" SG_ 987 RLR_DOWWarnL 0;
BA_ "GatewayedSignals" SG_ 987 RLR_DOWWarnL 0;
BA_ "GenSigInactiveValue" SG_ 987 RLR_DOWWarnL 0;
BA_ "GenSigInvalidValue" SG_ 987 RLR_DOWWarnL 0;
BA_ "GenSigSendType" SG_ 987 RLR_DOWWarnL 1;
BA_ "GenSigStartValue" SG_ 987 RLR_DOWWarnL 0;
BA_ "GenSigTimeoutValue" SG_ 987 RLR_DOWWarnL 0;
BA_ "Remark" SG_ 987 RLR_DOWWarnL "";
BA_ "EventCommandSignal" SG_ 987 RLR_DOWSt 0;
BA_ "GatewayedSignals" SG_ 987 RLR_DOWSt 0;
BA_ "GenSigInactiveValue" SG_ 987 RLR_DOWSt 0;
BA_ "GenSigInvalidValue" SG_ 987 RLR_DOWSt 0;
BA_ "GenSigSendType" SG_ 987 RLR_DOWSt 1;
BA_ "GenSigStartValue" SG_ 987 RLR_DOWSt 0;
BA_ "GenSigTimeoutValue" SG_ 987 RLR_DOWSt 0;
BA_ "Remark" SG_ 987 RLR_DOWSt "";
BA_ "EventCommandSignal" SG_ 987 RLR_AudioWarnFL 0;
BA_ "GatewayedSignals" SG_ 987 RLR_AudioWarnFL 0;
BA_ "GenSigInactiveValue" SG_ 987 RLR_AudioWarnFL 0;
BA_ "GenSigInvalidValue" SG_ 987 RLR_AudioWarnFL 0;
BA_ "GenSigSendType" SG_ 987 RLR_AudioWarnFL 1;
BA_ "GenSigStartValue" SG_ 987 RLR_AudioWarnFL 0;
BA_ "GenSigTimeoutValue" SG_ 987 RLR_AudioWarnFL 0;
BA_ "Remark" SG_ 987 RLR_AudioWarnFL "";
BA_ "EventCommandSignal" SG_ 987 RLR_AudioWarnRL 0;
BA_ "GatewayedSignals" SG_ 987 RLR_AudioWarnRL 0;
BA_ "GenSigInactiveValue" SG_ 987 RLR_AudioWarnRL 0;
BA_ "GenSigInvalidValue" SG_ 987 RLR_AudioWarnRL 0;
BA_ "GenSigSendType" SG_ 987 RLR_AudioWarnRL 1;
BA_ "GenSigStartValue" SG_ 987 RLR_AudioWarnRL 0;
BA_ "GenSigTimeoutValue" SG_ 987 RLR_AudioWarnRL 0;
BA_ "Remark" SG_ 987 RLR_AudioWarnRL "";
BA_ "EventCommandSignal" SG_ 987 RLR_IALWarnFL 0;
BA_ "GatewayedSignals" SG_ 987 RLR_IALWarnFL 0;
BA_ "GenSigInactiveValue" SG_ 987 RLR_IALWarnFL 0;
BA_ "GenSigInvalidValue" SG_ 987 RLR_IALWarnFL 0;
BA_ "GenSigSendType" SG_ 987 RLR_IALWarnFL 1;
BA_ "GenSigStartValue" SG_ 987 RLR_IALWarnFL 0;
BA_ "GenSigTimeoutValue" SG_ 987 RLR_IALWarnFL 0;
BA_ "Remark" SG_ 987 RLR_IALWarnFL "";
BA_ "EventCommandSignal" SG_ 987 RLR_IALWarnRL 0;
BA_ "GatewayedSignals" SG_ 987 RLR_IALWarnRL 0;
BA_ "GenSigInactiveValue" SG_ 987 RLR_IALWarnRL 0;
BA_ "GenSigInvalidValue" SG_ 987 RLR_IALWarnRL 0;
BA_ "GenSigSendType" SG_ 987 RLR_IALWarnRL 1;
BA_ "GenSigStartValue" SG_ 987 RLR_IALWarnRL 0;
BA_ "GenSigTimeoutValue" SG_ 987 RLR_IALWarnRL 0;
BA_ "Remark" SG_ 987 RLR_IALWarnRL "";
BA_ "EventCommandSignal" SG_ 987 RLR_RCTAWarnLeft 0;
BA_ "GatewayedSignals" SG_ 987 RLR_RCTAWarnLeft 0;
BA_ "GenSigInactiveValue" SG_ 987 RLR_RCTAWarnLeft 0;
BA_ "GenSigInvalidValue" SG_ 987 RLR_RCTAWarnLeft 0;
BA_ "GenSigSendType" SG_ 987 RLR_RCTAWarnLeft 1;
BA_ "GenSigStartValue" SG_ 987 RLR_RCTAWarnLeft 0;
BA_ "GenSigTimeoutValue" SG_ 987 RLR_RCTAWarnLeft 0;
BA_ "Remark" SG_ 987 RLR_RCTAWarnLeft "";
BA_ "EventCommandSignal" SG_ 987 RLR_RCWSt 0;
BA_ "GatewayedSignals" SG_ 987 RLR_RCWSt 0;
BA_ "GenSigInactiveValue" SG_ 987 RLR_RCWSt 0;
BA_ "GenSigInvalidValue" SG_ 987 RLR_RCWSt 0;
BA_ "GenSigSendType" SG_ 987 RLR_RCWSt 1;
BA_ "GenSigStartValue" SG_ 987 RLR_RCWSt 0;
BA_ "GenSigTimeoutValue" SG_ 987 RLR_RCWSt 0;
BA_ "Remark" SG_ 987 RLR_RCWSt "";
BA_ "EventCommandSignal" SG_ 987 RLR_RCWWarn 0;
BA_ "GatewayedSignals" SG_ 987 RLR_RCWWarn 0;
BA_ "GenSigInactiveValue" SG_ 987 RLR_RCWWarn 0;
BA_ "GenSigInvalidValue" SG_ 987 RLR_RCWWarn 0;
BA_ "GenSigSendType" SG_ 987 RLR_RCWWarn 1;
BA_ "GenSigStartValue" SG_ 987 RLR_RCWWarn 0;
BA_ "GenSigTimeoutValue" SG_ 987 RLR_RCWWarn 0;
BA_ "Remark" SG_ 987 RLR_RCWWarn "";
BA_ "EventCommandSignal" SG_ 987 RLR_TargetLVD 0;
BA_ "GatewayedSignals" SG_ 987 RLR_TargetLVD 0;
BA_ "GenSigInactiveValue" SG_ 987 RLR_TargetLVD 0;
BA_ "GenSigInvalidValue" SG_ 987 RLR_TargetLVD 0;
BA_ "GenSigSendType" SG_ 987 RLR_TargetLVD 1;
BA_ "GenSigStartValue" SG_ 987 RLR_TargetLVD 0;
BA_ "GenSigTimeoutValue" SG_ 987 RLR_TargetLVD 0;
BA_ "Remark" SG_ 987 RLR_TargetLVD "";
BA_ "EventCommandSignal" SG_ 987 RLR_TargetRelSpdL 0;
BA_ "GatewayedSignals" SG_ 987 RLR_TargetRelSpdL 0;
BA_ "GenSigInactiveValue" SG_ 987 RLR_TargetRelSpdL 0;
BA_ "GenSigInvalidValue" SG_ 987 RLR_TargetRelSpdL 0;
BA_ "GenSigSendType" SG_ 987 RLR_TargetRelSpdL 1;
BA_ "GenSigStartValue" SG_ 987 RLR_TargetRelSpdL 0;
BA_ "GenSigTimeoutValue" SG_ 987 RLR_TargetRelSpdL 0;
BA_ "Remark" SG_ 987 RLR_TargetRelSpdL "";
BA_ "EventCommandSignal" SG_ 987 RLR_TargetDstL 0;
BA_ "GatewayedSignals" SG_ 987 RLR_TargetDstL 0;
BA_ "GenSigInactiveValue" SG_ 987 RLR_TargetDstL 0;
BA_ "GenSigInvalidValue" SG_ 987 RLR_TargetDstL 0;
BA_ "GenSigSendType" SG_ 987 RLR_TargetDstL 1;
BA_ "GenSigStartValue" SG_ 987 RLR_TargetDstL 0;
BA_ "GenSigTimeoutValue" SG_ 987 RLR_TargetDstL 0;
BA_ "Remark" SG_ 987 RLR_TargetDstL "";
BA_ "EventCommandSignal" SG_ 987 RLR_TargetLatDistL 0;
BA_ "GatewayedSignals" SG_ 987 RLR_TargetLatDistL 0;
BA_ "GenSigInactiveValue" SG_ 987 RLR_TargetLatDistL 0;
BA_ "GenSigInvalidValue" SG_ 987 RLR_TargetLatDistL 0;
BA_ "GenSigSendType" SG_ 987 RLR_TargetLatDistL 1;
BA_ "GenSigStartValue" SG_ 987 RLR_TargetLatDistL 0;
BA_ "GenSigTimeoutValue" SG_ 987 RLR_TargetLatDistL 0;
BA_ "Remark" SG_ 987 RLR_TargetLatDistL "";
BA_ "EventCommandSignal" SG_ 987 RLR_RCTASt 0;
BA_ "GatewayedSignals" SG_ 987 RLR_RCTASt 0;
BA_ "GenSigInactiveValue" SG_ 987 RLR_RCTASt 0;
BA_ "GenSigInvalidValue" SG_ 987 RLR_RCTASt 0;
BA_ "GenSigSendType" SG_ 987 RLR_RCTASt 1;
BA_ "GenSigStartValue" SG_ 987 RLR_RCTASt 0;
BA_ "GenSigTimeoutValue" SG_ 987 RLR_RCTASt 0;
BA_ "Remark" SG_ 987 RLR_RCTASt "";
BA_ "EventCommandSignal" SG_ 987 RLR_RCTAAssistType 0;
BA_ "GatewayedSignals" SG_ 987 RLR_RCTAAssistType 0;
BA_ "GenSigInactiveValue" SG_ 987 RLR_RCTAAssistType 0;
BA_ "GenSigInvalidValue" SG_ 987 RLR_RCTAAssistType 0;
BA_ "GenSigSendType" SG_ 987 RLR_RCTAAssistType 1;
BA_ "GenSigStartValue" SG_ 987 RLR_RCTAAssistType 0;
BA_ "GenSigTimeoutValue" SG_ 987 RLR_RCTAAssistType 0;
BA_ "Remark" SG_ 987 RLR_RCTAAssistType "";
VAL_ 696 KAE_EDK1UnlockBtnPressSt 0 "Undifiend" 1 "Short press" 2 "Twice short press" 3 "Long press"  ;
VAL_ 696 KAE_EDK1LockBtnPressSt 0 "Undifiend" 1 "Short press" 2 "Twice short press" 3 "Long press"  ;
VAL_ 696 KAE_EDK1RESBtnPressSt 0 "Undifiend" 1 "Short press" 2 "Twice short press" 3 "Long press"  ;
VAL_ 696 KAE_EDK1PSD_LBtnPressSt 0 "Undifiend" 1 "Short press" 2 "Twice short press" 3 "Long press"  ;
VAL_ 696 KAE_EDK1PSD_RBtnPressSt 0 "Undifiend" 1 "Short press" 2 "Twice short press" 3 "Long press"  ;
VAL_ 696 KAE_EDK1TrunkBtnPressSt 0 "Undifiend" 1 "Short press" 2 "Twice short press" 3 "Long press"  ;
VAL_ 696 KAE_EDK1PanicBtnPressSt 0 "Undifiend" 1 "Short press" 2 "Twice short press" 3 "Long press"  ;
VAL_ 696 KAE_EDK1User_definedBtnPressSt 0 "Undifiend" 1 "Short press" 2 "Twice short press" 3 "Long press"  ;
VAL_ 696 KAE_EDK2UnlockBtnPressSt 0 "Undifiend" 1 "Short press" 2 "Twice short press" 3 "Long press"  ;
VAL_ 696 KAE_EDK2LockBtnPressSt 0 "Undifiend" 1 "Short press" 2 "Twice short press" 3 "Long press"  ;
VAL_ 696 KAE_EDK2RESBtnPressSt 0 "Undifiend" 1 "Short press" 2 "Twice short press" 3 "Long press"  ;
VAL_ 696 KAE_EDK2PSD_LBtnPressSt 0 "Undifiend" 1 "Short press" 2 "Twice short press" 3 "Long press"  ;
VAL_ 696 KAE_EDK2PSD_RBtnPressSt 0 "Undifiend" 1 "Short press" 2 "Twice short press" 3 "Long press"  ;
VAL_ 696 KAE_EDK2TrunkBtnPressSt 0 "Undifiend" 1 "Short press" 2 "Twice short press" 3 "Long press"  ;
VAL_ 696 KAE_EDK2PanicBtnPressSt 0 "Undifiend" 1 "Short press" 2 "Twice short press" 3 "Long press"  ;
VAL_ 696 KAE_EDK2User_definedBtnPressSt 0 "Undifiend" 1 "Short press" 2 "Twice short press" 3 "Long press"  ;
VAL_ 696 KAE_EDK3UnlockBtnPressSt 0 "Undifiend" 1 "Short press" 2 "Twice short press" 3 "Long press"  ;
VAL_ 696 KAE_EDK3LockBtnPressSt 0 "Undifiend" 1 "Short press" 2 "Twice short press" 3 "Long press"  ;
VAL_ 696 KAE_EDK3RESBtnPressSt 0 "Undifiend" 1 "Short press" 2 "Twice short press" 3 "Long press"  ;
VAL_ 696 KAE_EDK3PSD_LBtnPressSt 0 "Undifiend" 1 "Short press" 2 "Twice short press" 3 "Long press"  ;
VAL_ 696 KAE_EDK3PSD_RBtnPressSt 0 "Undifiend" 1 "Short press" 2 "Twice short press" 3 "Long press"  ;
VAL_ 696 KAE_EDK3TrunkBtnPressSt 0 "Undifiend" 1 "Short press" 2 "Twice short press" 3 "Long press"  ;
VAL_ 696 KAE_EDK3PanicBtnPressSt 0 "Undifiend" 1 "Short press" 2 "Twice short press" 3 "Long press"  ;
VAL_ 696 KAE_EDK3User_definedBtnPressSt 0 "Undifiend" 1 "Short press" 2 "Twice short press" 3 "Long press"  ;
VAL_ 696 KAE_RPADirectionSel 0 "No_ParkSlot" 1 "Cross Left Out" 2 "Parallel Left Out" 3 "Front Out" 4 "Cross Right Out" 5 "Parallel Right Out" 6 "Rear Out" 7 "Reserved"  ;
VAL_ 696 KAE_RPAmode 0 "RPA mode" 1 "AVP mode" 2 "Resered" 3 "Resered"  ;
VAL_ 696 KAE_RPADeviceSt 0 "RD_Inactive" 1 "RD_Ready" 2 "RD_Active" 3 "Reserved" 4 "Reserved" 5 "Reserved" 6 "Reserved" 7 "Reserved"  ;
VAL_ 696 KAE_RPACheckReq 0 "Not active" 1 "Requst"  ;
VAL_ 696 KAE_RPAKeyPstSt 0 "In the Car" 1 "Range Too Close" 2 "Normally Range" 3 "Range Too Far"  ;
VAL_ 696 KAE_RPADeviceFailReason 0 "RD_NoFailure" 1 "RD_Offline" 2 "RD_OutOfRange" 3 "RD_LowBatt" 4 "Other Failures" 5 "RD_UserExitParkingMode" 6 "CameraFail" 7 "Charg plug locked" 8 "Remote start fail" 9 "Reserved" 10 "Reserved" 11 "Reserved" 12 "Reserved" 13 "Reserved" 14 "Reserved" 15 "Reserved"  ;
VAL_ 696 KAE_RPABtnSt 0 "Not Pressed" 1 "Pressed"  ;
VAL_ 696 KAE_ForRPAFailReason 0 "SBM_NoFailure" 1 "SBM&RD_Offline" 2 "Not used" 3 "SBM&RPA_Offline" 4 "Other Failures" 5 "Reserved" 6 "Reserved" 7 "Reserved" 8 "Reserved" 9 "Reserved" 10 "Reserved" 11 "Reserved" 12 "Reserved" 13 "Reserved" 14 "Reserved" 15 "Reserved"  ;
VAL_ 696 KAE_RPABtnStVD 0 "Invalid" 1 "Valid"  ;
VAL_ 696 KAE_RPACancelBtnSt 0 "Not Pressed" 1 "Pressed"  ;
VAL_ 696 KAE_RPACancelBtnStVD 0 "Invalid" 1 "Valid"  ;
VAL_ 696 KAE_HAVPCancelParking 0 "No comment" 1 "Cancel"  ;
VAL_ 696 KAE_HAVPDisclaimerAgree 0 "No comment" 1 "Agree" 2 "Disagree" 3 "Reserved"  ;
VAL_ 696 KAE_HAVPUWBZone 0 "Not used" 1 "FL zone" 2 "Ahead zone" 3 "FR zone" 4 "Ahead right side zone" 5 "Back right side zone" 6 "RR zone" 7 "back zone" 8 "RL zone" 9 "Back left side zone" 10 "Ahead left side zone"  ;
VAL_ 696 KAE_UnlockDoorReq 0 "No request" 1 "Unlock"  ;
VAL_ 696 KAE_UnlockDoorReqVD 0 "Invalid" 1 "Valid"  ;
VAL_ 696 KAE_LockDoorReq 0 "No request" 1 "Lock"  ;
VAL_ 696 KAE_LockDoorReqVD 0 "Invalid" 1 "Valid"  ;
VAL_ 696 KAE_WindowsCloseReq 0 "No request" 1 "Close the windows"  ;
VAL_ 696 KAE_WindowsCloseReqVD 0 "Invalid" 1 "Valid"  ;
VAL_ 696 KAE_WindowsOpenReq 0 "No request" 1 "Open the windows"  ;
VAL_ 696 KAE_WindowsOpenReqVD 0 "Invalid" 1 "Valid"  ;
VAL_ 696 KAE_TrunkUnlockReq 0 "No request" 1 "Trunk unlock"  ;
VAL_ 696 KAE_TrunkUnlockReqVD 0 "Invalid" 1 "Valid"  ;
VAL_ 696 KAE_HoodUnlockReq 0 "No request" 1 "Hood unlock"  ;
VAL_ 696 KAE_HoodUnlockReqVD 0 "Invalid" 1 "Valid"  ;
VAL_ 696 KAE_PLGMOpenReq 0 "No request" 1 "PLGM open"  ;
VAL_ 696 KAE_PLGMOpenReqVD 0 "Invalid" 1 "valid"  ;
VAL_ 696 KAE_PLGMCloseReq 0 "No request" 1 "PLGM close"  ;
VAL_ 696 KAE_PLGMCloseReqVD 0 "Invalid" 1 "valid"  ;
VAL_ 696 KAE_SunRoofOpenReq 0 "No request" 1 "Sun roof open"  ;
VAL_ 696 KAE_SunRoofOpenReqVD 0 "Invalid" 1 "Valid"  ;
VAL_ 696 KAE_SunRoofCloseReq 0 "No request" 1 "Sun roof close"  ;
VAL_ 696 KAE_SunRoofCloseReqVD 0 "Invalid" 1 "Valid"  ;
VAL_ 696 KAE_PAAReq 0 "No request" 1 "RPA request" 2 "HPA request" 3 "EDK request"  ;
VAL_ 696 KAE_PAAReqVd 0 "Invalid" 1 "Valid"  ;
VAL_ 696 KAE_EDK1UnlockBtnSt 0 "Not active" 1 "Active"  ;
VAL_ 696 KAE_EDK1LockBtnSt 0 "Not active" 1 "Active"  ;
VAL_ 696 KAE_EDK1RESBtnSt 0 "Not active" 1 "Active"  ;
VAL_ 696 KAE_EDK1PSD_LBtnSt 0 "Not active" 1 "Active"  ;
VAL_ 696 KAE_EDK1PSD_RBtnSt 0 "Not active" 1 "Active"  ;
VAL_ 696 KAE_EDK1TrunkBtnSt 0 "Not active" 1 "Active"  ;
VAL_ 696 KAE_EDK1PanicBtnSt 0 "Not active" 1 "Active"  ;
VAL_ 696 KAE_EDK1User_definedBtnSt 0 "Not active" 1 "Active"  ;
VAL_ 696 KAE_EDK2UnlockBtnSt 0 "Not active" 1 "Active"  ;
VAL_ 696 KAE_EDK2LockBtnSt 0 "Not active" 1 "Active"  ;
VAL_ 696 KAE_EDK2RESBtnSt 0 "Not active" 1 "Active"  ;
VAL_ 696 KAE_EDK2PSD_LBtnSt 0 "Not active" 1 "Active"  ;
VAL_ 696 KAE_EDK2PSD_RBtnSt 0 "Not active" 1 "Active"  ;
VAL_ 696 KAE_EDK2TrunkBtnSt 0 "Not active" 1 "Active"  ;
VAL_ 696 KAE_EDK2PanicBtnSt 0 "Not active" 1 "Active"  ;
VAL_ 696 KAE_EDK2User_definedBtnSt 0 "Not active" 1 "Active"  ;
VAL_ 696 KAE_EDK3UnlockBtnSt 0 "Not active" 1 "Active"  ;
VAL_ 696 KAE_EDK3LockBtnSt 0 "Not active" 1 "Active"  ;
VAL_ 696 KAE_EDK3RESBtnSt 0 "Not active" 1 "Active"  ;
VAL_ 696 KAE_EDK3PSD_LBtnSt 0 "Not active" 1 "Active"  ;
VAL_ 696 KAE_EDK3PSD_RBtnSt 0 "Not active" 1 "Active"  ;
VAL_ 696 KAE_EDK3TrunkBtnSt 0 "Not active" 1 "Active"  ;
VAL_ 696 KAE_EDK3PanicBtnSt 0 "Not active" 1 "Active"  ;
VAL_ 696 KAE_EDK3User_definedBtnSt 0 "Not active" 1 "Active"  ;
VAL_ 1294 ADC_NMCBV 0 "Node has not woken up the    network(passive wakeup);" 1 "Node has woken up the network(active wakeup)" 0 "NM PDU contains no Partial Network request information" 1 "NM PDU contains Partial Network request information"  ;
VAL_ 1294 ADC_NMWakeupOrigin 1 "NM Message wakeup              2"  ;
VAL_ 1294 ADC_PNCInformation0 0 "No request" 1 "Request" 0 "No request" 1 "Request" 0 "No request" 1 "Request" 0 "No request" 1 "Request" 1 "Request" 0 "No request" 1 "Request" 0 "No request" 1 "Request"  ;
VAL_ 1294 ADC_PNCInformation1 0 "No request" 1 "Request" 0 "No request" 1 "Request"  ;
VAL_ 1343 RRR_NMCBV 0 "Node has not woken up the    network(passive wakeup);" 1 "Node has woken up the network(active wakeup)" 0 "NM PDU contains no Partial Network request information" 1 "NM PDU contains Partial Network request information"  ;
VAL_ 1343 RRR_PNCInformation0 0 "No request" 1 "Request" 0 "No request" 1 "Request" 0 "No request" 1 "Request" 0 "No request" 1 "Request" 1 "Request" 0 "No request" 1 "Request" 0 "No request" 1 "Request"  ;
VAL_ 1343 RRR_PNCInformation1 0 "No request" 1 "Request" 0 "No request" 1 "Request"  ;
VAL_ 1354 RLR_NMCBV 0 "Node has not woken up the    network(passive wakeup);" 1 "Node has woken up the network(active wakeup)" 0 "NM PDU contains no Partial Network request information" 1 "NM PDU contains Partial Network request information"  ;
VAL_ 1354 RLR_PNCInformation0 0 "No request" 1 "Request" 0 "No request" 1 "Request" 0 "No request" 1 "Request" 0 "No request" 1 "Request" 1 "Request" 0 "No request" 1 "Request" 0 "No request" 1 "Request"  ;
VAL_ 1354 RLR_PNCInformation1 0 "No request" 1 "Request" 0 "No request" 1 "Request"  ;
VAL_ 932 RRR_MRRSt 0 "ON" 1 "Sensor Covered" 2 "System Error" 3 "Temporary Error" 4 "initializing"  ;
VAL_ 932 RRR_ExMirLedWarnR 0 "OFF" 1 "Continue ON（Warning level 1）" 2 "Flashing（Warning level 2）" 3 "Reserved"  ;
VAL_ 932 RRR_LCASt 0 "OFF" 1 "Passive" 2 "Active" 3 "Failure"  ;
VAL_ 932 RRR_LCAWarnRight 0 "No warning" 1 "Warning level 1" 2 "Warning level 2" 3 "Not used"  ;
VAL_ 932 RRR_ClusterLamp 0 "OFF" 1 "Continue ON(Yellow)" 2 "Continue ON(Green)"  ;
VAL_ 932 RRR_DOWWarnR 0 "OFF" 1 "Warning level 1" 2 "Warning level 2" 3 "Reserved"  ;
VAL_ 932 RRR_DOWSt 0 "OFF" 1 "Passive" 2 "Active" 3 "Failure"  ;
VAL_ 932 RRR_AudioWarnFR 0 "No Warning" 1 "Warning"  ;
VAL_ 932 RRR_AudioWarnRR 0 "No Warning" 1 "Warning"  ;
VAL_ 932 RRR_IALWarnFR 0 "No Warning" 1 "Warning level 1" 2 "Warning level 2" 3 "Reserved"  ;
VAL_ 932 RRR_IALWarnRR 0 "No Warning" 1 "Warning level 1" 2 "Warning level 2" 3 "Reserved"  ;
VAL_ 932 RRR_RCTASt 0 "OFF" 1 "Passive" 2 "Active" 3 "Failure"  ;
VAL_ 932 RRR_RCTAWarnRight 0 "No warning" 1 "Warning level 1" 2 "Warning level 2" 3 "Not used"  ;
VAL_ 932 RRR_RCWSt 0 "Off" 1 "Passive/On/Inactive" 2 "Active" 3 "Failure"  ;
VAL_ 932 RRR_RCWWarn 0 "No warning" 1 "Warning level 1" 2 "Warning level 2" 3 "Not used"  ;
VAL_ 932 RRR_RCTBBrkReq 0 "No request" 1 "Request"  ;
VAL_ 932 RRR_RCTBBrkgVD 0 "Invalid" 1 "Valid"  ;
VAL_ 932 RRR_TargetRVD 0 "Target Invalid" 1 "Target Valid" 2 "No Target" 3 "reserved"  ;
VAL_ 932 RRR_RCTAAssistType 0 "OFF" 1 "fail" 2 "Warning" 3 "brake and Warning"  ;
VAL_ 987 RLR_MRRSt 0 "ON" 1 "Sensor Covered" 2 "System Error" 3 "Temporary Error" 4 "initializing"  ;
VAL_ 987 RLR_ExMirLedWarnL 0 "OFF" 1 "Continue ON（Warning level 1）" 2 "Flashing（Warning level 2）" 3 "Reserved"  ;
VAL_ 987 RLR_LCASt 0 "OFF" 1 "Passive" 2 "Active" 3 "Failure"  ;
VAL_ 987 RLR_LCAWarnLeft 0 "No warning" 1 "Warning level 1" 2 "Warning level 2" 3 "Not used"  ;
VAL_ 987 RLR_ClusterLamp 0 "OFF" 1 "Continue ON(Yellow)" 2 "Continue ON(Green)"  ;
VAL_ 987 RLR_DOWWarnL 0 "OFF" 1 "Warning level 1" 2 "Warning level 2" 3 "Reserved"  ;
VAL_ 987 RLR_DOWSt 0 "OFF" 1 "Passive" 2 "Active" 3 "Failure"  ;
VAL_ 987 RLR_AudioWarnFL 0 "No Warning" 1 "Warning"  ;
VAL_ 987 RLR_AudioWarnRL 0 "No Warning" 1 "Warning"  ;
VAL_ 987 RLR_IALWarnFL 0 "No Warning" 1 "Warning level 1" 2 "Warning level 2" 3 "Reserved"  ;
VAL_ 987 RLR_IALWarnRL 0 "No Warning" 1 "Warning level 1" 2 "Warning level 2" 3 "Reserved"  ;
VAL_ 987 RLR_RCTAWarnLeft 0 "No warning" 1 "Warning level 1" 2 "Warning level 2" 3 "Not used"  ;
VAL_ 987 RLR_RCWSt 0 "Off" 1 "Passive/On/Inactive" 2 "Active" 3 "Failure"  ;
VAL_ 987 RLR_RCWWarn 0 "No warning" 1 "Warning level 1" 2 "Warning level 2" 3 "Not used"  ;
VAL_ 987 RLR_TargetLVD 0 "Target Invalid" 1 "Target Valid" 2 "No Target" 3 "reserved"  ;
VAL_ 987 RLR_RCTASt 0 "OFF" 1 "Passive" 2 "Active" 3 "Failure"  ;
VAL_ 987 RLR_RCTAAssistType 0 "OFF" 1 "fail" 2 "Warning" 3 "brake and Warning"  ;
